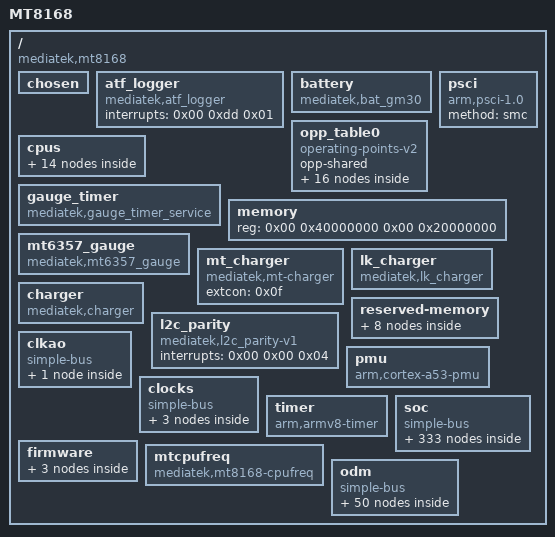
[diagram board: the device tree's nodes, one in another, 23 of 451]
/dts-v1/;

/ {
	model = "MT8168";
	compatible = "mediatek,mt8168";
	interrupt-parent = <0x01>;
	#address-cells = <0x02>;
	#size-cells = <0x02>;
	version = "hvt";

	chosen {
		bootargs = "console=tty0 vmalloc=496M androidboot.hardware=mt8168 firmware_class.path=/vendor/firmware loop.max_part=7";
		phandle = <0x8c>;
	};

	atf_logger {
		compatible = "mediatek,atf_logger";
		interrupts = <0x00 0xdd 0x01>;
	};

	battery {
		compatible = "mediatek,bat_gm30";
		DIFFERENCE_FULLOCV_ITH = <0x12c>;
		SHUTDOWN_1_TIME = <0x05>;
		KEEP_100_PERCENT = <0x01>;
		R_FG_VALUE = <0x0a>;
		EMBEDDED_SEL = <0x00>;
		PMIC_SHUTDOWN_CURRENT = <0x14>;
		FG_METER_RESISTANCE = <0x4b>;
		CAR_TUNE_VALUE = <0x61>;
		PMIC_MIN_VOL = <0x84d0>;
		POWERON_SYSTEM_IBOOT = <0x1f4>;
		SHUTDOWN_GAUGE0_VOLTAGE = <0x84d0>;
		TEMPERATURE_T0 = <0x32>;
		TEMPERATURE_T1 = <0x19>;
		TEMPERATURE_T2 = <0x0a>;
		TEMPERATURE_T3 = <0x00>;
		TEMPERATURE_T4 = <0xfffffff6>;
		g_FG_PSEUDO100_T0 = <0x64>;
		g_FG_PSEUDO100_T1 = <0x64>;
		g_FG_PSEUDO100_T2 = <0x64>;
		g_FG_PSEUDO100_T3 = <0x64>;
		g_FG_PSEUDO100_T4 = <0x64>;
		Q_MAX_SYS_VOLTAGE_BAT0 = <0xd16>;
		Q_MAX_SYS_VOLTAGE_BAT1 = <0xd16>;
		Q_MAX_SYS_VOLTAGE_BAT2 = <0xd16>;
		Q_MAX_SYS_VOLTAGE_BAT3 = <0xd16>;
		battery0_profile_t0_num = <0x64>;
		battery0_profile_t0 = <0x00 0xa584 0x2bc 0x1d4 0xa513 0x2ba 0x3a9 0xa4a3 0x2be 0x57d 0xa437 0x2c1 0x752 0xa3ca 0x2c3 0x926 0xa360 0x2c4 0xafa 0xa2f6 0x2c5 0xccf 0xa28e 0x2c7 0xea3 0xa227 0x2ca 0x1078 0xa1c1 0x2ce 0x124c 0xa15c 0x2d0 0x1421 0xa0f7 0x2cd 0x15f5 0xa095 0x2d4 0x17c9 0xa033 0x2d4 0x199e 0x9fcd 0x2c8 0x1b72 0x9f6f 0x2da 0x1d47 0x9f11 0x2da 0x1f1b 0x9eb6 0x2da 0x20ef 0x9e55 0x2da 0x22c4 0x9dfe 0x2e2 0x2498 0x9da7 0x2e4 0x266d 0x9d52 0x2e9 0x2841 0x9cff 0x2f2 0x2a16 0x9cac 0x2f5 0x2bea 0x9c5c 0x2f5 0x2dbe 0x9c0e 0x2f9 0x2f93 0x9bc2 0x301 0x3167 0x9b77 0x308 0x333c 0x9b2d 0x30e 0x3510 0x9ae4 0x317 0x36e4 0x9a9d 0x31f 0x38b9 0x9a58 0x330 0x3a8d 0x9a13 0x33e 0x3c62 0x99ce 0x352 0x3e36 0x9985 0x35f 0x400b 0x9939 0x377 0x41df 0x98db 0x36c 0x43b3 0x9862 0x336 0x4588 0x97e7 0x2fa 0x475c 0x9781 0x2df 0x4931 0x9732 0x2d8 0x4b05 0x96f2 0x2d0 0x4cd9 0x96b8 0x2cd 0x4eae 0x9683 0x2cb 0x5082 0x9651 0x2cc 0x5257 0x9622 0x2ce 0x542b 0x95f4 0x2d0 0x55ff 0x95c9 0x2d0 0x57d4 0x95a6 0x2cc 0x59a8 0x9580 0x2d0 0x5b7d 0x9558 0x2d0 0x5d51 0x9533 0x2d3 0x5f26 0x9510 0x2d7 0x60fa 0x94ed 0x2d8 0x62ce 0x94cb 0x2da 0x64a3 0x94aa 0x2db 0x6677 0x948c 0x2df 0x684c 0x946c 0x2e1 0x6a20 0x9451 0x2ec 0x6bf4 0x9434 0x2ee 0x6dc9 0x941c 0x2f5 0x6f9d 0x9402 0x2f8 0x7172 0x93ea 0x300 0x7346 0x93d1 0x304 0x751b 0x93b9 0x310 0x76ef 0x939e 0x317 0x78c3 0x9380 0x313 0x7a98 0x935b 0x301 0x7c6c 0x9312 0x2c9 0x7e41 0x92cd 0x2c9 0x8015 0x92a0 0x2cd 0x81e9 0x927c 0x2d2 0x83be 0x9258 0x2d8 0x8592 0x9231 0x2d5 0x8767 0x9209 0x2cf 0x893b 0x91e4 0x2d0 0x8b0f 0x91c3 0x2d6 0x8ce4 0x91a3 0x2dc 0x8eb8 0x9180 0x2df 0x908d 0x9155 0x2df 0x9261 0x9120 0x2de 0x9436 0x90e2 0x2d8 0x960a 0x90a8 0x2db 0x97de 0x9075 0x2e6 0x99b3 0x9033 0x2e9 0x9b87 0x8fe3 0x2db 0x9d5c 0x8fb8 0x2d9 0x9f30 0x8fa5 0x2e3 0xa104 0x8f96 0x2eb 0xa2d9 0x8f85 0x2fb 0xa4ad 0x8f70 0x30f 0xa682 0x8f50 0x324 0xa856 0x8f10 0x336 0xaa2b 0x8e6c 0x330 0xabff 0x8d1a 0x327 0xadd3 0x8b48 0x340 0xafa8 0x88f7 0x36f 0xb17c 0x85c2 0x3a0 0xb351 0x80a8 0x433 0xb525 0x72fd 0xe09>;
		battery0_profile_t1_num = <0x64>;
		battery0_profile_t1 = <0x00 0xa5c6 0x37a 0x1d4 0xa552 0x37c 0x3a9 0xa4e2 0x385 0x57d 0xa473 0x384 0x752 0xa408 0x38a 0x926 0xa39d 0x38d 0xafa 0xa334 0x390 0xccf 0xa2cc 0x392 0xea3 0xa265 0x395 0x1078 0xa1ff 0x399 0x124c 0xa19a 0x39c 0x1421 0xa136 0x3a0 0x15f5 0xa0d3 0x3a0 0x17c9 0xa071 0x3a3 0x199e 0xa010 0x3aa 0x1b72 0x9fb1 0x3ad 0x1d47 0x9f57 0x3bb 0x1f1b 0x9f05 0x3c9 0x20ef 0x9eb2 0x3ce 0x22c4 0x9e56 0x3cd 0x2498 0x9df8 0x3d2 0x266d 0x9d99 0x3d9 0x2841 0x9d3b 0x3e0 0x2a16 0x9ce2 0x3e7 0x2bea 0x9c8d 0x3f2 0x2dbe 0x9c3c 0x3ff 0x2f93 0x9bf1 0x40b 0x3167 0x9bad 0x41c 0x333c 0x9b6c 0x431 0x3510 0x9b29 0x43f 0x36e4 0x9ae2 0x44e 0x38b9 0x9a9b 0x463 0x3a8d 0x9a53 0x474 0x3c62 0x9a08 0x482 0x3e36 0x99ba 0x490 0x400b 0x9966 0x48e 0x41df 0x9908 0x47d 0x43b3 0x989c 0x44d 0x4588 0x982a 0x40d 0x475c 0x97c2 0x3d8 0x4931 0x976b 0x3b3 0x4b05 0x9721 0x39d 0x4cd9 0x96e2 0x395 0x4eae 0x96aa 0x392 0x5082 0x9676 0x391 0x5257 0x9645 0x390 0x542b 0x9617 0x38e 0x55ff 0x95ec 0x38e 0x57d4 0x95c1 0x38e 0x59a8 0x959a 0x392 0x5b7d 0x9571 0x393 0x5d51 0x954d 0x397 0x5f26 0x952a 0x39a 0x60fa 0x9508 0x39f 0x62ce 0x94e7 0x3a2 0x64a3 0x94c7 0x3a5 0x6677 0x94aa 0x3ac 0x684c 0x948e 0x3b4 0x6a20 0x9472 0x3ba 0x6bf4 0x9458 0x3bf 0x6dc9 0x943e 0x3c6 0x6f9d 0x9426 0x3c9 0x7172 0x940e 0x3cf 0x7346 0x93f8 0x3d4 0x751b 0x93e2 0x3e0 0x76ef 0x93ca 0x3de 0x78c3 0x93b2 0x3e0 0x7a98 0x9396 0x3d9 0x7c6c 0x9377 0x3cc 0x7e41 0x9357 0x3be 0x8015 0x9337 0x3b3 0x81e9 0x9317 0x3ac 0x83be 0x92f4 0x3a6 0x8592 0x92cf 0x3a2 0x8767 0x92a8 0x3a0 0x893b 0x9282 0x39e 0x8b0f 0x9262 0x3a4 0x8ce4 0x9243 0x3ad 0x8eb8 0x9220 0x3b4 0x908d 0x91f5 0x3b6 0x9261 0x91bb 0x3b1 0x9436 0x917c 0x3b1 0x960a 0x9146 0x3bb 0x97de 0x910f 0x3c5 0x99b3 0x90cb 0x3cb 0x9b87 0x907a 0x3cb 0x9d5c 0x9042 0x3ce 0x9f30 0x902a 0x3dd 0xa104 0x9019 0x3ee 0xa2d9 0x9008 0x403 0xa4ad 0x8ff2 0x424 0xa682 0x8fd2 0x44d 0xa856 0x8f9b 0x481 0xaa2b 0x8f18 0x4a6 0xabff 0x8dcd 0x498 0xadd3 0x8bf0 0x4e3 0xafa8 0x8980 0x561 0xb17c 0x861b 0x63b 0xb351 0x8085 0x88a 0xb525 0x780a 0x1aa9>;
		battery0_profile_t2_num = <0x64>;
		battery0_profile_t2 = <0x00 0xa5b8 0x5fa 0x1d4 0xa542 0x5f5 0x3a9 0xa4d1 0x5f9 0x57d 0xa463 0x5fc 0x752 0xa3f9 0x5fe 0x926 0xa38e 0x5ff 0xafa 0xa326 0x604 0xccf 0xa2bf 0x607 0xea3 0xa258 0x60a 0x1078 0xa1f2 0x60d 0x124c 0xa18c 0x610 0x1421 0xa129 0x61b 0x15f5 0xa0c5 0x623 0x17c9 0xa063 0x627 0x199e 0xa005 0x632 0x1b72 0x9fa9 0x63c 0x1d47 0x9f55 0x647 0x1f1b 0x9f05 0x65a 0x20ef 0x9eab 0x664 0x22c4 0x9e49 0x669 0x2498 0x9de5 0x679 0x266d 0x9d82 0x685 0x2841 0x9d21 0x68d 0x2a16 0x9cc4 0x698 0x2bea 0x9c6d 0x6a5 0x2dbe 0x9c1a 0x6b3 0x2f93 0x9bcb 0x6c1 0x3167 0x9b81 0x6cf 0x333c 0x9b3c 0x6e3 0x3510 0x9afa 0x6f7 0x36e4 0x9ab9 0x709 0x38b9 0x9a75 0x712 0x3a8d 0x9a27 0x710 0x3c62 0x99d7 0x70d 0x3e36 0x997e 0x6f4 0x400b 0x991f 0x6c8 0x41df 0x98ba 0x692 0x43b3 0x9854 0x653 0x4588 0x97f4 0x622 0x475c 0x979c 0x5fa 0x4931 0x974e 0x5d8 0x4b05 0x970a 0x5c2 0x4cd9 0x96cc 0x5b6 0x4eae 0x9695 0x5b0 0x5082 0x9660 0x5ae 0x5257 0x9630 0x5b1 0x542b 0x9602 0x5b1 0x55ff 0x95d5 0x5b2 0x57d4 0x95ad 0x5bb 0x59a8 0x9585 0x5bc 0x5b7d 0x955f 0x5c6 0x5d51 0x953b 0x5d0 0x5f26 0x9518 0x5d7 0x60fa 0x94f6 0x5d9 0x62ce 0x94d6 0x5e2 0x64a3 0x94b7 0x5ee 0x6677 0x9499 0x5f7 0x684c 0x947e 0x600 0x6a20 0x9464 0x609 0x6bf4 0x9449 0x610 0x6dc9 0x942f 0x617 0x6f9d 0x9418 0x621 0x7172 0x9402 0x62d 0x7346 0x93ec 0x636 0x751b 0x93d7 0x638 0x76ef 0x93c5 0x641 0x78c3 0x93b3 0x64b 0x7a98 0x93a2 0x64e 0x7c6c 0x9391 0x651 0x7e41 0x9381 0x656 0x8015 0x936f 0x65a 0x81e9 0x9358 0x65a 0x83be 0x933b 0x656 0x8592 0x931a 0x651 0x8767 0x92f8 0x64d 0x893b 0x92d4 0x64c 0x8b0f 0x92b2 0x654 0x8ce4 0x9290 0x660 0x8eb8 0x9269 0x66e 0x908d 0x923b 0x686 0x9261 0x91fe 0x68b 0x9436 0x91c0 0x698 0x960a 0x9187 0x6ae 0x97de 0x914d 0x6cd 0x99b3 0x9105 0x6e5 0x9b87 0x90b1 0x6f9 0x9d5c 0x9075 0x715 0x9f30 0x9054 0x741 0xa104 0x903c 0x77e 0xa2d9 0x9024 0x7cc 0xa4ad 0x9008 0x837 0xa682 0x8fe2 0x8cc 0xa856 0x8fa5 0x9a8 0xaa2b 0x8f1c 0xacc 0xabff 0x8dcd 0xc1f 0xadd3 0x8bc7 0xf20 0xafa8 0x891a 0x16d3 0xb17c 0x8568 0x244e 0xb351 0x84c7 0x26a5 0xb525 0x84c7 0x26a5>;
		battery0_profile_t3_num = <0x64>;
		battery0_profile_t3 = <0x00 0xa5fa 0x8de 0x1d4 0xa57b 0x8d9 0x3a9 0xa506 0x8db 0x57d 0xa495 0x8e6 0x752 0xa421 0x84d 0x926 0xa3b4 0x8be 0xafa 0xa34a 0x903 0xccf 0xa2e1 0x908 0xea3 0xa276 0x910 0x1078 0xa20b 0x90e 0x124c 0xa1a6 0x913 0x1421 0xa141 0x92a 0x15f5 0xa0dd 0x935 0x17c9 0xa079 0x93e 0x199e 0xa01a 0x93e 0x1b72 0x9fc2 0x94f 0x1d47 0x9f72 0x967 0x1f1b 0x9f21 0x981 0x20ef 0x9ec3 0x985 0x22c4 0x9e5c 0x9a9 0x2498 0x9df1 0x9b0 0x266d 0x9d87 0x9bd 0x2841 0x9d1f 0x9c7 0x2a16 0x9cbc 0x9c9 0x2bea 0x9c60 0x9cf 0x2dbe 0x9c0a 0x9db 0x2f93 0x9bba 0x9e8 0x3167 0x9b6e 0x9f0 0x333c 0x9b22 0x9f6 0x3510 0x9ad9 0xa00 0x36e4 0x9a90 0xa03 0x38b9 0x9a47 0xa06 0x3a8d 0x99fa 0x9e7 0x3c62 0x99a2 0x9d3 0x3e36 0x9943 0x9ab 0x400b 0x98e5 0x97c 0x41df 0x9886 0x944 0x43b3 0x982b 0x90d 0x4588 0x97d5 0x8f8 0x475c 0x9787 0x8dd 0x4931 0x973e 0x8ca 0x4b05 0x96fc 0x8bc 0x4cd9 0x96bf 0x8b6 0x4eae 0x9688 0x8b6 0x5082 0x9654 0x8a2 0x5257 0x9623 0x89c 0x542b 0x95f5 0x8c3 0x55ff 0x95c9 0x8c9 0x57d4 0x95a0 0x8d5 0x59a8 0x9576 0x8dd 0x5b7d 0x9550 0x8e9 0x5d51 0x952d 0x8fc 0x5f26 0x950c 0x8e9 0x60fa 0x94ec 0x915 0x62ce 0x94c9 0x918 0x64a3 0x94aa 0x92f 0x6677 0x948b 0x93d 0x684c 0x946f 0x949 0x6a20 0x9455 0x95d 0x6bf4 0x943c 0x96c 0x6dc9 0x9423 0x973 0x6f9d 0x940c 0x980 0x7172 0x93f7 0x992 0x7346 0x93e4 0x9a0 0x751b 0x93d2 0x9ac 0x76ef 0x93c2 0x9ba 0x78c3 0x93b5 0x9c5 0x7a98 0x93aa 0x9bf 0x7c6c 0x9399 0x9e2 0x7e41 0x938a 0x9e9 0x8015 0x937a 0x9f7 0x81e9 0x9364 0xa03 0x83be 0x934e 0xa03 0x8592 0x9333 0xa18 0x8767 0x9318 0xa1f 0x893b 0x92f8 0xa36 0x8b0f 0x92d4 0xa4a 0x8ce4 0x92ae 0xa68 0x8eb8 0x9282 0xa8c 0x908d 0x924d 0xaa4 0x9261 0x9214 0xac8 0x9436 0x91d9 0xae4 0x960a 0x91a0 0xaf6 0x97de 0x9161 0xb45 0x99b3 0x9113 0xb9d 0x9b87 0x90bf 0xbde 0x9d5c 0x9088 0xc0d 0x9f30 0x9066 0xcaf 0xa104 0x9046 0xd1f 0xa2d9 0x9028 0xe4c 0xa4ad 0x9002 0xfb7 0xa682 0x8fc9 0x11de 0xa856 0x8f6a 0x1574 0xaa2b 0x8ea2 0x1c71 0xabff 0x8d27 0x2ec7 0xadd3 0x8afa 0x4e8b 0xafa8 0x8806 0x5626 0xb17c 0x83c8 0x4b8c 0xb351 0x803d 0x42b1 0xb525 0x803d 0x42b1>;
		battery0_profile_t4_num = <0x64>;
		battery0_profile_t4 = <0x00 0xa602 0x1504 0x1d4 0xa576 0x14ff 0x3a9 0xa4fb 0x1520 0x57d 0xa488 0x1522 0x752 0xa41a 0x1528 0x926 0xa3ad 0x1523 0xafa 0xa343 0x1521 0xccf 0xa2da 0x151f 0xea3 0xa271 0x151d 0x1078 0xa20a 0x1519 0x124c 0xa1a5 0x1512 0x1421 0xa13f 0x150d 0x15f5 0xa0d9 0x1501 0x17c9 0xa077 0x14f8 0x199e 0xa019 0x14fc 0x1b72 0x9fc0 0x14f8 0x1d47 0x9f6c 0x1501 0x1f1b 0x9f14 0x150f 0x20ef 0x9eb2 0x1508 0x22c4 0x9e45 0x14f9 0x2498 0x9dd2 0x14ee 0x266d 0x9d5e 0x14dc 0x2841 0x9cf0 0x1427 0x2a16 0x9c7e 0x13f0 0x2bea 0x9c15 0x144c 0x2dbe 0x9bb8 0x1459 0x2f93 0x9b5f 0x1445 0x3167 0x9b09 0x1444 0x333c 0x9ab5 0x13e6 0x3510 0x9a65 0x142e 0x36e4 0x9a11 0x141b 0x38b9 0x99c2 0x1427 0x3a8d 0x9976 0x13c7 0x3c62 0x9929 0x13d6 0x3e36 0x98d8 0x13ef 0x400b 0x988b 0x13bb 0x41df 0x983f 0x13b8 0x43b3 0x97f4 0x13a7 0x4588 0x97ad 0x13bb 0x475c 0x9769 0x13cb 0x4931 0x9729 0x13b1 0x4b05 0x96ee 0x13b1 0x4cd9 0x96b4 0x13e0 0x4eae 0x967e 0x13f4 0x5082 0x964a 0x13e6 0x5257 0x9617 0x138c 0x542b 0x95eb 0x1400 0x55ff 0x95bd 0x1436 0x57d4 0x9591 0x13f4 0x59a8 0x9569 0x144a 0x5b7d 0x9540 0x147e 0x5d51 0x951c 0x1427 0x5f26 0x94f8 0x1426 0x60fa 0x94d6 0x1490 0x62ce 0x94b5 0x14e1 0x64a3 0x9495 0x150c 0x6677 0x9476 0x1533 0x684c 0x945a 0x155b 0x6a20 0x943f 0x1545 0x6bf4 0x9426 0x1513 0x6dc9 0x940f 0x15c2 0x6f9d 0x93f9 0x15db 0x7172 0x93e6 0x1620 0x7346 0x93d6 0x158e 0x751b 0x93c6 0x15f5 0x76ef 0x93b8 0x1682 0x78c3 0x93a9 0x16e4 0x7a98 0x9398 0x16f4 0x7c6c 0x9387 0x171b 0x7e41 0x9376 0x175f 0x8015 0x9365 0x17ba 0x81e9 0x9351 0x1803 0x83be 0x933a 0x183e 0x8592 0x9321 0x188b 0x8767 0x9306 0x18ed 0x893b 0x92e6 0x1969 0x8b0f 0x92c5 0x19c2 0x8ce4 0x929f 0x19ed 0x8eb8 0x9275 0x1aac 0x908d 0x924b 0x1b0c 0x9261 0x9217 0x1bc2 0x9436 0x91e1 0x1c6c 0x960a 0x91a7 0x1d34 0x97de 0x9168 0x1e20 0x99b3 0x9127 0x1f08 0x9b87 0x90e6 0x2064 0x9d5c 0x90ac 0x2216 0x9f30 0x9079 0x2419 0xa104 0x904c 0x267a 0xa2d9 0x901e 0x2a27 0xa4ad 0x8fea 0x3065 0xa682 0x8faa 0x3a91 0xa856 0x8f4f 0x4cb5 0xaa2b 0x8ed4 0x5c32 0xabff 0x8e6f 0x3e70 0xadd3 0x8c3f 0x6a79 0xafa8 0x84d0 0x57e4 0xb17c 0x84d0 0x57e4 0xb351 0x84d0 0x57e4 0xb525 0x84d0 0x57e4>;
		io-channels = <0x02 0x02>;
		io-channel-names = "bat_id_channel";
		id_volt_max = <0x5c8>;
		id_volt_min = <0x2bc>;
		MIN_BATTERY_TEMP = <0xfffffff6>;
		total_battery_number = <0x02>;
		bat_id_volt_thres = <0x3e8 0x4b0 0xffffffff>;
		battery0_profile_name = "ATL";
		battery0_profile_t0_col = <0x03>;
		battery0_profile_t1_col = <0x03>;
		battery0_profile_t2_col = <0x03>;
		battery0_profile_t3_col = <0x03>;
		battery0_profile_t4_col = <0x03>;
		battery1_profile_name = "Lishen";
		battery1_profile_t0_num = <0x64>;
		battery1_profile_t0_col = <0x03>;
		battery1_profile_t0 = <0x00 0xa59b 0x28a 0x1cf 0xa52e 0x28a 0x39f 0xa4c1 0x28e 0x56e 0xa456 0x291 0x73e 0xa3ec 0x292 0x90d 0xa382 0x292 0xadd 0xa319 0x294 0xcac 0xa2b3 0x296 0xe7b 0xa24d 0x298 0x104b 0xa1e8 0x299 0x121a 0xa185 0x29a 0x13ea 0xa122 0x29e 0x15b9 0xa0c1 0x29e 0x1789 0xa061 0x2a0 0x1958 0x9ffc 0x297 0x1b28 0x9f9d 0x2a0 0x1cf7 0x9f43 0x2a7 0x1ec6 0x9ee8 0x2a8 0x2096 0x9e8b 0x2a8 0x2265 0x9e32 0x2b0 0x2435 0x9ddd 0x2b4 0x2604 0x9d88 0x2b4 0x27d4 0x9d35 0x2b7 0x29a3 0x9ce4 0x2bd 0x2b72 0x9c95 0x2c0 0x2d42 0x9c47 0x2c4 0x2f11 0x9bfb 0x2ca 0x30e1 0x9bb1 0x2d8 0x32b0 0x9b69 0x2dc 0x3480 0x9b22 0x2e5 0x364f 0x9adb 0x2ef 0x381e 0x9a98 0x301 0x39ee 0x9a52 0x314 0x3bbd 0x9a0a 0x32c 0x3d8d 0x99be 0x342 0x3f5c 0x995e 0x33b 0x412c 0x98df 0x304 0x42fb 0x9857 0x2be 0x44cb 0x97f2 0x2a7 0x469a 0x97a4 0x29c 0x4869 0x9762 0x29e 0x4a39 0x9728 0x299 0x4c08 0x96f5 0x2a0 0x4dd8 0x96c1 0x29a 0x4fa7 0x9692 0x29f 0x5177 0x9663 0x29b 0x5346 0x9636 0x29c 0x5515 0x960b 0x29d 0x56e5 0x95e1 0x29c 0x58b4 0x95b9 0x29a 0x5a84 0x9592 0x29c 0x5c53 0x956d 0x2a2 0x5e23 0x9549 0x2a2 0x5ff2 0x9527 0x2a8 0x61c1 0x9506 0x2ab 0x6391 0x94e6 0x2ad 0x6560 0x94c7 0x2b1 0x6730 0x94af 0x2af 0x68ff 0x9494 0x2b1 0x6acf 0x9479 0x2b9 0x6c9e 0x945f 0x2c0 0x6e6d 0x9445 0x2c7 0x703d 0x942d 0x2d3 0x720c 0x9415 0x2d6 0x73dc 0x93fc 0x2e2 0x75ab 0x93de 0x2e2 0x777b 0x93b4 0x2d2 0x794a 0x936f 0x2a9 0x7b1a 0x9326 0x297 0x7ce9 0x92ef 0x29c 0x7eb8 0x92c6 0x2a0 0x8088 0x92a0 0x2a3 0x8257 0x9278 0x2a4 0x8427 0x924e 0x2a0 0x85f6 0x9224 0x29e 0x87c6 0x91fe 0x29e 0x8995 0x91de 0x29e 0x8b64 0x91bd 0x2a1 0x8d34 0x9198 0x2a7 0x8f03 0x9169 0x2a8 0x90d3 0x912e 0x2a0 0x92a2 0x90f2 0x29b 0x9472 0x90bc 0x29c 0x9641 0x9082 0x29e 0x9810 0x903a 0x298 0x99e0 0x9001 0x28f 0x9baf 0x8fea 0x28b 0x9d7f 0x8fdf 0x290 0x9f4e 0x8fd6 0x299 0xa11e 0x8fcd 0x2a9 0xa2ed 0x8fc0 0x2ba 0xa4bd 0x8faa 0x2cd 0xa68c 0x8f76 0x2db 0xa85b 0x8ee1 0x2ce 0xaa2b 0x8da4 0x2b4 0xabfa 0x8bd8 0x2c7 0xadca 0x8986 0x2e9 0xaf99 0x8665 0x325 0xb169 0x8153 0x40d 0xb338 0x75fe 0x158b>;
		battery1_profile_t1_num = <0x64>;
		battery1_profile_t1_col = <0x03>;
		battery1_profile_t1 = <0x00 0xa5ba 0x3f2 0x1cf 0xa548 0x3f4 0x39f 0xa4db 0x3fd 0x56e 0xa46f 0x3fb 0x73e 0xa406 0x402 0x90d 0xa39d 0x404 0xadd 0xa335 0x405 0xcac 0xa2cf 0x408 0xe7b 0xa269 0x409 0x104b 0xa204 0x407 0x121a 0xa1a2 0x409 0x13ea 0xa140 0x40c 0x15b9 0xa0df 0x410 0x1789 0xa07e 0x40e 0x1958 0xa022 0x415 0x1b28 0x9fc4 0x41a 0x1cf7 0x9f68 0x41c 0x1ec6 0x9f0f 0x420 0x2096 0x9eb6 0x425 0x2265 0x9e5f 0x430 0x2435 0x9e09 0x437 0x2604 0x9db5 0x43a 0x27d4 0x9d61 0x43e 0x29a3 0x9d0e 0x444 0x2b72 0x9cc0 0x452 0x2d42 0x9c73 0x45d 0x2f11 0x9c26 0x465 0x30e1 0x9bdb 0x46a 0x32b0 0x9b94 0x47d 0x3480 0x9b4e 0x492 0x364f 0x9b05 0x4a5 0x381e 0x9abe 0x4b9 0x39ee 0x9a74 0x4cc 0x3bbd 0x9a25 0x4d9 0x3d8d 0x99ce 0x4dd 0x3f5c 0x9968 0x4c5 0x412c 0x98f1 0x488 0x42fb 0x9879 0x443 0x44cb 0x9811 0x412 0x469a 0x97be 0x3f6 0x4869 0x977a 0x3ef 0x4a39 0x973b 0x3e3 0x4c08 0x9704 0x3dc 0x4dd8 0x96d0 0x3de 0x4fa7 0x969f 0x3d8 0x5177 0x9672 0x3dc 0x5346 0x9646 0x3dc 0x5515 0x961b 0x3da 0x56e5 0x95f1 0x3da 0x58b4 0x95ca 0x3db 0x5a84 0x95a4 0x3db 0x5c53 0x957f 0x3dd 0x5e23 0x955d 0x3e3 0x5ff2 0x953b 0x3e4 0x61c1 0x951b 0x3e8 0x6391 0x94fb 0x3ea 0x6560 0x94dd 0x3ef 0x6730 0x94c1 0x3f6 0x68ff 0x94a5 0x3fb 0x6acf 0x948b 0x3fe 0x6c9e 0x9472 0x403 0x6e6d 0x9459 0x40a 0x703d 0x9440 0x40c 0x720c 0x9427 0x40e 0x73dc 0x940e 0x411 0x75ab 0x93f4 0x40e 0x777b 0x93d8 0x40e 0x794a 0x93b8 0x401 0x7b1a 0x9391 0x3e5 0x7ce9 0x936c 0x3dc 0x7eb8 0x9349 0x3d3 0x8088 0x9325 0x3ca 0x8257 0x92ff 0x3c0 0x8427 0x92d9 0x3be 0x85f6 0x92b3 0x3bb 0x87c6 0x9291 0x3ba 0x8995 0x9273 0x3bc 0x8b64 0x9254 0x3c0 0x8d34 0x922f 0x3c4 0x8f03 0x9201 0x3c1 0x90d3 0x91cd 0x3c5 0x92a2 0x9192 0x3c8 0x9472 0x915f 0x3cc 0x9641 0x912a 0x3d3 0x9810 0x90e7 0x3d6 0x99e0 0x9099 0x3da 0x9baf 0x906b 0x3e1 0x9d7f 0x9057 0x3ec 0x9f4e 0x904b 0x3fc 0xa11e 0x903d 0x40d 0xa2ed 0x902c 0x426 0xa4bd 0x9013 0x446 0xa68c 0x8fdf 0x468 0xa85b 0x8f57 0x481 0xaa2b 0x8e0f 0x472 0xabfa 0x8c2f 0x49f 0xadca 0x89b7 0x4eb 0xaf99 0x862f 0x56b 0xb169 0x7fe6 0x764 0xb338 0x7666 0x1692>;
		battery1_profile_t2_num = <0x64>;
		battery1_profile_t2_col = <0x03>;
		battery1_profile_t2 = <0x00 0xa5d6 0x65e 0x1cf 0xa55f 0x663 0x39f 0xa4f0 0x66c 0x56e 0xa484 0x675 0x73e 0xa419 0x672 0x90d 0xa3b1 0x676 0xadd 0xa349 0x675 0xcac 0xa2e2 0x672 0xe7b 0xa27d 0x673 0x104b 0xa218 0x676 0x121a 0xa1b5 0x67b 0x13ea 0xa152 0x67e 0x15b9 0xa0f0 0x67d 0x1789 0xa090 0x684 0x1958 0xa031 0x688 0x1b28 0x9fd3 0x68d 0x1cf7 0x9f77 0x692 0x1ec6 0x9f1c 0x696 0x2096 0x9ec3 0x6a3 0x2265 0x9e6b 0x6af 0x2435 0x9e13 0x6b7 0x2604 0x9dbd 0x6c1 0x27d4 0x9d67 0x6cc 0x29a3 0x9d14 0x6d9 0x2b72 0x9cc4 0x6ee 0x2d42 0x9c75 0x6fb 0x2f11 0x9c25 0x707 0x30e1 0x9bd8 0x715 0x32b0 0x9b8c 0x720 0x3480 0x9b41 0x735 0x364f 0x9af5 0x740 0x381e 0x9aa6 0x743 0x39ee 0x9a53 0x73f 0x3bbd 0x99fa 0x72b 0x3d8d 0x9998 0x701 0x3f5c 0x9930 0x6c5 0x412c 0x98c5 0x681 0x42fb 0x985f 0x642 0x44cb 0x9805 0x615 0x469a 0x97b7 0x5fd 0x4869 0x976d 0x5dd 0x4a39 0x972d 0x5d0 0x4c08 0x96f5 0x5cb 0x4dd8 0x96be 0x5c2 0x4fa7 0x968b 0x5bd 0x5177 0x965c 0x5bf 0x5346 0x962f 0x5c1 0x5515 0x9603 0x5c3 0x56e5 0x95d9 0x5c3 0x58b4 0x95b1 0x5c4 0x5a84 0x958c 0x5c8 0x5c53 0x9567 0x5c9 0x5e23 0x9543 0x5cb 0x5ff2 0x9520 0x5cd 0x61c1 0x94ff 0x5d0 0x6391 0x94de 0x5d7 0x6560 0x94c1 0x5db 0x6730 0x94a5 0x5e0 0x68ff 0x9489 0x5e7 0x6acf 0x946e 0x5ec 0x6c9e 0x9454 0x5f2 0x6e6d 0x943c 0x5f8 0x703d 0x9425 0x5fc 0x720c 0x940e 0x5ff 0x73dc 0x93f8 0x5fd 0x75ab 0x93e2 0x5fc 0x777b 0x93ce 0x602 0x794a 0x93ba 0x601 0x7b1a 0x93a6 0x601 0x7ce9 0x9392 0x601 0x7eb8 0x937a 0x5ff 0x8088 0x9362 0x5ff 0x8257 0x9343 0x5f6 0x8427 0x931f 0x5ee 0x85f6 0x92fb 0x5eb 0x87c6 0x92d9 0x5f0 0x8995 0x92b8 0x5fd 0x8b64 0x9296 0x60d 0x8d34 0x926e 0x61e 0x8f03 0x923d 0x62f 0x90d3 0x9201 0x63e 0x92a2 0x91c4 0x653 0x9472 0x918d 0x66d 0x9641 0x9155 0x68d 0x9810 0x910a 0x6a3 0x99e0 0x90b8 0x6ba 0x9baf 0x9088 0x6da 0x9d7f 0x906e 0x700 0x9f4e 0x905b 0x72a 0xa11e 0x9049 0x75f 0xa2ed 0x9037 0x7a7 0xa4bd 0x901e 0x800 0xa68c 0x8fef 0x86d 0xa85b 0x8f79 0x8e7 0xaa2b 0x8e4e 0x948 0xabfa 0x8c64 0xa13 0xadca 0x89d2 0xb6c 0xaf99 0x8620 0xdfb 0xb169 0x7f59 0x1618 0xb338 0x727c 0xccb>;
		battery1_profile_t3_num = <0x64>;
		battery1_profile_t3_col = <0x03>;
		battery1_profile_t3 = <0x00 0xa616 0x8b6 0x1cf 0xa593 0xa19 0x39f 0xa51d 0xa41 0x56e 0xa4ac 0xa4d 0x73e 0xa43a 0x9b6 0x90d 0xa3ce 0xa15 0xadd 0xa364 0xa6f 0xcac 0xa2fc 0xa6c 0xe7b 0xa293 0xa6d 0x104b 0xa229 0xa66 0x121a 0xa1c5 0xa58 0x13ea 0xa162 0xa73 0x15b9 0xa0ff 0xa73 0x1789 0xa09e 0xa86 0x1958 0xa03f 0xa71 0x1b28 0x9fe2 0xa79 0x1cf7 0x9f85 0xa7f 0x1ec6 0x9f2a 0xa90 0x2096 0x9ecf 0xa93 0x2265 0x9e75 0xaa5 0x2435 0x9e1b 0xab4 0x2604 0x9dc3 0xabb 0x27d4 0x9d6c 0xac8 0x29a3 0x9d18 0xad5 0x2b72 0x9cc5 0xada 0x2d42 0x9c73 0xae6 0x2f11 0x9c23 0xaf1 0x30e1 0x9bd3 0xafa 0x32b0 0x9b84 0xaf8 0x3480 0x9b32 0xafe 0x364f 0x9ae0 0xaf9 0x381e 0x9a89 0xaf2 0x39ee 0x9a2e 0xaca 0x3bbd 0x99cc 0xaa2 0x3d8d 0x9966 0xa74 0x3f5c 0x9900 0xa35 0x412c 0x989d 0x9f8 0x42fb 0x9842 0x9c3 0x44cb 0x97ee 0x999 0x469a 0x97a0 0x98b 0x4869 0x975b 0x97b 0x4a39 0x971c 0x977 0x4c08 0x96e1 0x970 0x4dd8 0x96aa 0x96f 0x4fa7 0x9677 0x975 0x5177 0x9648 0x944 0x5346 0x9619 0x95f 0x5515 0x95ec 0x981 0x56e5 0x95c2 0x987 0x58b4 0x959a 0x98e 0x5a84 0x9574 0x998 0x5c53 0x954e 0x99f 0x5e23 0x952b 0x9a7 0x5ff2 0x9509 0x993 0x61c1 0x94ea 0x9d0 0x6391 0x94c7 0x9c4 0x6560 0x94aa 0x9d8 0x6730 0x948b 0x9e1 0x68ff 0x9471 0x9f1 0x6acf 0x9457 0xa02 0x6c9e 0x943e 0xa0b 0x6e6d 0x9426 0xa0d 0x703d 0x9410 0xa18 0x720c 0x93fc 0xa2a 0x73dc 0x93ea 0xa3a 0x75ab 0x93da 0xa4f 0x777b 0x93ca 0xa5d 0x794a 0x93bb 0xa6b 0x7b1a 0x93ad 0xa63 0x7ce9 0x9398 0xa9f 0x7eb8 0x9386 0xaba 0x8088 0x936f 0xadc 0x8257 0x9356 0xb00 0x8427 0x933b 0xb1a 0x85f6 0x931b 0xb4c 0x87c6 0x92fa 0xb80 0x8995 0x92d6 0xbbe 0x8b64 0x92ae 0xc0d 0x8d34 0x9283 0xc5e 0x8f03 0x924f 0xcc9 0x90d3 0x9214 0xd14 0x92a2 0x91d8 0xd89 0x9472 0x919e 0xdef 0x9641 0x9163 0xe14 0x9810 0x911a 0xe88 0x99e0 0x90ca 0xf21 0x9baf 0x908d 0xfa9 0x9d7f 0x9068 0xffb 0x9f4e 0x904f 0x1095 0xa11e 0x9039 0x1124 0xa2ed 0x9023 0x11e5 0xa4bd 0x9008 0x131f 0xa68c 0x8fdb 0x144b 0xa85b 0x8f7e 0x15e4 0xaa2b 0x8e99 0x17ac 0xabfa 0x8cd2 0x1a52 0xadca 0x8a56 0x200a 0xaf99 0x86b2 0x311b 0xb169 0x80c1 0x43fa 0xb338 0x79b3 0x325a>;
		battery1_profile_t4_num = <0x64>;
		battery1_profile_t4_col = <0x03>;
		battery1_profile_t4 = <0x00 0xa61c 0x1540 0x1cf 0xa569 0x18d5 0x39f 0xa4d3 0x196b 0x56e 0xa44e 0x197c 0x73e 0xa3d1 0x1988 0x90d 0xa35b 0x1982 0xadd 0xa2eb 0x1984 0xcac 0xa27c 0x1981 0xe7b 0xa210 0x1979 0x104b 0xa1a8 0x1970 0x121a 0xa140 0x195a 0x13ea 0xa0db 0x1953 0x15b9 0xa078 0x1949 0x1789 0xa017 0x193c 0x1958 0x9fb6 0x1937 0x1b28 0x9f56 0x192c 0x1cf7 0x9ef8 0x1926 0x1ec6 0x9e9a 0x1924 0x2096 0x9e3b 0x1910 0x2265 0x9ddb 0x18f8 0x2435 0x9d7d 0x18ea 0x2604 0x9d20 0x18de 0x27d4 0x9cc8 0x1842 0x29a3 0x9c72 0x1793 0x2b72 0x9c17 0x1822 0x2d42 0x9bbd 0x1859 0x2f11 0x9b63 0x180d 0x30e1 0x9b06 0x1847 0x32b0 0x9aad 0x1770 0x3480 0x9a53 0x17d5 0x364f 0x99f5 0x17c7 0x381e 0x9998 0x17b9 0x39ee 0x993f 0x175a 0x3bbd 0x98e6 0x1736 0x3d8d 0x9890 0x174d 0x3f5c 0x983f 0x1744 0x412c 0x97f2 0x1722 0x42fb 0x97a7 0x1716 0x44cb 0x9760 0x1710 0x469a 0x971d 0x1737 0x4869 0x96de 0x1728 0x4a39 0x96a1 0x16ee 0x4c08 0x966c 0x172c 0x4dd8 0x9637 0x174f 0x4fa7 0x9606 0x176a 0x5177 0x95d5 0x16fb 0x5346 0x95a8 0x1719 0x5515 0x957c 0x1776 0x56e5 0x9552 0x1767 0x58b4 0x952c 0x1760 0x5a84 0x9506 0x17bd 0x5c53 0x94e2 0x17b9 0x5e23 0x94c1 0x173a 0x5ff2 0x94a3 0x176a 0x61c1 0x9487 0x180f 0x6391 0x946e 0x1832 0x6560 0x9458 0x1862 0x6730 0x9446 0x18a3 0x68ff 0x9434 0x18d9 0x6acf 0x9425 0x1865 0x6c9e 0x9416 0x18ec 0x6e6d 0x9407 0x1998 0x703d 0x93f7 0x1a07 0x720c 0x93e7 0x1a31 0x73dc 0x93d8 0x1a2c 0x75ab 0x93c5 0x1b06 0x777b 0x93b3 0x1c04 0x794a 0x93a1 0x1cdb 0x7b1a 0x9388 0x1d45 0x7ce9 0x936c 0x1e0d 0x7eb8 0x9353 0x1f15 0x8088 0x9335 0x2030 0x8257 0x9317 0x213e 0x8427 0x92f5 0x2251 0x85f6 0x92d1 0x2372 0x87c6 0x92aa 0x24c4 0x8995 0x9283 0x2628 0x8b64 0x9259 0x2752 0x8d34 0x922c 0x2861 0x8f03 0x91fc 0x299e 0x90d3 0x91cb 0x2a81 0x92a2 0x9196 0x2be5 0x9472 0x915f 0x2ce2 0x9641 0x9122 0x2e13 0x9810 0x90e2 0x2f36 0x99e0 0x90a7 0x3052 0x9baf 0x9073 0x31c7 0x9d7f 0x9049 0x3346 0x9f4e 0x9026 0x34b0 0xa11e 0x9006 0x3602 0xa2ed 0x8fe4 0x37b0 0xa4bd 0x8fb9 0x39f2 0xa68c 0x8f7a 0x3ce8 0xa85b 0x8f05 0x419f 0xaa2b 0x8e2e 0x475f 0xabfa 0x8cb5 0x5447 0xadca 0x8a4d 0x7e73 0xaf99 0x862f 0x5b55 0xb169 0x82b2 0x529e 0xb338 0x82b2 0x529e>;
		idme_battery_names = "Sunwoda/ATL\0Desay/LiShen\0Desay/ATL";
		idme_battery_id = <0x1311 0x1337 0x1331>;
		ui_fast_tracking_en = <0x00>;
		phandle = <0x8d>;
	};

	opp_table0 {
		compatible = "operating-points-v2";
		opp-shared;
		phandle = <0x0c>;

		opp-850000000 {
			opp-hz = <0x00 0x32a9f880>;
			opp-microvolt = <0x9eb10>;
		};

		opp-918000000 {
			opp-hz = <0x00 0x36b79180>;
			opp-microvolt = <0xa344e>;
		};

		opp-987000000 {
			opp-hz = <0x00 0x3ad46cc0>;
			opp-microvolt = <0xa7d8c>;
		};

		opp-1056000000 {
			opp-hz = <0x00 0x3ef14800>;
			opp-microvolt = <0xac6ca>;
		};

		opp-1125000000 {
			opp-hz = <0x00 0x430e2340>;
			opp-microvolt = <0xb1008>;
		};

		opp-1216000000 {
			opp-hz = <0x00 0x487ab000>;
			opp-microvolt = <0xb71b0>;
		};

		opp-1308000000 {
			opp-hz = <0x00 0x4df67f00>;
			opp-microvolt = <0xbd358>;
		};

		opp-1400000000 {
			opp-hz = <0x00 0x53724e00>;
			opp-microvolt = "\0\f5";
		};

		opp-1466000000 {
			opp-hz = <0x00 0x57616280>;
			opp-microvolt = <0xc96a8>;
		};

		opp-1533000000 {
			opp-hz = <0x00 0x5b5fb940>;
			opp-microvolt = <0xcf850>;
		};

		opp-1633000000 {
			opp-hz = <0x00 0x61559a40>;
			opp-microvolt = <0xd8acc>;
		};

		opp-1700000000 {
			opp-hz = <0x00 0x6553f100>;
			opp-microvolt = <0xdec74>;
		};

		opp-1767000000 {
			opp-hz = <0x00 0x695247c0>;
			opp-microvolt = <0xe4e1c>;
		};

		opp-1834000000 {
			opp-hz = <0x00 0x6d509e80>;
			opp-microvolt = <0xeafc4>;
		};

		opp-1917000000 {
			opp-hz = <0x00 0x72431940>;
			opp-microvolt = <0xf29d6>;
		};

		opp-2001000000 {
			opp-hz = <0x00 0x7744d640>;
			opp-microvolt = <0xfa3e8>;
		};
	};

	cpus {
		#address-cells = <0x01>;
		#size-cells = <0x00>;
		phandle = <0x8e>;

		cpu-map {

			cluster0 {
				phandle = <0x8f>;

				core0 {
					cpu = <0x03>;
				};

				core1 {
					cpu = <0x04>;
				};

				core2 {
					cpu = <0x05>;
				};

				core3 {
					cpu = <0x06>;
				};
			};
		};

		cpu@0 {
			device_type = "cpu";
			compatible = "arm,cortex-a53";
			reg = <0x00>;
			clock-frequency = <0x989680>;
			enable-method = "psci";
			cpu-idle-states = <0x07 0x08 0x09>;
			clocks = <0x0a 0x00 0x0b 0x01 0x0b 0x00>;
			clock-names = "cpu\0intermediate\0armpll";
			operating-points-v2 = <0x0c>;
			proc-supply = <0x0d>;
			sram-supply = <0x0e>;
			phandle = <0x03>;
		};

		cpu@1 {
			device_type = "cpu";
			compatible = "arm,cortex-a53";
			reg = <0x01>;
			clock-frequency = <0x989680>;
			enable-method = "psci";
			cpu-idle-states = <0x07 0x08 0x09>;
			clocks = <0x0a 0x00 0x0b 0x01 0x0b 0x00>;
			clock-names = "cpu\0intermediate\0armpll";
			operating-points-v2 = <0x0c>;
			proc-supply = <0x0d>;
			sram-supply = <0x0e>;
			phandle = <0x04>;
		};

		cpu@2 {
			device_type = "cpu";
			compatible = "arm,cortex-a53";
			reg = <0x02>;
			clock-frequency = <0x989680>;
			enable-method = "psci";
			cpu-idle-states = <0x07 0x08 0x09>;
			clocks = <0x0a 0x00 0x0b 0x01 0x0b 0x00>;
			clock-names = "cpu\0intermediate\0armpll";
			operating-points-v2 = <0x0c>;
			proc-supply = <0x0d>;
			sram-supply = <0x0e>;
			phandle = <0x05>;
		};

		cpu@3 {
			device_type = "cpu";
			compatible = "arm,cortex-a53";
			reg = <0x03>;
			clock-frequency = <0x989680>;
			enable-method = "psci";
			cpu-idle-states = <0x07 0x08 0x09>;
			clocks = <0x0a 0x00 0x0b 0x01 0x0b 0x00>;
			clock-names = "cpu\0intermediate\0armpll";
			operating-points-v2 = <0x0c>;
			proc-supply = <0x0d>;
			sram-supply = <0x0e>;
			phandle = <0x06>;
		};

		idle-states {
			entry-method = "psci";

			mcdi-cpu {
				compatible = "arm,idle-state";
				local-timer-stop;
				arm,psci-suspend-param = <0x10001>;
				entry-latency-us = <0x12c>;
				exit-latency-us = <0xc8>;
				min-residency-us = <0x3e8>;
				phandle = <0x07>;
			};

			mcdi-cluster {
				compatible = "arm,idle-state";
				local-timer-stop;
				arm,psci-suspend-param = <0x1010001>;
				entry-latency-us = <0x15e>;
				exit-latency-us = <0xfa>;
				min-residency-us = <0x4b0>;
				phandle = <0x08>;
			};

			dpidle {
				compatible = "arm,idle-state";
				local-timer-stop;
				arm,psci-suspend-param = <0x1010004>;
				entry-latency-us = <0x12c>;
				exit-latency-us = <0x320>;
				min-residency-us = <0xce4>;
				phandle = <0x09>;
			};
		};
	};

	gauge_timer {
		compatible = "mediatek,gauge_timer_service";
	};

	psci {
		compatible = "arm,psci-1.0";
		method = "smc";
	};

	memory {
		device_type = "memory";
		reg = <0x00 0x40000000 0x00 0x20000000>;
	};

	mt6357_gauge {
		compatible = "mediatek,mt6357_gauge";
		gauge_name = "gauge";
		alias_name = "MT6357";
	};

	mt_charger {
		compatible = "mediatek,mt-charger";
		extcon = <0x0f>;
		phandle = <0x90>;
	};

	lk_charger {
		compatible = "mediatek,lk_charger";
		enable_anime;
		power_path_support;
		max_charger_voltage = <0x632ea0>;
		fast_charge_voltage = <0x2dc6c0>;
		usb_charger_current = <0x7a120>;
		ac_charger_current = <0x1b7740>;
		ac_charger_input_current = <0x1b7740>;
		non_std_ac_charger_current = <0x16e360>;
		charging_host_charger_current = <0x16e360>;
		temp_t4_threshold = <0x37>;
		temp_t3_threshold = <0x2d>;
		temp_t1_threshold = <0x0f>;
		wireless_charger_current = <0xf4240>;
		wireless_charger_input_current = <0xf4240>;
		temp_t0_threshold = <0x00>;
		temp_t3_input_current = <0xf4240>;
		temp_t3_charger_current = <0x124f80>;
		temp_t1_input_current = <0x7a120>;
		temp_t1_charger_current = <0x7a120>;
		phandle = <0x91>;
	};

	charger {
		compatible = "mediatek,charger";
		algorithm_name = "SwitchCharging";
		power_path_support;
		battery_cv = <0x4127b0>;
		max_charger_voltage = <0x632ea0>;
		min_charger_voltage = <0x419ce0>;
		usb_charger_current_suspend = <0x00>;
		usb_charger_current_unconfigured = <0x11170>;
		usb_charger_current_configured = <0x7a120>;
		usb_charger_current = <0x7a120>;
		ac_charger_current = <0x2dc6c0>;
		ac_charger_input_current = <0x2625a0>;
		non_std_ac_charger_current = <0x16e360>;
		charging_host_charger_current = <0x16e360>;
		apple_1_0a_charger_current = <0x9eb10>;
		apple_2_1a_charger_current = "\0\f5";
		jeita_temp_above_t4_cv = <0x3e8fa0>;
		jeita_temp_t3_to_t4_cv = <0x3e8fa0>;
		jeita_temp_t2_to_t3_cv = <0x4127b0>;
		jeita_temp_t1_to_t2_cv = <0x4127b0>;
		jeita_temp_t0_to_t1_cv = <0x4127b0>;
		jeita_temp_below_t0_cv = <0x4127b0>;
		temp_t4_thres = <0x37>;
		temp_t4_thres_minus_x_degree = <0x34>;
		temp_t3_thres = <0x2d>;
		temp_t3_thres_minus_x_degree = <0x28>;
		temp_t2_thres = <0x19>;
		temp_t2_thres_plus_x_degree = <0x19>;
		temp_t1_thres = <0x0f>;
		temp_t1_thres_plus_x_degree = <0x0f>;
		temp_t0_thres = <0x00>;
		temp_t0_thres_plus_x_degree = <0x06>;
		temp_neg_10_thres = <0x00>;
		enable_min_charge_temp;
		min_charge_temp = <0x00>;
		min_charge_temp_plus_x_degree = <0x06>;
		max_charge_temp = <0x32>;
		max_charge_temp_minus_x_degree = <0x2f>;
		cable_imp_threshold = <0x2bb>;
		vbat_cable_imp_threshold = <0x3b8260>;
		bif_threshold1 = <0x40d990>;
		bif_threshold2 = <0x419ce0>;
		bif_cv_under_threshold2 = <0x43e6d0>;
		enable_bat_eoc_protect;
		enable_sw_safety_timer;
		enable_top_off_mode_debounce;
		soc_exit_eoc = <0x60>;
		max_charging_time = <0x11940>;
		vbat_exit_top_off_mode = <0xfa0>;
		wireless_5w_charger_current = <0xf4240>;
		enable_sw_jeita;
		temp_t0_charging_current_limit = <0x7a120>;
		temp_t3_charging_current_limit = <0x2191c0>;
		top_off_mode_time_threshold = <0x93a80>;
		top_off_mode_cv = <0x3e8fa0>;
		top_off_difference_full_cv = <0x9c4>;
		normal_difference_full_cv = <0x1f4>;
		thermal_throttling_by_psy;
		power_detection_en;
		aicl_trigger_iusb = <0x2dc6c0>;
		aicl_trigger_ichg = <0x2dc6c0>;
		adapter_9w_aicl_min = <0x1b7740>;
		adapter_12w_aicl_min = <0x249f00>;
		adapter_5w_iusb_lim = <0x10c8e0>;
		adapter_9w_iusb_lim = <0x1cfde0>;
		adapter_12w_iusb_lim = <0x2625a0>;
		dcap_support;
		phandle = <0x92>;
	};

	reserved-memory {
		#address-cells = <0x02>;
		#size-cells = <0x02>;
		ranges;
		phandle = <0x93>;

		mdump-reserved-memory@0x602c0000 {
			compatible = "amazon,mdump-reserve-memory";
			reg = <0x00 0x602c0000 0x00 0x40000>;
		};

		adsp-reserved-memory@50000000 {
			compatible = "mediatek,adsp-reserved-memory";
			no-map;
			reg = <0x00 0x50000000 0x00 0x1800000>;
			phandle = <0x73>;
		};

		ram_console-reserved-memory {
			compatible = "mediatek,ram_console";
			reg = <0x00 0x54400000 0x00 0x22000>;
		};

		pstore-reserved-memory {
			compatible = "mediatek,pstore";
			reg = <0x00 0x54422000 0x00 0xe0000>;
		};

		minirdump-reserved-memory {
			compatible = "mediatek,minirdump";
			reg = <0x00 0x54502000 0x00 0x10000>;
		};

		atf-reserved-memory {
			compatible = "mediatek,mt8168-atf-reserved-memory";
			no-map;
			reg = <0x00 0x54600000 0x00 0x30000>;
			phandle = <0x94>;
		};

		consys-reserve-memory {
			compatible = "mediatek,consys-reserve-memory";
			no-map;
			size = <0x00 0x400000>;
			alignment = <0x00 0x1000000>;
			alloc-ranges = <0x00 0x40000000 0x00 0x80000000>;
		};

		wifi-reserve-memory {
			compatible = "mediatek,wifi-reserve-memory";
			no-map;
			size = <0x00 0x300000>;
			alignment = <0x00 0x1000000>;
			alloc-ranges = <0x00 0x40000000 0x00 0x80000000>;
		};
	};

	l2c_parity {
		compatible = "mediatek,l2c_parity-v1";
		interrupts = <0x00 0x00 0x04>;
	};

	pmu {
		compatible = "arm,cortex-a53-pmu\0arm,cortex-a7-pmu";
		interrupt-parent = <0x10>;
		interrupts = <0x01 0x07 0x08>;
	};

	clkao {
		compatible = "simple-bus";
		status = "okay";
		phandle = <0x95>;

		bring-up {
			compatible = "mediatek,clk-bring-up";
			clocks = <0x0b 0x00 0x0b 0x01 0x11 0x11 0x11 0x11 0x11 0x11 0x11 0x11 0x11 0x11 0x11 0x11 0x11 0x11 0x11 0x11 0x11 0x11 0x11 0x11 0x11 0x11 0x11 0x11 0x11 0x11 0x11 0x11 0x11 0x11 0x11 0x11 0x11 0x12 0x01 0x12 0x02 0x12 0x03 0x11 0x11 0x11 0x11 0x11 0x11 0x11 0x11 0x11 0x11 0x11 0x11 0x11 0x11 0x11 0x11 0x11 0x12 0x19 0x11 0x11 0x11 0x11 0x11 0x11 0x11 0x11 0x11 0x11 0x11 0x11 0x11 0x11 0x11 0x11 0x11 0x11 0x12 0x2e 0x12 0x2f 0x12 0x30 0x11 0x11 0x11 0x11 0x11 0x11 0x11 0x11 0x11 0x11 0x11 0x11 0x11 0x11 0x11 0x11 0x11 0x11 0x11 0x11 0x11 0x11 0x11 0x11 0x11 0x11 0x11 0x11 0x11 0x11 0x11 0x11 0x11 0x11 0x11 0x11 0x11 0x11 0x11 0x11 0x11 0x11 0x11 0x11 0x11 0x11 0x11 0x11 0x11 0x11 0x11 0x11 0x11 0x11 0x11 0x11>;
		};
	};

	clocks {
		#address-cells = <0x02>;
		#size-cells = <0x02>;
		compatible = "simple-bus";
		ranges;

		clk26m {
			compatible = "fixed-clock";
			#clock-cells = <0x00>;
			clock-frequency = <0x18cba80>;
			phandle = <0x11>;
		};

		clk32k {
			compatible = "fixed-clock";
			#clock-cells = <0x00>;
			clock-frequency = <0x7d00>;
			phandle = <0x96>;
		};

		dummy26m {
			compatible = "fixed-clock";
			clock-frequency = <0x18cba80>;
			#clock-cells = <0x00>;
			phandle = <0x97>;
		};
	};

	timer {
		compatible = "arm,armv8-timer";
		interrupt-parent = <0x10>;
		interrupts = <0x01 0x0d 0xf08 0x01 0x0e 0xf08 0x01 0x0b 0xf08 0x01 0x0a 0xf08>;
		clock-frequency = <0xc65d40>;
		phandle = <0x98>;
	};

	soc {
		#address-cells = <0x02>;
		#size-cells = <0x02>;
		compatible = "simple-bus";
		ranges;

		chipid@08000000 {
			compatible = "mediatek,chipid";
			reg = <0x00 0x8000000 0x00 0x04 0x00 0x8000004 0x00 0x04 0x00 0x8000008 0x00 0x04 0x00 0x800000c 0x00 0x04>;
			phandle = <0x99>;
		};

		interrupt-controller@c000000 {
			compatible = "arm,gic-v3";
			interrupt-controller;
			#interrupt-cells = <0x03>;
			#address-cells = <0x02>;
			#size-cells = <0x02>;
			#redistributor-regions = <0x01>;
			interrupt-parent = <0x10>;
			reg = <0x00 0xc000000 0x00 0x80000 0x00 0xc080000 0x00 0x80000>;
			interrupts = <0x01 0x09 0xf04>;
			phandle = <0x10>;
		};

		topckgen@10000000 {
			compatible = "mediatek,mt8168-topckgen\0syscon";
			reg = <0x00 0x10000000 0x00 0x1000>;
			#clock-cells = <0x01>;
			phandle = <0x13>;
		};

		btcvsd@10001000 {
			compatible = "mediatek,audio_bt_cvsd";
			offset = <0xf00 0x800 0x140 0x144 0x148>;
			reg = <0x00 0x10001000 0x00 0x1000 0x00 0x18050000 0x00 0x1000 0x00 0x18080000 0x00 0x10000>;
			interrupts = <0x00 0xd2 0x08>;
		};

		infracfg@10001000 {
			compatible = "mediatek,mt8168-infracfg\0syscon";
			reg = <0x00 0x10001000 0x00 0x1000>;
			#clock-cells = <0x01>;
			phandle = <0x12>;
		};

		mt_soc_btcvsd_rx_pcm@10001000 {
			compatible = "mediatek,mt_soc_btcvsd_rx_pcm";
		};

		mt_soc_btcvsd_tx_pcm@10001000 {
			compatible = "mediatek,mt_soc_btcvsd_tx_pcm";
		};

		syscfg_pctl_a@10005000 {
			compatible = "mediatek,pctl-a-syscfg\0syscon";
			reg = <0x00 0x10005000 0x00 0x1000>;
			phandle = <0x1a>;
		};

		syscon@10006000 {
			compatible = "mediatek,mt8168-scpsys\0syscon";
			#power-domain-cells = <0x01>;
			reg = <0x00 0x10006000 0x00 0x1000>;
			clocks = <0x13 0x4e 0x12 0x21 0x12 0x24 0x13 0x42 0x13 0x40 0x13 0x60 0x13 0x8c 0x14 0x16 0x14 0x18 0x14 0x19 0x14 0x17 0x15 0x00 0x15 0x03 0x15 0x04 0x15 0x05 0x15 0x06 0x15 0x07 0x12 0x3a 0x16 0x00 0x16 0x01 0x16 0x02 0x16 0x03 0x16 0x04 0x16 0x05 0x13 0x89 0x13 0x8a>;
			clock-names = "audio\0audio1\0audio2\0mfg\0mm\0dsp\0dsp1\0mm-0\0mm-1\0mm-2\0mm-3\0cam-0\0cam-1\0cam-2\0cam-3\0cam-4\0cam-5\0apu\0apu-1\0apu-2\0apu-3\0apu-4\0apu-5\0apu-6\0conn-0\0conn-1";
			infracfg = <0x12>;
			smi_comm = <0x17>;
			infracfg_nao = <0x18>;
			conn-supply = <0x19>;
			phandle = <0x21>;
		};

		toprgu@10007000 {
			compatible = "mediatek,mt8168-rgu\0mediatek,mt6589-wdt";
			reg = <0x00 0x10007000 0x00 0x1000>;
			interrupts = <0x00 0x53 0x02>;
			#reset-cells = <0x01>;
			phandle = <0x6d>;
		};

		apxgpt@10008000 {
			compatible = "mediatek,mt8168-timer\0mediatek,mt6577-timer";
			reg = <0x00 0x10008000 0x00 0x1000>;
			interrupts = <0x00 0x72 0x08>;
			clocks = <0x13 0x35>;
			clock-names = "clk13m";
			phandle = <0x9a>;
		};

		pinctrl@1000b000 {
			compatible = "mediatek,mt8168-pinctrl";
			reg = <0x00 0x1000b000 0x00 0x1000>;
			mediatek,pctl-regmap = <0x1a>;
			pins-are-numbered;
			gpio-controller;
			#gpio-cells = <0x02>;
			interrupt-controller;
			#interrupt-cells = <0x02>;
			interrupts = <0x00 0x73 0x04>;
			pinctrl-names = "default";
			phandle = <0x32>;

			alspspincfg {
				phandle = <0x42>;

				pins_cmd_dat {
					pinmux = <0xa00>;
					slew-rate = <0x00>;
					bias-pull-up = <0x00>;
				};
			};

			alspsdefaultcfg {
				phandle = <0x41>;
			};

			consys_default {
				phandle = <0x6e>;
			};

			gpslna@0 {
				phandle = <0x6f>;
			};

			gpslna@1 {
				phandle = <0x70>;
			};

			gpslna@2 {
				phandle = <0x71>;
			};

			accdetdefault {
				phandle = <0x75>;
			};

			accdeteint@0 {
				phandle = <0x76>;

				pins_cmd_dat {
					pinmux = <0x900>;
					slew-rate = <0x00>;
					bias-disable;
				};
			};

			mosion {
				phandle = <0x7f>;

				pins_cmd_dat {
					pinmux = <0x3101 0x3201 0x3301 0x3401>;
					drive-strength = <0x06>;
				};
			};

			mosioff {
				phandle = <0x80>;

				pins_cmd_dat {
					pinmux = <0x3100 0x3200 0x3300 0x3400>;
				};
			};

			misoon {
				phandle = <0x81>;

				pins_cmd_dat {
					pinmux = <0x3501 0x3601 0x3701 0x3801>;
					drive-strength = <0x06>;
				};
			};

			misooff {
				phandle = <0x82>;

				pins_cmd_dat {
					pinmux = <0x3500 0x3600 0x3700 0x3800>;
				};
			};

			audiodefault {
				phandle = <0x83>;
			};

			rt551x_irq_init {
				phandle = <0x45>;

				pins_cmd_dat {
					pinmux = <0x5000>;
					bias-pull-down;
				};
			};

			audiodmic {
				phandle = <0x84>;

				pins_cmd_dat {
					pinmux = <0x7501 0x7601>;
				};
			};

			audiopcm {
				phandle = <0x85>;
			};

			audioi2s0 {
				phandle = <0x86>;
			};

			audioi2s1 {
				phandle = <0x87>;
			};

			audioi2s2 {
				phandle = <0x88>;
			};

			audioi2s3 {
				phandle = <0x89>;
			};

			audiotdmout {
				phandle = <0x8a>;
			};

			audiotdmin {
				phandle = <0x8b>;
			};

			camdefault {
				phandle = <0x5d>;

				pins_cmd0_rst_data {
					pinmux = <0x200>;
					slew-rate = <0x01>;
					output-low;
				};

				pins_cmd0_pnd_data {
					pinmux = <0x300>;
					slew-rate = <0x01>;
					output-high;
				};

				pins_cmd1_rst_data {
					pinmux = <0x00>;
					slew-rate = <0x01>;
					output-low;
				};

				pins_cmd1_pnd_data {
					pinmux = <0x100>;
					slew-rate = <0x01>;
					output-high;
				};
			};

			cam0@0 {
				phandle = <0x5e>;

				pins_cmd_dat {
					pinmux = <0x200>;
					slew-rate = <0x01>;
					output-low;
				};
			};

			cam0@1 {
				phandle = <0x5f>;

				pins_cmd_dat {
					pinmux = <0x200>;
					slew-rate = <0x01>;
					output-high;
				};
			};

			cam0@2 {
				phandle = <0x60>;

				pins_cmd_dat {
					pinmux = <0x300>;
					slew-rate = <0x01>;
					output-low;
				};
			};

			cam0@3 {
				phandle = <0x61>;

				pins_cmd_dat {
					pinmux = <0x300>;
					slew-rate = <0x01>;
					output-high;
				};
			};

			cam1@0 {
				phandle = <0x62>;

				pins_cmd_dat {
					pinmux = <0x00>;
					slew-rate = <0x01>;
					output-low;
				};
			};

			cam1@1 {
				phandle = <0x63>;

				pins_cmd_dat {
					pinmux = <0x00>;
					slew-rate = <0x01>;
					output-high;
				};
			};

			cam1@2 {
				phandle = <0x64>;

				pins_cmd_dat {
					pinmux = <0x100>;
					slew-rate = <0x01>;
					output-low;
				};
			};

			cam1@3 {
				phandle = <0x65>;

				pins_cmd_dat {
					pinmux = <0x100>;
					slew-rate = <0x01>;
					output-high;
				};
			};

			camera_pins_cam0_mclk_on {
				phandle = <0x66>;

				pins_cmd_dat {
					pinmux = <0x4101>;
				};
			};

			camera_pins_cam0_mclk_off {
				phandle = <0x67>;

				pins_cmd_dat {
					pinmux = <0x4100>;
				};
			};

			camera_pins_cam1_mclk_on {
				phandle = <0x68>;

				pins_cmd_dat {
					pinmux = <0x4201>;
				};
			};

			camera_pins_cam1_mclk_off {
				phandle = <0x69>;

				pins_cmd_dat {
					pinmux = <0x4200>;
				};
			};

			ecpdefault {
				phandle = <0x33>;

				pins_cmd_dat {
					pinmux = <0x1200>;
					slew-rate = <0x01>;
					output-low;
				};
			};

			ncpoutput0 {
				phandle = <0x34>;

				pins_cmd_dat {
					pinmux = <0x1200>;
					slew-rate = <0x01>;
					output-low;
				};
			};

			ncpoutput1 {
				phandle = <0x35>;

				pins_cmd_dat {
					pinmux = <0x1200>;
					slew-rate = <0x01>;
					output-high;
				};
			};

			otg_en0 {
				phandle = <0x36>;

				pins_cmd_dat {
					pinmux = <0x1100>;
					slew-rate = <0x01>;
					output-low;
				};
			};

			otg_en1 {
				phandle = <0x37>;

				pins_cmd_dat {
					pinmux = <0x1100>;
					slew-rate = <0x01>;
					output-high;
				};
			};

			eint0default {
				phandle = <0x3a>;

				pins_cmd_dat {
					pinmux = <0x500>;
					slew-rate = <0x00>;
					bias-disable;
				};
			};

			eint@0 {
				phandle = <0x3b>;

				pins_cmd_dat {
					pinmux = <0x500>;
					slew-rate = <0x00>;
					bias-disable;
				};
			};

			eintoutput0 {
				phandle = <0x3c>;

				pins_cmd_dat {
					pinmux = <0x500>;
					slew-rate = <0x01>;
					output-low;
				};
			};

			eintoutput1 {
				phandle = <0x3d>;

				pins_cmd_dat {
					pinmux = <0x500>;
					slew-rate = <0x01>;
					output-high;
				};
			};

			rstoutput0 {
				phandle = <0x3e>;

				pins_cmd_dat {
					pinmux = <0x400>;
					slew-rate = <0x01>;
					output-low;
				};
			};

			rstoutput1 {
				phandle = <0x3f>;

				pins_cmd_dat {
					pinmux = <0x400>;
					slew-rate = <0x01>;
					output-high;
				};
			};

			lcmrstoutput0 {
				phandle = <0x79>;

				pins_cmd_dat {
					pinmux = <0x1400>;
					slew-rate = <0x01>;
					output-low;
				};
			};

			lcmrstoutput1 {
				phandle = <0x7a>;

				pins_cmd_dat {
					pinmux = <0x1400>;
					slew-rate = <0x01>;
					output-high;
				};
			};

			bloutput0 {
				phandle = <0x7b>;

				pins_cmd_dat {
					pinmux = <0x4f00>;
					slew-rate = <0x01>;
					output-low;
				};
			};

			bloutput1 {
				phandle = <0x7c>;

				pins_cmd_dat {
					pinmux = <0x4f00>;
					slew-rate = <0x01>;
					output-high;
				};
			};

			dsp_uartdefault {
				phandle = <0x30>;

				pins_rx {
					pinmux = <0x2507>;
					input-enable;
					bias-pull-up;
				};

				pins_tx {
					pinmux = <0x2607>;
				};
			};

			ethernet {
				phandle = <0x54>;

				pins_ethernet {
					pinmux = <0x04 0x104 0x204 0x304 0x404 0x504 0x604 0x704 0x804 0x904 0xb04 0xc04 0xd04 0xe04 0xf04>;
				};
			};

			i2c0 {
				phandle = <0x31>;

				pins_bus {
					pinmux = <0x3901 0x3a01>;
					bias-disable;
				};
			};

			i2c1 {
				phandle = <0x38>;

				pins_bus {
					pinmux = <0x3b01 0x3c01>;
					bias-disable;
				};
			};

			i2c2 {
				phandle = <0x40>;

				pins_bus {
					pinmux = <0x3d01 0x3e01>;
					bias-disable;
				};
			};

			i2c3 {
				phandle = <0x44>;

				pins_bus {
					pinmux = <0x3f01 0x4001>;
					bias-disable;
				};
			};

			kpddefault {
				phandle = <0x1b>;

				pins_cols {
					pinmux = <0x1801>;
					input-enable;
					bias-pull-up = <0x65>;
				};
			};

			mmc0default {
				phandle = <0x4a>;

				pins_clk {
					pinmux = <0x6301>;
					bias-pull-down = <0x65>;
				};

				pins_cmd_dat {
					pinmux = <0x6701 0x6601 0x6501 0x6401 0x6001 0x5f01 0x5e01 0x5d01 0x6201>;
					input-enable;
					bias-pull-up = <0x65>;
				};

				pins_rst {
					pinmux = <0x6101>;
					bias-pull-up = <0x65>;
				};
			};

			mmc0uhs {
				phandle = <0x4b>;

				pins_clk {
					pinmux = <0x6301>;
					drive-strength = <0x06>;
					bias-pull-down = <0x65>;
				};

				pins_cmd_dat {
					pinmux = <0x6701 0x6601 0x6501 0x6401 0x6001 0x5f01 0x5e01 0x5d01 0x6201>;
					input-enable;
					drive-strength = <0x06>;
					bias-pull-up = <0x65>;
				};

				pins_ds {
					pinmux = <0x6801>;
					drive-strength = <0x06>;
					bias-pull-down = <0x66>;
					input-enable;
				};

				pins_rst {
					pinmux = <0x6101>;
					bias-pull-up = <0x65>;
				};
			};

			mmc0sleep {
				phandle = <0x4c>;

				pins_clk {
					pinmux = <0x6301>;
					bias-disable;
					input-disable;
				};

				pins_cmd_dat {
					pinmux = <0x6701 0x6601 0x6501 0x6401 0x6001 0x5f01 0x5e01 0x5d01 0x6201>;
					bias-disable;
					input-disable;
				};

				pins_ds {
					pinmux = <0x6801>;
					bias-disable;
					input-disable;
				};

				pins_rst {
					pinmux = <0x6101>;
					bias-disable;
					input-disable;
				};
			};

			mmc1default {
				phandle = <0x4f>;

				pins_clk {
					pinmux = <0x5801>;
					drive-strength = <0x04>;
					bias-pull-down = <0x66>;
				};

				pins_cmd_dat {
					pinmux = <0x5901 0x5a01 0x5b01 0x5c01 0x5701>;
					input-enable;
					drive-strength = <0x04>;
					bias-pull-up = <0x65>;
				};

				pins_insert {
					pinmux = <0x700>;
					bias-pull-up;
				};
			};

			mmc1uhs {
				phandle = <0x50>;

				pins_clk {
					pinmux = <0x5801>;
					drive-strength = <0x06>;
					bias-pull-down = <0x66>;
				};

				pins_cmd_dat {
					pinmux = <0x5901 0x5a01 0x5b01 0x5c01 0x5701>;
					input-enable;
					drive-strength = <0x06>;
					bias-pull-up = <0x65>;
				};
			};

			mmc1sleep {
				phandle = <0x51>;

				pins_clk {
					pinmux = <0x5801>;
					bias-disable;
					input-disable;
				};

				pins_cmd_dat {
					pinmux = <0x5901 0x5a01 0x5b01 0x5c01 0x5701>;
					bias-disable;
					input-disable;
				};
			};

			spi@0 {
				phandle = <0x1c>;

				pins_spi {
					pinmux = <0x1a01 0x1b01 0x1c01 0x1d01>;
					bias-disable;
					drive-strength = <0x08>;
				};
			};
		};

		syscon@1000c000 {
			compatible = "mediatek,mt8168-apmixedsys\0syscon";
			reg = <0x00 0x1000c000 0x00 0x1000>;
			#clock-cells = <0x01>;
			phandle = <0x0b>;
		};

		fhctl@1000ce00 {
			compatible = "mediatek,fhctl";
			reg = <0x00 0x1000ce00 0x00 0x200>;
			phandle = <0x9b>;
		};

		pwrap@1000d000 {
			compatible = "mediatek,pwrap";
			reg = <0x00 0x1000d000 0x00 0x1000>;
			interrupts = <0x00 0x7b 0x04>;
			phandle = <0x9c>;
		};

		keypad@10010000 {
			compatible = "mediatek,kp";
			reg = <0x00 0x10010000 0x00 0x1000>;
			interrupts = <0x00 0x7c 0x02>;
			pinctrl-names = "default";
			pinctrl-0 = <0x1b>;
			status = "okay";
			mediatek,kpd-key-debounce = <0x400>;
			mediatek,kpd-sw-pwrkey = <0x74>;
			mediatek,kpd-hw-pwrkey = <0x01>;
			mediatek,kpd-sw-rstkey = <0x72>;
			mediatek,kpd-hw-rstkey = <0x03>;
			mediatek,kpd-use-extend-type = <0x00>;
			mediatek,kpd-hw-map-num = <0x48>;
			mediatek,kpd-hw-init-map = <0x73 0x00 0x00 0x00 0x00 0x00 0x00 0x00 0x00 0x00 0x00 0x00 0x00 0x00 0x00 0x00 0x00 0x00 0x00 0x00 0x00 0x00 0x00 0x00 0x00 0x00 0x00 0x00 0x00 0x00 0x00 0x00 0x00 0x00 0x00 0x00 0x00 0x00 0x00 0x00 0x00 0x00 0x00 0x00 0x00 0x00 0x00 0x00 0x00 0x00 0x00 0x00 0x00 0x00 0x00 0x00 0x00 0x00 0x00 0x00 0x00 0x00 0x00 0x00 0x00 0x00 0x00 0x00 0x00 0x00 0x00 0x00>;
			mediatek,kpd-pwrkey-eint-gpio = <0x00>;
			mediatek,kpd-pwkey-gpio-din = <0x00>;
			mediatek,kpd-hw-dl-key0 = <0x00>;
			mediatek,kpd-hw-dl-key1 = <0x03>;
			mediatek,kpd-hw-dl-key2 = <0x01>;
			mediatek,kpd-hw-recovery-key = <0x00>;
			mediatek,kpd-hw-factory-key = <0x03>;
			mediatek,kpd-hw-volume-key-inversed;
			phandle = <0x9d>;
		};

		dvfsrc@10012000 {
			compatible = "mediatek,dvfsrc";
			reg = <0x00 0x10012000 0x00 0x1000 0x00 0x110780 0x00 0x80 0x00 0x10006000 0x00 0x1000>;
			clocks = <0x12 0x19>;
			clock-names = "dvfsrc";
		};

		mcusys@10200000 {
			compatible = "mediatek,mt8168-mcusys\0mediatek,mt8168-mcucfg\0syscon";
			reg = <0x00 0x10200000 0x00 0x2000>;
			interrupts = <0x00 0x00 0x04>;
			#clock-cells = <0x01>;
			phandle = <0x0a>;
		};

		intpol-controller@10200a80 {
			compatible = "mediatek,mt8168-sysirq\0mediatek,mt6577-sysirq";
			interrupt-controller;
			#interrupt-cells = <0x03>;
			interrupt-parent = <0x10>;
			reg = <0x00 0x10200a80 0x00 0x20>;
			phandle = <0x01>;
		};

		sys_cirq@10202000 {
			compatible = "mediatek,mt8168-sys_cirq\0mediatek,mt6735-sys_cirq\0mediatek,sys_cirq";
			reg = <0x00 0x10202000 0x00 0x1000>;
			interrupts = <0x00 0xda 0x08>;
			mediatek,cirq_num = <0x93>;
			mediatek,spi_start_offset = <0x48>;
			phandle = <0x9e>;
		};

		systracker@10208000 {
			compatible = "mediatek,bus_dbg-v2";
			reg = <0x00 0x10208000 0x00 0x1000 0x00 0x10001000 0x00 0x1000>;
			mediatek,bus_dbg_con_offset = <0x2fc>;
			interrupts = <0x00 0x55 0x08>;
			phandle = <0x9f>;
		};

		rng@1020f000 {
			compatible = "mediatek,mt8168-rng\0mediatek,mt7623-rng";
			reg = <0x00 0x1020f000 0x00 0x100>;
			clocks = <0x12 0x1b>;
			clock-names = "rng";
			phandle = <0xa0>;
		};

		dma-controller@11000280 {
			compatible = "mediatek,mt8168-uart-dma\0mediatek,mt6577-uart-dma";
			reg = <0x00 0x11000280 0x00 0x80 0x00 0x11000300 0x00 0x80 0x00 0x11000380 0x00 0x80 0x00 0x11000400 0x00 0x80>;
			interrupts = <0x00 0x2d 0x08 0x00 0x2e 0x08 0x00 0x2f 0x08 0x00 0x30 0x08>;
			dma-requests = <0x04>;
			clocks = <0x12 0x1f>;
			clock-names = "apdma";
			#dma-cells = <0x01>;
			phandle = <0x2f>;
		};

		spi@1100a000 {
			compatible = "mediatek,mt8168-spi";
			#address-cells = <0x01>;
			#size-cells = <0x00>;
			reg = <0x00 0x1100a000 0x00 0x100>;
			interrupts = <0x00 0x3e 0x08>;
			clocks = <0x13 0x1b 0x13 0x47 0x12 0x15>;
			clock-names = "parent-clk\0sel-clk\0spi-clk";
			status = "okay";
			pinctrl-names = "default";
			pinctrl-0 = <0x1c>;
			phandle = <0xa1>;

			audio-codec@0 {
				compatible = "realtek,rt551x-spi";
				reg = <0x00>;
				spi-max-frequency = <0x112a880>;
				phandle = <0xa2>;
			};

			spi@0 {
				compatible = "mediatek,spi-mt65xx-test";
				reg = <0x00>;
				spi-max-frequency = <0x112a880>;
				phandle = <0xa3>;
			};
		};

		m4u@10205000 {
			compatible = "mediatek,mt8168-m4u";
			reg = <0x00 0x10205000 0x00 0x1000>;
			mediatek,larbs = <0x1d 0x1e 0x1f 0x20>;
			interrupts = <0x00 0x66 0x08>;
			#iommu-cells = <0x01>;
			phandle = <0x55>;
		};

		infracfg_nao@1020e000 {
			compatible = "syscon";
			reg = <0x00 0x1020e000 0x00 0x1000>;
			phandle = <0x18>;
		};

		emi@10219000 {
			compatible = "mediatek,mt8168-emi";
			reg = <0x00 0x10219000 0x00 0x1000 0x00 0x10226000 0x00 0x1000 0x00 0x1022f000 0x00 0x1000 0x00 0x10239000 0x00 0x1000>;
			interrupts = <0x00 0x58 0x08>;
			phandle = <0xa4>;
		};

		dramc@1022c000 {
			compatible = "mediatek,dramc";
			reg = <0x00 0x1022c000 0x00 0x2000 0x00 0x10232000 0x00 0x2000 0x00 0x1022e000 0x00 0x1000 0x00 0x10238000 0x00 0x1000 0x00 0x10228000 0x00 0x2000 0x00 0x10234000 0x00 0x2000 0x00 0x10230000 0x00 0x1000 0x00 0x1023a000 0x00 0x1000 0x00 0x10017000 0x00 0x1000 0x00 0x10006000 0x00 0x1000>;
			phandle = <0xa5>;
		};

		gce@1023c000 {
			compatible = "mediatek,gce\0syscon";
			reg = <0x00 0x1023c000 0x00 0x4000>;
			mediatek,larb = <0x1d>;
			power-domains = <0x21 0x00>;
			#clock-cells = <0x01>;
			interrupts = <0x00 0x62 0x08 0x00 0x63 0x08>;
			g3d_config_base = <0x13000000 0x00 0xffff0000>;
			mmsys_config_base = <0x14000000 0x01 0xffff0000>;
			disp_dither_base = <0x14010000 0x02 0xffff0000>;
			mm_na_base = <0x14020000 0x03 0xffff0000>;
			vdec_base = <0x16000000 0x1e 0xffff0000>;
			vdec1_base = <0x16020000 0x1f 0xffff0000>;
			camsys_base = <0x15000000 0x16 0xffff0000>;
			infracfg_ao_base = <0x10000000 0x0a 0xffff0000>;
			devapc_ao_mm_base = <0x10010000 0x0b 0xffff0000>;
			mdp_rdma0_sof = <0x00>;
			mdp_ccorr0_sof = <0x01>;
			mdp_rsz0_sof = <0x02>;
			mdp_rsz1_sof = <0x03>;
			mdp_wrot1_sof = <0x04>;
			mdp_wrot0_sof = <0x05>;
			mdp_tdshp0_sof = <0x06>;
			disp_ovl0_sof = <0x07>;
			disp_2l_ovl0_sof = <0x08>;
			disp_rdma0_sof = <0x09>;
			disp_rdma1_sof = <0x0a>;
			disp_wdma0_sof = <0x0b>;
			disp_color0_sof = <0x0c>;
			disp_ccorr0_sof = <0x0d>;
			disp_aal0_sof = <0x0e>;
			disp_gamma0_sof = <0x0f>;
			disp_dither0_sof = <0x10>;
			disp_dsi0_sof = <0x11>;
			img_dl_relay_sof = <0x12>;
			disp_rsz0_sof = <0x13>;
			disp_pwm0_sof = <0x14>;
			mdp_rdma1_sof = <0x15>;
			disp_dpi0_sof = <0x16>;
			mdp_rdma0_frame_done = <0x17>;
			mdp_ccorr0_frame_done = <0x18>;
			mdp_rsz0_frame_done = <0x19>;
			mdp_rsz1_frame_done = <0x1a>;
			mdp_wrot0_write_frame_done = <0x1b>;
			mdp_wrot1_write_frame_done = <0x1c>;
			mdp_tdshp0_frame_done = <0x1d>;
			disp_ovl0_frame_done = <0x1e>;
			disp_2l_ovl0_frame_done = <0x1f>;
			disp_rsz0_frame_done = <0x20>;
			disp_rdma0_frame_done = <0x21>;
			disp_rdma1_frame_done = <0x22>;
			disp_wdma0_frame_done = <0x23>;
			disp_color0_frame_done = <0x24>;
			disp_ccorr0_frame_done = <0x25>;
			disp_aal0_frame_done = <0x26>;
			disp_gamma0_frame_done = <0x27>;
			disp_dither0_frame_done = <0x28>;
			disp_dsi0_frame_done = <0x29>;
			mdp_rdma1_frame_done = <0x2a>;
			disp_dpi0_frame_done = <0x2b>;
			reserved1_frame_done = <0x2c>;
			reserved0_frame_done = <0x2d>;
			stream_done_0 = <0x82>;
			stream_done_1 = <0x83>;
			stream_done_2 = <0x84>;
			stream_done_3 = <0x85>;
			stream_done_4 = <0x86>;
			stream_done_5 = <0x87>;
			stream_done_6 = <0x88>;
			stream_done_7 = <0x89>;
			stream_done_8 = <0x8a>;
			stream_done_9 = <0x8b>;
			buf_underrun_event_0 = <0x8c>;
			buf_underrun_event_1 = <0x8d>;
			dsi0_te_pulse = <0x8e>;
			dsi0_irq_event = <0x8f>;
			dsi0_done_event = <0x90>;
			disp_wdma0_rst_done = <0x94>;
			mdp_wrot1_rst_done = <0x95>;
			mdp_wrot0_rst_done = <0x96>;
			mdp_rdma1_rst_done = <0x97>;
			mdp_rdma0_rst_done = <0x98>;
			disp_ovl0_frame_rst_done_pusle = <0x99>;
			isp_frame_done_p2_2 = <0x101>;
			isp_frame_done_p2_1 = <0x102>;
			isp_frame_done_p2_0 = <0x103>;
			isp_frame_done_p1_1 = <0x104>;
			isp_frame_done_p1_0 = <0x105>;
			camsv_0_pass1_done = <0x106>;
			camsv_1_pass1_done = <0x107>;
			seninf_cam0_fifo_full = <0x108>;
			seninf_cam1_fifo_full = <0x109>;
			seninf_cam2_fifo_full = <0x10a>;
			seninf_cam3_fifo_full = <0x10b>;
			seninf_cam4_fifo_full = <0x10c>;
			seninf_cam5_fifo_full = <0x10d>;
			seninf_cam6_fifo_full = <0x10e>;
			seninf_cam7_fifo_full = <0x10f>;
			fdvt_done = <0x110>;
			wpe_gce_frame_done = <0x111>;
			JPGENC_CMDQ_PAUSE_DONE = <0x121>;
			jpgenc_done = <0x122>;
			venc_cmdq_pause_done = <0x123>;
			venc_done = <0x124>;
			venc_mb_done = <0x125>;
			venc_128byte_cnt_done = <0x126>;
			out_event_0 = <0x382>;
			apu_gce_core0_event_0 = <0x141>;
			apu_gce_core0_event_1 = <0x142>;
			apu_gce_core0_event_2 = <0x143>;
			apu_gce_core0_event_3 = <0x144>;
			vdec_sof = <0x160>;
			vdec_frame_done_0 = <0x161>;
			vdec_frame_done_1 = <0x162>;
			vdec_frame_done_2 = <0x163>;
			vdec_frame_done_3 = <0x164>;
			vdec_frame_done_4 = <0x165>;
			vdec_frame_done_5 = <0x166>;
			vdec_frame_done_6 = <0x167>;
			vdec_event_0 = <0x168>;
			vdec_event_1 = <0x169>;
			vdec_event_2 = <0x16a>;
			vdec_event_3 = <0x16b>;
			vdec_event_4 = <0x16c>;
			vdec_event_5 = <0x16d>;
			vdec_event_6 = <0x16e>;
			vdec_event_7 = <0x16f>;
			max_prefetch_cnt = <0x01>;
			prefetch_size = <0x60>;
			sram_size_cpr_64 = <0x40>;
			mmsys_config = <0x22>;
			mdp_rdma0 = <0x23>;
			mdp_rdma1 = <0x24>;
			mdp_rsz0 = <0x25>;
			mdp_rsz1 = <0x26>;
			mdp_wrot0 = <0x27>;
			mdp_wrot1 = <0x28>;
			mdp_tdshp0 = <0x29>;
			mdp_color0 = <0x2a>;
			mdp_ccorr0 = <0x2b>;
			mm_mutex = <0x2c>;
			sram_share_cnt = <0x01>;
			sram_share_engine = <0x0a>;
			sram_share_event = <0x2c6>;
			clocks = <0x12 0x05 0x12 0x12>;
			clock-names = "GCE\0GCE_TIMER";
			mediatek,mailbox-gce = <0x2d>;
			mboxes = <0x2d 0x00 0x00 0x04 0x2d 0x01 0x00 0x04 0x2d 0x02 0x00 0x05 0x2d 0x03 0x00 0x04 0x2d 0x04 0x00 0x04 0x2d 0x05 0xffffffff 0x02 0x2d 0x06 0xc8 0x03 0x2d 0x07 0xffffffff 0x02 0x2e 0x08 0x00 0x01 0x2e 0x09 0x00 0x04 0x2e 0x0a 0x00 0x04 0x2d 0x0b 0x00 0x01 0x2d 0x0c 0x00 0x01 0x2d 0x0d 0x00 0x01 0x2d 0x0e 0x00 0x01 0x2d 0x0f 0xffffffff 0x01>;
			phandle = <0xa6>;
		};

		gce_mbox@1023c000 {
			compatible = "mediatek,mailbox-gce";
			reg = <0x00 0x1023c000 0x00 0x4000>;
			interrupts = <0x00 0x62 0x08>;
			#mbox-cells = <0x03>;
			#gce-event-cells = <0x01>;
			#gce-subsys-cells = <0x02>;
			clocks = <0x12 0x05 0x12 0x12>;
			clock-names = "gce\0GCE_TIMER";
			phandle = <0x2d>;
		};

		gce_mbox_svp@1023c000 {
			compatible = "mediatek,mailbox-gce-svp";
			reg = <0x00 0x1023c000 0x00 0x4000>;
			interrupts = <0x00 0x62 0x08>;
			#mbox-cells = <0x03>;
			clocks = <0x12 0x05 0x12 0x12>;
			clock-names = "gce\0GCE_TIMER";
			phandle = <0x2e>;
		};

		adc@11001000 {
			compatible = "mediatek,mt8168-auxadc\0mediatek,mt2701-auxadc";
			reg = <0x00 0x11001000 0x00 0x1000>;
			clocks = <0x12 0x1c>;
			clock-names = "main";
			#io-channel-cells = <0x01>;
			status = "okay";
			phandle = <0x02>;
		};

		uart0@11002000 {
			compatible = "mediatek,mt8168-uart\0mediatek,mt6577-uart";
			reg = <0x00 0x11002000 0x00 0x1000>;
			interrupts = <0x00 0x23 0x08>;
			clocks = <0x11 0x12 0x0e>;
			clock-names = "baud\0bus";
			dmas = <0x2f 0x00 0x2f 0x01>;
			dma-names = "tx\0rx";
			status = "okay";
			phandle = <0xa7>;
		};

		uart1@11003000 {
			compatible = "mediatek,mt8168-uart\0mediatek,mt6577-uart";
			reg = <0x00 0x11003000 0x00 0x1000>;
			interrupts = <0x00 0x24 0x08>;
			clocks = <0x11 0x12 0x0f>;
			clock-names = "baud\0bus";
			dmas = <0x2f 0x02 0x2f 0x03>;
			dma-names = "tx\0rx";
			status = "okay";
			pinctrl-names = "default";
			pinctrl-0 = <0x30>;
			phandle = <0xa8>;
		};

		i2c@11007000 {
			compatible = "mediatek,mt8168-i2c\0mediatek,mt2712-i2c";
			reg = <0x00 0x11007000 0x00 0xa0 0x00 0x11000080 0x00 0x80>;
			interrupts = <0x00 0x1c 0x08>;
			clock-div = <0x01>;
			clocks = <0x12 0x34 0x12 0x1f>;
			clock-names = "main\0dma";
			#address-cells = <0x01>;
			#size-cells = <0x00>;
			status = "okay";
			pinctrl-names = "default";
			pinctrl-0 = <0x31>;
			clock-frequency = <0x61a80>;
			phandle = <0xa9>;

			rt9466@53 {
				compatible = "richtek,rt9466";
				reg = <0x53>;
				interrupt-parent = <0x32>;
				interrupts = <0x7c 0x02>;
				rt,intr_gpio = <0x32 0x0a 0x00>;
				rt-interrupt-names = "wdtmri\0chg_mivr\0chg_aiclmeasi\0chg_statci\0chg_ieoci\0pwr_rdy";
				status = "okay";
				charger_name = "primary_chg";
				ichg = <0x1e8480>;
				aicr = <0x7a120>;
				mivr = <0x432380>;
				cv = <0x4127b0>;
				ieoc = <0x3d090>;
				safety_timer = <0x0c>;
				ircmp_resistor = <0x13880>;
				ircmp_vclamp = <0x17700>;
				en_te;
			};

			subpmic_pmu@34 {
				compatible = "mediatek,subpmic_pmu";
				reg = <0x34>;
				status = "okay";
				phandle = <0xaa>;

				mt6370_pmu_dts {
					interrupt-controller;
					#interrupt-cells = <0x01>;
					interrupt-parent = <0x32>;
					interrupts = <0x0c 0x02>;
					phandle = <0xab>;

					core {
						compatible = "mediatek,mt6370_pmu_core";
						interrupt-names = "otp\0vdda_ovp\0vdda_uv";
						i2cstmr_rst_tmr = <0x00>;
						mrstb_en;
						mrstb_tmr = <0x03>;
						int_wdt = <0x00>;
						int_deg = <0x00>;
					};

					charger {
						compatible = "mediatek,mt6370_pmu_charger";
						interrupt-names = "chg_mivr\0chg_aiclmeasi\0attachi\0ovpctrl_uvp_d_evt\0chg_wdtmri\0chg_vbusov\0chg_tmri\0chg_treg";
						charger_name = "primary_chg";
						load_switch_name = "primary_load_switch";
						ichg = <0x2dc6c0>;
						aicr = <0x7a120>;
						mivr = <0x44aa20>;
						cv = <0x4127b0>;
						ieoc = <0x3d090>;
						safety_timer = <0x14>;
						dc_wdt = "\0=\t";
						ircmp_resistor = <0x61a8>;
						ircmp_vclamp = <0xfa00>;
						aicl_vth_offset = <0x30d40>;
						aicl_err_h = <0x30d40>;
						aicl_err_l = <0x186a0>;
						otg_oc = <0x13d620>;
						enable_te;
						enable_wdt;
						power_switch_support = <0x00>;
						pinctrl-names = "default\0ncp3902_en_output0\0ncp3902_en_output1\0usbc_otg_en0\0usbc_otg_en1";
						pinctrl-0 = <0x33>;
						pinctrl-1 = <0x34>;
						pinctrl-2 = <0x35>;
						pinctrl-3 = <0x36>;
						pinctrl-4 = <0x37>;
						status = "okay";
					};

					ldo {
						compatible = "mediatek,mt6370_pmu_ldo";
						interrupt-names = "ldo_oc";
						ldo_oms = <0x01>;
						ldo_vrc_lt = <0x01>;

						mt6370_ldo {
							regulator-name = "irtx_ldo";
							regulator-min-microvolt = <0x186a00>;
							regulator-max-microvolt = "\0=\t";
						};
					};

					bled {
						compatible = "mediatek,mt6370_pmu_bled";
						interrupt-names = "bled_ocp";
						mt,bled_name = "lcd-backlight";
						mt,chan_en = <0x0f>;
						mt,map_linear;
						mt,bl_ovp_level = <0x03>;
						mt,bl_ocp_level = <0x02>;
						mt,use_pwm;
						mt,pwm_fsample = <0x02>;
						mt,pwm_deglitch = <0x01>;
						mt,pwm_hys_en = <0x01>;
						mt,pwm_hys = <0x00>;
						mt,pwm_avg_cycle = <0x00>;
						mt,bled_ramptime = <0x03>;
						mt,bled_flash_ramp = <0x01>;
						mt,max_bled_brightness = <0x555>;
						mt,ignore_initial_bled_brightness = <0x01>;
						brightness-normalize-enable = <0x01>;
						chosen-id = <0xff>;
						brightness-normalize-count = <0x03>;
						brightness-normalize-table = <0x02 0x1bd 0x1bd 0x4f 0x03 0x1a7 0x1a7 0x4f 0x05 0x1e7 0x1e7 0x4f>;
					};

					dsv {
						compatible = "mediatek,mt6370_pmu_dsv";
						interrupt-names = "dsv_vneg_ocp\0dsv_vpos_ocp\0dsv_bst_ocp\0dsv_vneg_scp\0dsv_vpos_scp";
						db_ext_en = <0x00>;
						db_periodic_fix = <0x00>;
						db_single_pin = <0x00>;
						db_freq_pm = <0x00>;
						db_periodic_mode = <0x00>;
						db_startup = <0x00>;
						db_vneg_20ms = <0x01>;
						db_vneg_disc = <0x00>;
						db_vpos_20ms = <0x01>;
						db_vpos_disc = <0x01>;
						db_delay = <0x03>;
						db_vbst = <0x1838>;
						db_vpos_slew = <0x01>;
						db_vneg_slew = <0x01>;

						mt6370_dsvp {
							regulator-name = "dsv_pos";
							regulator-min-microvolt = <0x5b8d80>;
							regulator-max-microvolt = <0x5b8d80>;
						};

						mt6370_dsvn {
							regulator-name = "dsv_neg";
							regulator-min-microvolt = <0x5b8d80>;
							regulator-max-microvolt = <0x5b8d80>;
						};
					};
				};
			};

			usb_type_c@4e {
				compatible = "mediatek,usb_type_c";
				reg = <0x4e>;
				status = "okay";
				phandle = <0xac>;

				type_c_port0 {
					tcpc-dual,supported_modes = <0x00>;
					mt-tcpc,name = "type_c_port0";
					mt-tcpc,role_def = <0x04>;
					mt-tcpc,rp_level = <0x00>;
					mt-tcpc,vconn_supply = <0x01>;
					mt-tcpc,notifier_supply_num = <0x03>;
					interrupt-parent = <0x32>;
					interrupts = <0x0d 0x02>;
					mt6370pd,intr_gpio = <0x32 0x0d 0x00>;
					mt6370pd,intr_gpio_num = <0x0d>;
					phandle = <0xad>;

					pd-data {
						pd,vid = <0x29cf>;
						pd,pid = <0x5081>;
						pd,source-cap-ext = <0x171129cf 0x00 0x102 0x00 0x00 0x2000000>;
						pd,mfrs = "RichtekTCPC";
						pd,charging_policy = <0x21>;
						pd,source-pdo-size = <0x01>;
						pd,source-pdo-data = <0x19032>;
						pd,sink-pdo-size = <0x02>;
						pd,sink-pdo-data = <0x190c8 0xc0761e3c>;
						pd,id-vdo-size = <0x03>;
						pd,id-vdo-data = <0xd10029cf 0x00 0x10000>;
						bat,nr = <0x01>;
						pd,country_nr = <0x00>;

						bat-info0 {
							bat,vid = <0x29cf>;
							bat,pid = <0x1711>;
							bat,mfrs = "bat1";
							bat,design_cap = <0xbb8>;
						};
					};

					dpm_caps {
						local_dr_power;
						local_dr_data;
						local_usb_comm;
						local_no_suspend;
						local_vconn_supply;
						attemp_enter_dp_mode;
						attemp_discover_cable;
						attemp_discover_id;
						pr_check = <0x00>;
						pr_check_gp_source;
						dr_check = <0x00>;
					};
				};
			};
		};

		i2c@11008000 {
			compatible = "mediatek,mt8168-i2c\0mediatek,mt2712-i2c";
			reg = <0x00 0x11008000 0x00 0xa0 0x00 0x11000100 0x00 0x80>;
			interrupts = <0x00 0x1d 0x08>;
			clock-div = <0x01>;
			clocks = <0x12 0x35 0x12 0x1f>;
			clock-names = "main\0dma";
			#address-cells = <0x01>;
			#size-cells = <0x00>;
			status = "okay";
			pinctrl-names = "default";
			pinctrl-0 = <0x38>;
			clock-frequency = <0x186a0>;
			phandle = <0xae>;

			focaltech@38 {
				compatible = "focaltech,fts";
				reg = <0x38>;
				vdd_ana-supply = <0x39>;
				interrupt-parent = <0x32>;
				interrupts = <0x05 0x02>;
				focaltech,swap-x2y = <0x00>;
				focaltech,reset-gpio = <0x32 0x04 0x01>;
				focaltech,irq-gpio = <0x32 0x05 0x02>;
				focaltech,max-touch-number = <0x05>;
				focaltech,display-coords = <0x00 0x00 0x320 0x500>;
			};

			gt9xx@5d {
				compatible = "goodix,gt9xx";
				reg = <0x5d>;
				vdd_ana-supply = <0x39>;
				pinctrl-names = "default\0int-input\0int-output-low\0int-output-high\0state_rst_output0\0state_rst_output1";
				pinctrl-0 = <0x3a>;
				pinctrl-1 = <0x3b>;
				pinctrl-2 = <0x3c>;
				pinctrl-3 = <0x3d>;
				pinctrl-4 = <0x3e>;
				pinctrl-5 = <0x3f>;
				reset-gpios = <0x32 0x04 0x00>;
				irq-gpios = <0x32 0x05 0x00>;
				irq-flags = <0x02>;
				touchscreen-max-id = <0x0b>;
				touchscreen-size-x = <0x320>;
				touchscreen-size-y = <0x500>;
				touchscreen-max-w = <0x200>;
				touchscreen-max-p = <0x200>;
				goodix,slide-wakeup = <0x01>;
				goodix,type-a-report = <0x00>;
				goodix,driver-send-cfg = <0x01>;
				goodix,resume-in-workqueue = <0x00>;
				goodix,int-sync = <0x01>;
				goodix,swap-x2y = <0x00>;
				goodix,esd-protect = <0x01>;
				goodix,auto-update-cfg = <0x00>;
				goodix,auto-update = <0x01>;
				goodix,power-off-sleep = <0x01>;
				goodix,pen-suppress-finger = <0x00>;
				goodix,cfg-group0 = [49 20 03 00 05 0a 35 08 21 08 23 05 32 23 05 04 00 00 00 02 22 22 00 16 18 1c 14 92 31 bb 2a 2c f0 19 00 00 00 dc 33 1c 00 00 00 00 00 00 00 00 00 00 04 23 37 8f e0 85 00 0a 00 04 89 24 00 83 28 00 80 2b 00 7c 30 00 7a 34 00 78 00 00 00 00 00 00 00 00 00 00 00 00 0f 0a 00 00 00 00 00 00 00 00 00 14 46 28 03 00 02 20 00 00 00 01 00 00 15 14 13 12 11 10 0f 0e 0d 0c 0b 0a 09 08 07 06 05 04 03 02 01 00 ff ff ff ff ff ff ff ff 03 04 05 06 07 08 09 0a 0b 0c 0d 0e 0f 10 11 12 13 14 15 16 17 18 19 1b 1c 1d 1e 1f 20 21 22 23 24 25 26 ff ff ff ff ff ff ff 57 01];
				goodix,cfg-group1 = [43 20 03 00 05 0a 35 00 01 08 28 0f 5a 3c 01 02 00 00 00 00 13 14 00 17 1a 20 14 92 31 bb 3e 40 35 11 00 00 00 21 04 1c 00 00 00 00 00 00 00 00 00 00 00 28 50 94 c0 a4 28 28 00 04 b0 2a 00 a4 31 00 9c 38 00 92 41 00 8b 4a 00 8b 00 00 00 00 00 00 00 00 00 00 00 00 45 05 00 e4 43 1a 00 00 1c 00 00 00 00 00 00 00 00 20 00 00 00 00 00 00 00 01 02 03 04 05 06 07 08 09 0a 0b 0c 0d 0e 0f 10 11 12 13 14 15 ff ff ff ff ff ff ff ff 03 04 05 06 07 08 09 0a 0b 0c 0d 0e 0f 10 11 12 13 14 15 16 17 18 19 1b 1c 1d 1e 1f 20 21 22 23 24 25 26 ff ff ff ff ff ff ff 8d 01];
			};

			p922x@61 {
				compatible = "IDT,idt_wireless_power";
				reg = <0x61>;
				interrupt-parent = <0x32>;
				interrupts = <0x0b 0x02 0x4a 0x01>;
				wpc-mivr = <0x44aa20 0x44aa20>;
				wpc-switch-voltage = <0x1770 0x1964 0x1b58 0x2134 0x2328 0x251c>;
				bpp-5w-fod = <0xfe7ffe7f 0xfe7ffe7f 0xfe7ffe7f 0xfe7f0000>;
				bpp-10w-fod = <0xfe7ffe7f 0xfe7ffe7f 0xfe7ffe7f 0xfe7f0000>;
				p922x-irq = <0x32 0x0b 0x00>;
				p922x-pg = <0x32 0x4a 0x00>;
				wpc-hardware-config = <0x00>;
				use-buck;
				status = "okay";
			};
		};

		i2c@11009000 {
			compatible = "mediatek,mt8168-i2c\0mediatek,mt2712-i2c";
			reg = <0x00 0x11009000 0x00 0xa0 0x00 0x11000180 0x00 0x80>;
			interrupts = <0x00 0x1e 0x08>;
			clock-div = <0x01>;
			clocks = <0x12 0x36 0x12 0x1f>;
			clock-names = "main\0dma";
			#address-cells = <0x01>;
			#size-cells = <0x00>;
			status = "okay";
			pinctrl-names = "default";
			pinctrl-0 = <0x40>;
			clock-frequency = <0x186a0>;
			phandle = <0xaf>;

			alsps@23 {
				compatible = "mediatek,ltr559";
				reg = <0x23>;
				interrupt-parent = <0x32>;
				interrupts = <0x0a 0x08>;
				debounce = <0x0a 0x00>;
				pinctrl-names = "pin_default\0pin_cfg";
				pinctrl-0 = <0x41>;
				pinctrl-1 = <0x42>;
				status = "okay";
				i2c_num = <0x02>;
				i2c_addr = <0x23 0x00 0x00 0x00>;
				polling_mode_ps = <0x00>;
				polling_mode_als = <0x01>;
				power_id = <0xffff>;
				power_vol = <0x00>;
				als_level = <0x00 0x01 0x01 0x07 0x0f 0x0f 0x64 0x3e8 0x7d0 0xbb8 0x1770 0x2710 0x36b0 0x4650 0x4e20>;
				als_value = <0x28 0x28 0x5a 0x5a 0xa0 0xa0 0xe1 0x140 0x280 0x500 0x500 0xa28 0xa28 0xa28 0x2800 0x2800>;
				ps_threshold_high = <0x384>;
				ps_threshold_low = <0x258>;
				is_batch_supported_ps = <0x00>;
				is_batch_supported_als = <0x00>;
			};

			gsensor@4c {
				compatible = "mediatek,mc3416";
				reg = <0x4c>;
				status = "okay";
				i2c_num = <0x02>;
				i2c_addr = <0x4c 0x00 0x00 0x00>;
				direction = <0x05>;
				power_id = <0xffff>;
				power_vol = <0x00>;
				firlen = <0x00>;
				is_batch_supported = <0x00>;
			};

			gsensor@18 {
				compatible = "mediatek,gsensor";
				reg = <0x18>;
				status = "okay";
				i2c_num = <0x02>;
				i2c_addr = <0x18 0x00 0x00 0x00>;
				direction = <0x05>;
				power_id = <0xffff>;
				power_vol = <0x00>;
				firlen = <0x00>;
				is_batch_supported = <0x00>;
			};

			fusb251@28 {
				compatible = "on,fusb251";
				reg = <0x28>;
				i2c_num = <0x02>;
				i2c_addr = <0x28 0x00 0x00 0x00>;
				threshold_sbu = <0x2eb 0x3c0>;
				threshold_sbuft = <0x64>;
				work_interval = <0x0f 0x1e 0x3c>;
				det_delay = <0x64 0x3e8>;
				status = "okay";
			};
		};

		therm_ctrl@1100b000 {
			compatible = "mediatek,therm_ctrl";
			reg = <0x00 0x1100b000 0x00 0x1000>;
			interrupts = <0x00 0x16 0x08>;
			clocks = <0x12 0x06>;
			clock-names = "therm-main";
			mediatek,auxadc = <0x02 0x00>;
			mediatek,apmixed = <0x0b>;
			mediatek,infracfg_ao = <0x12>;
		};

		svs@1100b000 {
			compatible = "mediatek,mt8168-svs";
			reg = <0x00 0x1100b000 0x00 0x1000>;
			interrupts = <0x00 0x45 0x08>;
			clocks = <0x12 0x06>;
			clock-names = "main_clk";
			nvmem-cells = <0x43>;
			nvmem-cell-names = "svs-calibration-data";
			phandle = <0xb0>;

			svs_cpu_little {
				compatible = "mediatek,mt8168-svs-cpu-little";
				operating-points-v2 = <0x0c>;
				vcpu_little-supply = <0x0d>;
				phandle = <0xb1>;
			};
		};

		btif@1100c000 {
			compatible = "mediatek,btif";
			reg = <0x00 0x1100c000 0x00 0x1000 0x00 0x11000480 0x00 0x80 0x00 0x11000500 0x00 0x80>;
			interrupts = <0x00 0x38 0x08 0x00 0x31 0x08 0x00 0x32 0x08>;
			clocks = <0x12 0x14 0x12 0x1f>;
			clock-names = "btifc\0apdmac";
		};

		disp_pwm@1100e000 {
			compatible = "mediatek,disp_pwm";
			reg = <0x00 0x1100e000 0x00 0x1000>;
		};

		i2c@1100f000 {
			compatible = "mediatek,mt8168-i2c\0mediatek,mt2712-i2c";
			reg = <0x00 0x1100f000 0x00 0xa0 0x00 0x11000200 0x00 0x80>;
			interrupts = <0x00 0x1f 0x08>;
			clock-div = <0x01>;
			clocks = <0x12 0x37 0x12 0x1f>;
			clock-names = "main\0dma";
			#address-cells = <0x01>;
			#size-cells = <0x00>;
			status = "okay";
			pinctrl-names = "default";
			pinctrl-0 = <0x44>;
			clock-frequency = <0x186a0>;
			phandle = <0xb2>;

			audio-codec@57 {
				compatible = "realtek,rt551x";
				reg = <0x57>;
				interrupt-parent = <0x32>;
				interrupts = <0x50 0x04>;
				rt5518-irq = <0x32 0x50 0x00>;
				rt5518-reset = <0x32 0x51 0x00>;
				pinctrl-names = "state_eint_as_int";
				pinctrl-0 = <0x45>;
				hw_analog_gain = <0x0e>;
				hw_digital_gain = <0x883b>;
				phandle = <0x49>;
			};

			kd_camera_hw1@20 {
				compatible = "mediatek,camera_main";
				reg = <0x3c>;
			};
		};

		nfi@11018000 {
			compatible = "mediatek,mt8168-nfc";
			reg = <0x00 0x11018000 0x00 0x1000>;
			interrupts = <0x00 0x4e 0x08>;
			clocks = <0x12 0x3d 0x12 0x3e>;
			clock-names = "nfi_clk\0pad_clk";
			ecc-engine = <0x46>;
			#address-cells = <0x01>;
			#size-cells = <0x00>;
			status = "disabled";
			phandle = <0xb3>;
		};

		ecc@11019000 {
			compatible = "mediatek,mt8168-ecc";
			reg = <0x00 0x11019000 0x00 0x1000>;
			interrupts = <0x00 0x4f 0x08>;
			clocks = <0x12 0x3c>;
			clock-names = "nfiecc_clk";
			status = "disabled";
			phandle = <0x46>;
		};

		usb@11201000 {
			compatible = "mediatek,mtu3";
			reg = <0x00 0x11201000 0x00 0x2e00 0x00 0x11203e00 0x00 0x100 0x00 0x11200000 0x00 0x1000>;
			reg-names = "mac\0ippc\0xhci";
			interrupts = <0x00 0x10 0x08>;
			clocks = <0x13 0x87 0x12 0x45 0x12 0x44 0x12 0x04 0x12 0x46>;
			clock-names = "sys_ck\0ref_ck\0mcu_ck\0dma_ck\0xhci_ck";
			#address-cells = <0x02>;
			#size-cells = <0x02>;
			ranges;
			status = "okay";
			phys = <0x47 0x03>;
			vusb33-supply = <0x48>;
			mediatek,use-typec;
			extcon = <0x0f>;
			dr_mode = "otg";
			phandle = <0xb4>;

			xhci@11200000 {
				compatible = "mediatek,mtk-xhci";
				reg = <0x00 0x11200000 0x00 0x1000>;
				reg-names = "mac";
				interrupts = <0x00 0x43 0x08>;
				status = "okay";
				phandle = <0xb5>;
			};
		};

		audio-controller@11220000 {
			compatible = "mediatek,mt8168-afe-pcm";
			reg = <0x00 0x11220000 0x00 0x1000 0x00 0x11221000 0x00 0xa000>;
			interrupts = <0x00 0x61 0x08>;
			power-domains = <0x21 0x03>;
			clocks = <0x13 0x4d 0x13 0x7a 0x13 0x7b 0x13 0x7c 0x13 0x7d 0x13 0x7e 0x13 0x7f 0x13 0x80 0x13 0x81 0x13 0x82 0x13 0x53 0x13 0x51 0x13 0x52 0x13 0x4f 0x13 0x50 0x13 0x6a 0x13 0x6b 0x13 0x6c 0x13 0x6d 0x13 0x6e 0x13 0x6f 0x13 0x70 0x13 0x11 0x13 0x34 0x13 0x08 0x13 0x13 0x13 0x4e>;
			clock-names = "top_audio_sel\0audio_i2s0_m\0audio_i2s1_m\0audio_i2s2_m\0audio_i2s3_m\0audio_tdmout_m\0audio_tdmout_b\0audio_tdmin_m\0audio_tdmin_b\0audio_spdif_m\0spdif_in\0engen1\0engen2\0aud1\0aud2\0i2s0_m_sel\0i2s1_m_sel\0i2s2_m_sel\0i2s3_m_sel\0tdmout_m_sel\0tdmin_m_sel\0spdif_b_sel\0syspll3_d4\0top_clk26m_clk\0syspll1_d4\0syspll4_d2\0audio_intbus_sel";
			assigned-clocks = <0x13 0x4f 0x13 0x50 0x13 0x51 0x13 0x52>;
			assigned-clock-parents = <0x13 0x2c 0x13 0x30 0x13 0x2f 0x13 0x33>;
			mediatek,topckgen-regmap = <0x13>;
			status = "okay";
			mediatek,tdm-out-mode = <0x00>;
			mediatek,dmic-two-wire-mode = <0x00>;
			mediatek,i2s-clock-modes = <0x00 0x01>;
			mediatek,dl1-use-sram = <0x11221000 0x4000>;
			mediatek,vul2-use-sram = <0x11225000 0x6000>;
			sound-dai = <0x49>;
			phandle = <0x7d>;
		};

		mmc@11230000 {
			compatible = "mediatek,mt8168-mmc";
			reg = <0x00 0x11230000 0x00 0x1000 0x00 0x11cd0000 0x00 0x1000>;
			interrupts = <0x00 0x17 0x08>;
			clocks = <0x13 0x4a 0x12 0x16 0x12 0x2b>;
			clock-names = "source\0hclk\0source_cg";
			status = "okay";
			pinctrl-names = "default\0state_uhs\0sleep";
			pinctrl-0 = <0x4a>;
			pinctrl-1 = <0x4b>;
			pinctrl-2 = <0x4c>;
			bus-width = <0x08>;
			max-frequency = <0xbebc200>;
			cap-mmc-highspeed;
			mmc-hs200-1_8v;
			mmc-hs400-1_8v;
			cap-cqe;
			cap-cqe_dcmd;
			hs400-ds-delay = <0x12012>;
			vmmc-supply = <0x4d>;
			vqmmc-supply = <0x4e>;
			assigned-clocks = <0x13 0x4a>;
			assigned-clock-parents = <0x13 0x36>;
			non-removable;
			no-sd;
			no-sdio;
			phandle = <0xb6>;
		};

		mmc@11240000 {
			compatible = "mediatek,mt8168-mmc";
			reg = <0x00 0x11240000 0x00 0x1000 0x00 0x11c90000 0x00 0x1000>;
			interrupts = <0x00 0x18 0x08>;
			clocks = <0x13 0x4c 0x12 0x18 0x12 0x2c>;
			clock-names = "source\0hclk\0source_cg";
			status = "okay";
			pinctrl-names = "default\0state_uhs\0sleep";
			pinctrl-0 = <0x4f>;
			pinctrl-1 = <0x50>;
			pinctrl-2 = <0x51>;
			bus-width = <0x04>;
			max-frequency = <0xbebc200>;
			cap-sd-highspeed;
			sd-uhs-sdr50;
			sd-uhs-sdr104;
			cd-gpios = <0x32 0x07 0x00>;
			vmmc-supply = <0x52>;
			vqmmc-supply = <0x53>;
			no-mmc;
			no-sdio;
			phandle = <0xb7>;
		};

		mmc@11250000 {
			compatible = "mediatek,mt8168-sdio";
			reg = <0x00 0x11250000 0x00 0x1000 0x00 0x11c60000 0x00 0x1000>;
			interrupts = <0x00 0x44 0x08>;
			clocks = <0x13 0x4b 0x12 0x17 0x12 0x2d 0x12 0x41 0x12 0x29>;
			clock-names = "source\0hclk\0source_cg\0bus_clk\0ext_clk";
			status = "disabled";
			phandle = <0xb8>;
		};

		ethernet@112a0000 {
			compatible = "mediatek,mt8168-ethernet";
			reg = <0x00 0x112a0000 0x00 0x1000 0x00 0x10001c00 0x00 0x100>;
			interrupts = <0x00 0x19 0x08>;
			eth-gpios = <0x32 0x22 0x00>;
			clocks = <0x13 0x64 0x12 0x38 0x12 0x39>;
			clock-names = "core\0reg\0trans";
			mac-address = [00 00 00 00 00 00];
			status = "disabled";
			pinctrl-names = "default";
			pinctrl-0 = <0x54>;
			phandle = <0xb9>;
		};

		adsp_pcm {
			compatible = "mediatek,mt8168-adsp-pcm";
			status = "okay";
			phandle = <0x7e>;
		};

		mipi_tx0@11c00000 {
			compatible = "mediatek,mipi_tx0";
			reg = <0x00 0x11c00000 0x00 0x800>;
		};

		mipi_rx_ana_csi0a@11c10000 {
			compatible = "mediatek,mipi_rx_ana_csi0a\0syscon";
			reg = <0x00 0x11c10000 0x00 0x1000>;
			#clock-cells = <0x01>;
			phandle = <0x56>;
		};

		mipi_rx_ana_csi0b@11c11000 {
			compatible = "mediatek,mipi_rx_ana_csi0b\0syscon";
			reg = <0x00 0x11c11000 0x00 0x1000>;
			#clock-cells = <0x01>;
			phandle = <0x57>;
		};

		mipi_rx_ana_csi1a@11c12000 {
			compatible = "mediatek,mipi_rx_ana_csi1a\0syscon";
			reg = <0x00 0x11c12000 0x00 0x1000>;
			#clock-cells = <0x01>;
			phandle = <0x58>;
		};

		mipi_rx_ana_csi1b@11c13000 {
			compatible = "mediatek,mipi_rx_ana_csi1b\0syscon";
			reg = <0x00 0x11c13000 0x00 0x1000>;
			#clock-cells = <0x01>;
			phandle = <0x59>;
		};

		efuse@11c50000 {
			compatible = "mediatek,mt8168-efuse\0mediatek,efuse";
			reg = <0x00 0x11c50000 0x00 0x1000>;
			#address-cells = <0x01>;
			#size-cells = <0x01>;
			phandle = <0xba>;

			calib@580 {
				reg = <0x580 0x20>;
				phandle = <0x43>;
			};

			leakage@cd4 {
				reg = <0xcd4 0x04>;
				phandle = <0x77>;
			};
		};

		usb-phy@11cc0000 {
			compatible = "mediatek,generic-tphy-v2";
			clocks = <0x13 0x83>;
			clock-names = "u3phya_ref";
			#address-cells = <0x02>;
			#size-cells = <0x02>;
			ranges;
			status = "okay";
			phandle = <0xbb>;

			usb-phy@11cc0000 {
				reg = <0x00 0x11cc0000 0x00 0x400>;
				clocks = <0x13 0x88>;
				clock-names = "ref";
				#phy-cells = <0x01>;
				status = "okay";
				phandle = <0x47>;
			};

			usb-phy@11cc1000 {
				reg = <0x00 0x11cc1000 0x00 0x400>;
				clocks = <0x13 0x88>;
				clock-names = "ref";
				#phy-cells = <0x01>;
				status = "okay";
				phandle = <0xbc>;
			};
		};

		syscon@13000000 {
			compatible = "mediatek,mt8168-mfgcfg\0syscon";
			reg = <0x00 0x13000000 0x00 0x1000>;
			#clock-cells = <0x01>;
			phandle = <0x74>;
		};

		mali@13040000 {
			compatible = "mediatek,mali\0arm,mali-midgard\0arm,mali-bifrost";
			reg = <0x00 0x13040000 0x00 0x4000>;
			interrupts = <0x00 0xc9 0x08 0x00 0xca 0x08 0x00 0xcb 0x08 0x00 0xcc 0x08>;
			interrupt-names = "GPU\0MMU\0JOB\0EVENT";
		};

		syscon@14000000 {
			compatible = "mediatek,mt8168-mmsys\0syscon";
			reg = <0x00 0x14000000 0x00 0x1000>;
			#clock-cells = <0x01>;
			phandle = <0x14>;
		};

		mmsys_config@14000000 {
			compatible = "mediatek,mmsys_config\0syscon";
			reg = <0x00 0x14000000 0x00 0x1000>;
			interrupts = <0x00 0xab 0x08>;
			#clock-cells = <0x01>;
			clocks = <0x14 0x1a 0x14 0x1d 0x14 0x1e>;
			clock-names = "CAM_MDP\0IMG_DL_RELAY\0IMG_DL_ASYNC_TOP";
			phandle = <0x22>;
		};

		disp_mutex0@14001000 {
			compatible = "mediatek,disp_mutex0";
			reg = <0x00 0x14001000 0x00 0x1000>;
			interrupts = <0x00 0x9a 0x08>;
			gce-event-names = "stream_done_0\0stream_done_1\0stream_done_2";
			gce-events = <0x2d 0x82 0x2d 0x83 0x2d 0x84>;
			phandle = <0x2c>;
		};

		smi@14002000 {
			compatible = "mediatek,mt8168-smi-common\0syscon";
			reg = <0x00 0x14002000 0x00 0x1000>;
			clocks = <0x14 0x16 0x14 0x16 0x14 0x18 0x14 0x19>;
			clock-names = "apb\0smi\0gals0\0gals1";
			mediatek,mmsys = <0x22>;
			phandle = <0x17>;
		};

		larb@14003000 {
			compatible = "mediatek,mt8168-smi-larb\0mediatek,mt8183-smi-larb";
			reg = <0x00 0x14003000 0x00 0x1000>;
			mediatek,smi = <0x17>;
			mediatek,larb-id = <0x00>;
			clocks = <0x14 0x17 0x14 0x17>;
			clock-names = "apb\0smi";
			phandle = <0x1d>;
		};

		mdp_rdma0@14004000 {
			compatible = "mediatek,mdp_rdma0";
			reg = <0x00 0x14004000 0x00 0x1000>;
			interrupts = <0x00 0x9b 0x08>;
			clocks = <0x14 0x00>;
			clock-names = "MDP_RDMA0";
			phandle = <0x23>;
		};

		mdp_ccorr0@14005000 {
			compatible = "mediatek,mdp_ccorr0";
			reg = <0x00 0x14005000 0x00 0x1000>;
			interrupts = <0x00 0xaa 0x08>;
			clocks = <0x14 0x01>;
			clock-names = "MDP_CCORR";
			phandle = <0x2b>;
		};

		mdp_rsz0@14006000 {
			compatible = "mediatek,mdp_rsz0";
			reg = <0x00 0x14006000 0x00 0x1000>;
			interrupts = <0x00 0x9c 0x08>;
			clocks = <0x14 0x02>;
			clock-names = "MDP_RSZ0";
			phandle = <0x25>;
		};

		mdp_rsz1@14007000 {
			compatible = "mediatek,mdp_rsz1";
			reg = <0x00 0x14007000 0x00 0x1000>;
			interrupts = <0x00 0x9d 0x08>;
			clocks = <0x14 0x03>;
			clock-names = "MDP_RSZ1";
			phandle = <0x26>;
		};

		mdp_wrot1@14008000 {
			compatible = "mediatek,mdp_wrot1";
			reg = <0x00 0x14008000 0x00 0x1000>;
			interrupts = <0x00 0x9f 0x08>;
			clocks = <0x14 0x06>;
			clock-names = "MDP_WROT1";
			phandle = <0x28>;
		};

		mdp_wrot0@14009000 {
			compatible = "mediatek,mdp_wrot0";
			reg = <0x00 0x14009000 0x00 0x1000>;
			interrupts = <0x00 0xa0 0x08>;
			clocks = <0x14 0x05>;
			clock-names = "MDP_WROT0";
			phandle = <0x27>;
		};

		mdp_tdshp0@1400a000 {
			compatible = "mediatek,mdp_tdshp0";
			reg = <0x00 0x1400a000 0x00 0x1000>;
			clocks = <0x14 0x04>;
			clock-names = "MDP_TDSHP";
			phandle = <0x29>;
		};

		disp_ovl0@1400b000 {
			compatible = "mediatek,disp_ovl0";
			reg = <0x00 0x1400b000 0x00 0x1000>;
			interrupts = <0x00 0xa1 0x08>;
		};

		disp_ovl0_2l@1400c000 {
			compatible = "mediatek,disp_ovl0_2l";
			reg = <0x00 0x1400c000 0x00 0x1000>;
			interrupts = <0x00 0xad 0x08>;
		};

		disp_rdma0@1400d000 {
			compatible = "mediatek,disp_rdma0";
			reg = <0x00 0x1400d000 0x00 0x1000>;
			interrupts = <0x00 0xa2 0x08>;
		};

		disp_wdma0@1400e000 {
			compatible = "mediatek,disp_wdma0";
			reg = <0x00 0x1400e000 0x00 0x1000>;
			interrupts = <0x00 0xa3 0x08>;
		};

		disp_color0@1400f000 {
			compatible = "mediatek,disp_color0";
			reg = <0x00 0x1400f000 0x00 0x1000>;
			interrupts = <0x00 0xa4 0x08>;
			phandle = <0x2a>;
		};

		disp_ccorr0@14010000 {
			compatible = "mediatek,disp_ccorr0";
			reg = <0x00 0x14010000 0x00 0x1000>;
			interrupts = <0x00 0xa5 0x08>;
		};

		disp_aal0@14011000 {
			compatible = "mediatek,disp_aal0";
			reg = <0x00 0x14011000 0x00 0x1000>;
			interrupts = <0x00 0xa6 0x08>;
		};

		disp_gamma0@14012000 {
			compatible = "mediatek,disp_gamma0";
			reg = <0x00 0x14012000 0x00 0x1000>;
			interrupts = <0x00 0xa7 0x08>;
		};

		disp_dither0@14013000 {
			compatible = "mediatek,disp_dither0";
			reg = <0x00 0x14013000 0x00 0x1000>;
			interrupts = <0x00 0xa8 0x08>;
		};

		dsi0@14014000 {
			compatible = "mediatek,dsi0";
			reg = <0x00 0x14014000 0x00 0x1000>;
			interrupts = <0x00 0xa9 0x08>;
		};

		disp_rsz0@14015000 {
			compatible = "mediatek,disp_rsz0";
			reg = <0x00 0x14015000 0x00 0x1000>;
			interrupts = <0x00 0xdc 0x08>;
		};

		disp_rdma1@14016000 {
			compatible = "mediatek,disp_rdma1";
			reg = <0x00 0x14016000 0x00 0x1000>;
			interrupts = <0x00 0xc3 0x08>;
		};

		mdp_rdma1@14017000 {
			compatible = "mediatek,mdp_rdma1";
			reg = <0x00 0x14017000 0x00 0x1000>;
			interrupts = <0x00 0xc4 0x08>;
			clocks = <0x14 0x13>;
			clock-names = "MDP_RDMA1";
			phandle = <0x24>;
		};

		dpi0@14018000 {
			compatible = "mediatek,dpi0";
			reg = <0x00 0x14018000 0x00 0x1000>;
			interrupts = <0x00 0xc5 0x08>;
		};

		lvdstx@14019200 {
			compatible = "mediatek,lvdstx";
			reg = <0x00 0x14019200 0x00 0x100>;
		};

		lvdsana@11c00800 {
			compatible = "mediatek,lvdsana";
			reg = <0x00 0x11c00800 0x00 0x30>;
		};

		mtkfb@0 {
			compatible = "mediatek,mtkfb";
			phandle = <0xbd>;
		};

		dispsys {
			compatible = "mediatek,dispsys";
			mediatek,larb = <0x1d>;
			iommus = <0x55 0x00 0x55 0x01 0x55 0x02 0x55 0x03 0x55 0x04>;
			clocks = <0x14 0x16 0x14 0x17 0x14 0x18 0x14 0x19 0x14 0x07 0x14 0x08 0x14 0x0a 0x14 0x12 0x14 0x0b 0x14 0x0c 0x14 0x0d 0x14 0x0e 0x14 0x0f 0x14 0x10 0x14 0x11 0x14 0x1f 0x14 0x20 0x14 0x09 0x14 0x14 0x14 0x21 0x14 0x22 0x14 0x23 0x13 0x85 0x13 0x86 0x13 0x1b 0x13 0x54 0x12 0x23 0x0b 0x08 0x13 0x5e 0x13 0x23 0x13 0x24 0x13 0x25 0x13 0x26 0x11>;
			clock-names = "MMSYS_SMI_COMMON\0MMSYS_SMI_LARB0\0MMSYS_GALS_COMM0\0MMSYS_GALS_COMM1\0MMSYS_DISP_OVL0\0MMSYS_DISP_OVL0_2L\0MMSYS_DISP_RDMA0\0MMSYS_DISP_RDMA1\0MMSYS_DISP_WDMA0\0MMSYS_DISP_COLOR0\0MMSYS_DISP_CCORR0\0MMSYS_DISP_AAL0\0MMSYS_DISP_GAMMA0\0MMSYS_DISP_DITHER0\0MMSYS_DSI0_MM_CK\0MMSYS_DSI0_IF_CK\0MMSYS_26M\0MMSYS_DISP_RSZ0\0MMSYS_DPI0_DPI0\0MMSYS_DPI0\0MMSYS_LVDSTX_PXL\0MMSYS_LVDSTX_CTS\0TOP_LVDSTX_CLKDIG_EN\0TOP_VPLL_DPIX_EN\0TOP_UNIVPLL2_D4\0TOP_MUX_DISP_PWM\0DISP_PWM\0APMIXED_LVDSPLL\0DPI0_SEL\0TOP_LVDSPLL_D2\0TOP_LVDSPLL_D4\0TOP_LVDSPLL_D8\0TOP_LVDSPLL_D16\0TOP_26M";
			power-domains = <0x21 0x00>;
		};

		dsi_te {
			compatible = "mediatek, DSI_TE-eint";
			status = "disabled";
			phandle = <0xbe>;
		};

		syscon@15000000 {
			compatible = "mediatek,mt8168-imgsys\0syscon";
			reg = <0x00 0x15000000 0x00 0x1000>;
			#clock-cells = <0x01>;
			phandle = <0x15>;
		};

		ispsys@15000000 {
			compatible = "mediatek,mt8168-ispsys";
			reg = <0x00 0x15004000 0x00 0x9000 0x00 0x1500d000 0x00 0x1000 0x00 0x15000000 0x00 0x52000 0x00 0x10215000 0x00 0x3000 0x00 0x10211000 0x00 0x1000 0x00 0x15040000 0x00 0x8000 0x00 0x15050000 0x00 0x2000>;
			interrupts = <0x00 0xb3 0x08 0x00 0xb4 0x08 0x00 0xb5 0x08 0x00 0xba 0x08 0x00 0xbb 0x08>;
			power-domains = <0x21 0x04>;
			mediatek,larb = <0x1f>;
			iommus = <0x55 0x40 0x55 0x41 0x55 0x42 0x55 0x44 0x55 0x45 0x55 0x47 0x55 0x48 0x55 0x4b 0x55 0x4c 0x55 0x4e 0x55 0x4f>;
			clocks = <0x14 0x16 0x14 0x18 0x14 0x19 0x14 0x1b 0x15 0x00 0x15 0x01 0x15 0x02 0x15 0x03 0x15 0x04 0x15 0x05>;
			clock-names = "MMSYS_SMI_COMMON\0MMSYS_SMI_COMM0\0MMSYS_SMI_COMM1\0MMSYS_SMI_IMG\0CAMSYS_LARB2\0CAMSYS_CAM\0CAMSYS_CAMTG\0CAMSYS_SENIF\0CAMSYS_CAMSV0\0CAMSYS_CAMSV1";
			phandle = <0xbf>;
		};

		larb@15001000 {
			compatible = "mediatek,mt8168-smi-larb\0mediatek,mt8183-smi-larb";
			reg = <0x00 0x15001000 0x00 0x1000>;
			mediatek,smi = <0x17>;
			mediatek,larb-id = <0x02>;
			clocks = <0x14 0x1b 0x15 0x00>;
			clock-names = "apb\0smi";
			phandle = <0x1f>;
		};

		fdvt@1500b000 {
			compatible = "mediatek,fdvt";
			reg = <0x00 0x1500b000 0x00 0x1000>;
			interrupts = <0x00 0xb6 0x08>;
			phandle = <0xc0>;
		};

		wpe@1500c000 {
			compatible = "mediatek,mt8168-wpe\0mediatek,wpe";
			reg = <0x00 0x1500c000 0x00 0x1000>;
			interrupts = <0x00 0xbc 0x08>;
			clocks = <0x15 0x07>;
			clock-names = "wpe";
			power-domains = <0x21 0x04>;
			iommus = <0x55 0x51 0x55 0x52 0x55 0x53>;
			mediatek,larb = <0x1f>;
			phandle = <0xc1>;
		};

		kd_camera_hw1@15040000 {
			compatible = "mediatek,camera_hw";
			reg = <0x00 0x15040000 0x00 0x1000>;
			clocks = <0x13 0x44 0x13 0x45 0x13 0x29 0x13 0x34 0x13 0x28 0x13 0x1c 0x13 0x2a 0x13 0x1d 0x13 0x2b 0x15 0x03 0x56 0x00 0x57 0x00 0x58 0x00 0x59 0x00 0x13 0x5d 0x13 0x5b 0x13 0x1a>;
			clock-names = "CLK_TOP_CAMTG_SEL\0CLK_TOP_CAMTG1_SEL\0CLK_MCLK_24M\0CLK_MCLK_26M\0CLK_MCLK_48M\0CLK_MCLK_52M\0CLK_MCLK_12M\0CLK_MCLK_13M\0CLK_MCLK_6M\0CLK_CAM_SENIF_CG\0CLK_MIPI_ANA_0A_CG\0CLK_MIPI_ANA_0B_CG\0CLK_MIPI_ANA_1A_CG\0CLK_MIPI_ANA_1B_CG\0CLK_TOP_CAMTM_SEL_CG\0CLK_TOP_SENIF_SEL_CG\0CLK_TOP_SELIF_SRC_208";
			vcama-supply = <0x5a>;
			vcamd-supply = <0x5b>;
			vcamio-supply = <0x5c>;
			vcama_sub-supply = <0x5a>;
			vcamd_sub-supply = <0x5b>;
			vcamio_sub-supply = <0x5c>;
			pinctrl-names = "default\0cam0_rst0\0cam0_rst1\0cam0_pnd0\0cam0_pnd1\0cam1_rst0\0cam1_rst1\0cam1_pnd0\0cam1_pnd1\0cam0_mclk_on\0cam0_mclk_off\0cam1_mclk_on\0cam1_mclk_off";
			pinctrl-0 = <0x5d>;
			pinctrl-1 = <0x5e>;
			pinctrl-2 = <0x5f>;
			pinctrl-3 = <0x60>;
			pinctrl-4 = <0x61>;
			pinctrl-5 = <0x62>;
			pinctrl-6 = <0x63>;
			pinctrl-7 = <0x64>;
			pinctrl-8 = <0x65>;
			pinctrl-9 = <0x66>;
			pinctrl-10 = <0x67>;
			pinctrl-11 = <0x68>;
			pinctrl-12 = <0x69>;
			status = "okay";
			phandle = <0xc2>;
		};

		vcu@16000000 {
			compatible = "mediatek-vcu";
			mediatek,vcuid = <0x00>;
			mediatek,vcuname = "vcu";
			reg = <0x00 0x16000000 0x00 0x40000 0x00 0x17020000 0x00 0x10000 0x00 0x19002000 0x00 0x1000>;
			mediatek,mailbox-gce = <0x2d>;
			mboxes = <0x2d 0x0d 0x00 0x04 0x2d 0x0e 0x00 0x04>;
			gce-event-names = "vdec_pic_start\0vdec_decode_done\0vdec_pause\0vdec_dec_error\0vdec_mc_busy_overflow_timeout\0vdec_all_dram_req_done\0vdec_ini_fetch_rdy\0vdec_process_flag\0vdec_search_start_code_done\0vdec_ref_reorder_done\0vdec_wp_tble_done\0vdec_count_sram_clr_done\0venc_eof\0venc_cmdq_pause_done\0venc_mb_done\0venc_128B_cnt_done";
			gce-events = <0x2d 0x160 0x2d 0x161 0x2d 0x162 0x2d 0x163 0x2d 0x164 0x2d 0x165 0x2d 0x166 0x2d 0x167 0x2d 0x168 0x2d 0x169 0x2d 0x16a 0x2d 0x16b 0x2d 0x16c 0x2d 0x16d 0x2d 0x16e 0x2d 0x16f>;
			phandle = <0x6a>;
		};

		syscon@16000000 {
			compatible = "mediatek,mt8168-vdecsys\0syscon";
			reg = <0x00 0x16000000 0x00 0x1000>;
			#clock-cells = <0x01>;
			phandle = <0x6b>;
		};

		vdec_gcon@16000000 {
			compatible = "mediatek,vdec_gcon\0syscon";
			reg = <0x00 0x16000000 0x00 0x1000 0x00 0x16025000 0x00 0x1000>;
			mediatek,larb = <0x20>;
			interrupts = <0x00 0xb1 0x08>;
			mediatek,vcu = <0x6a>;
			power-domains = <0x21 0x06>;
			clocks = <0x6b 0x00 0x6b 0x01>;
			clock-names = "hf_hvdec_ck\0hf_flarb1_ck";
			#clock-cells = <0x01>;
			phandle = <0xc3>;
		};

		larb@16010000 {
			compatible = "mediatek,mt8168-smi-larb\0mediatek,mt8183-smi-larb";
			reg = <0x00 0x16010000 0x00 0x1000>;
			mediatek,smi = <0x17>;
			mediatek,larb-id = <0x03>;
			clocks = <0x6b 0x01 0x6b 0x01>;
			clock-names = "apb\0smi";
			phandle = <0x20>;
		};

		venc_gcon@17000000 {
			compatible = "mediatek,venc_gcon";
			reg = <0x00 0x17000000 0x00 0x1000 0x00 0x17020000 0x00 0x1000>;
			mediatek,larb = <0x1e>;
			interrupts = <0x00 0xae 0x08>;
			mediatek,vcu = <0x6a>;
			power-domains = <0x21 0x07>;
			clocks = <0x6c 0x00 0x6c 0x01>;
			clock-names = "MT_CG_VENC\0MT_CG_VENC_JPGENC";
			#clock-cells = <0x01>;
			phandle = <0xc4>;
		};

		syscon@17000000 {
			compatible = "mediatek,mt8168-vencsys\0syscon";
			reg = <0x00 0x17000000 0x00 0x1000>;
			#clock-cells = <0x01>;
			phandle = <0x6c>;
		};

		larb@17010000 {
			compatible = "mediatek,mt8168-smi-larb\0mediatek,mt8183-smi-larb";
			reg = <0x00 0x17010000 0x00 0x1000>;
			mediatek,smi = <0x17>;
			mediatek,larb-id = <0x01>;
			clocks = <0x6c 0x00 0x6c 0x00>;
			clock-names = "apb\0smi";
			phandle = <0x1e>;
		};

		venc@17020000 {
			compatible = "mediatek,venc";
			reg = <0x00 0x17020000 0x00 0x2000>;
		};

		wifi@18000000 {
			compatible = "mediatek,wifi";
			reg = <0x00 0x18000000 0x00 0x100000>;
			interrupts = <0x00 0xd4 0x08>;
			phandle = <0xc5>;
		};

		consys@18002000 {
			compatible = "mediatek,mt8168-consys";
			#address-cells = <0x02>;
			#size-cells = <0x02>;
			reg = <0x00 0x18002000 0x00 0x1000 0x00 0x10007000 0x00 0x100 0x00 0x10001000 0x00 0x1000 0x00 0x10006000 0x00 0x1000 0x00 0x18007000 0x00 0x1000 0x00 0x180b1000 0x00 0x1000 0x00 0x180a3000 0x00 0x1000 0x00 0x180a5000 0x00 0x800 0x00 0x180c1000 0x00 0x1000 0x00 0x18004000 0x00 0x1000>;
			interrupts = <0x00 0xd3 0x08 0x00 0xd5 0x08 0x00 0xd6 0x01>;
			power-domains = <0x21 0x01>;
			resets = <0x6d 0x0c>;
			reset-names = "connsys";
			status = "okay";
			pinctrl-names = "default\0gps_lna_state_init\0gps_lna_state_oh\0gps_lna_state_ol";
			pinctrl-0 = <0x6e>;
			pinctrl-1 = <0x6f>;
			pinctrl-2 = <0x70>;
			pinctrl-3 = <0x71>;
			phandle = <0xc6>;
		};

		vpu@19000000 {
			compatible = "mediatek,mt8168-vpu";
			reg = <0x00 0x19020000 0x00 0x1000>;
			mediatek,vpucore = <0x72>;
			mediatek,larb = <0x20>;
			iommus = <0x55 0x00 0x55 0x01>;
			phandle = <0xc7>;
		};

		apu@19020000 {
			compatible = "mediatek,mt8168-apu\0syscon";
			reg = <0x00 0x19020000 0x00 0x1000>;
			#clock-cells = <0x01>;
			phandle = <0x16>;
		};

		edmc@19030000 {
			compatible = "mtk,edmc";
			reg = <0x00 0x19000000 0x00 0x1000 0x00 0x19030000 0x00 0x1000>;
			interrupts = <0x00 0xd1 0x08>;
			phandle = <0xc8>;
		};

		vpu_core@19100000 {
			compatible = "mediatek,mt8168-vpu-core";
			reg = <0x00 0x19100000 0x00 0x94000>;
			interrupts = <0x00 0xc7 0x08>;
			power-domains = <0x21 0x08>;
			clocks = <0x13 0x67 0x13 0x68 0x13 0x34 0x13 0x16 0x13 0x3c 0x13 0x21 0x13 0x0b 0x13 0x17 0x13 0x07 0x13 0x08 0x12 0x3a 0x14 0x1c 0x16 0x00 0x16 0x01 0x16 0x02 0x16 0x03 0x16 0x04 0x16 0x05>;
			clock-names = "apu_sel\0apu_if_sel\0clk26m_ck\0univpll_d2\0apupll_ck\0mmpll_ck\0syspll_d3\0univpll1_d2\0syspll1_d2\0syspll1_d4\0ifr_apu_axi\0smi_cam\0apu_ipu_ck\0apu_axi\0apu_jtag\0apu_if_ck\0apu_edma\0apu_ahb";
			phandle = <0x72>;
		};

		adsp@1d062000 {
			compatible = "mediatek,audio_dsp";
			reg = <0x00 0x1d062000 0x00 0x1000 0x00 0x1e000000 0x00 0x60000 0x00 0x1e100000 0x00 0x18000>;
			memory-region = <0x73>;
			interrupts = <0x00 0xd0 0x04 0x00 0x35 0x08>;
			power-domains = <0x21 0x05>;
			clocks = <0x13 0x60 0x13 0x34 0x13 0x35 0x13 0x38 0x13 0x39 0x13 0x3a 0x13 0x3b 0x13 0x8c 0x13 0x8b 0x12 0x11>;
			clock-names = "CLK_DSP_SEL\0CLK26M_CK\0AD_SYS_26M_D2\0DSPPLL_CK\0DSPPLL_D2\0DSPPLL_D4\0DSPPLL_D8\0PDN_DSP_26M\0PDN_DSP_32K\0IFR_DSP_UART";
			phandle = <0xc9>;
		};

		gpufreq {
			compatible = "mediatek,mt8168-gpufreq";
			clocks = <0x13 0x42 0x0b 0x03 0x13 0x05 0x13 0x19 0x74 0x00 0x74 0x01>;
			clock-names = "clk_mux\0clk_pll_src\0clk_main_parent\0clk_sub_parent\0subsys_mfg_cg\0subsys_mfg_mbist_diag";
			power-domains = <0x21 0x02>;
		};

		ice_debug {
			compatible = "mediatek,mt8168-ice_debug\0mediatek,mt2701-ice_debug";
			clocks = <0x12 0x20>;
			clock-names = "ice_dbg";
			phandle = <0xca>;
		};

		pseudo-m4u {
			compatible = "mediatek,mtk-pseudo-m4u";
			iommus = <0x55 0x09>;
		};

		led@6 {
			compatible = "mediatek,lcd-backlight";
			led_mode = <0x05>;
			data = <0x01>;
			pwm_config = <0x00 0x00 0x00 0x00 0x00>;
			phandle = <0xcb>;
		};

		mtee {
			compatible = "mediatek,mtee";
			clocks = <0x12 0x1a 0x13 0x65>;
			clock-names = "GCPU\0GCPU_B";
		};

		mt-pmic {
			compatible = "mediatek,mt_pmic";
			interrupt-controller;
			interrupt-parent = <0x32>;
			interrupts = <0x91 0x04>;
			phandle = <0xcc>;

			mt635x-auxadc {
				compatible = "mediatek,mt635x-auxadc";
				#io-channel-cells = <0x01>;
				phandle = <0xcd>;

				batadc {
					channel = <0x00>;
					resistance-ratio = <0x03 0x01>;
					avg-num = <0x80>;
				};

				isense {
					channel = <0x01>;
					resistance-ratio = <0x03 0x01>;
					avg-num = <0x80>;
				};

				vcdt {
					channel = <0x02>;
				};

				bat_temp {
					channel = <0x03>;
					resistance-ratio = <0x01 0x01>;
				};

				chip_temp {
					channel = <0x05>;
				};

				vcore_temp {
					channel = <0x06>;
				};

				vproc_temp {
					channel = <0x07>;
				};

				accdet {
					channel = <0x09>;
				};

				tsx_temp {
					channel = <0x0b>;
					avg-num = <0x80>;
				};

				hpofs_cal {
					channel = <0x0c>;
					avg-num = <0x100>;
				};

				dcxo_temp {
					channel = <0x0d>;
					avg-num = <0x10>;
				};

				vbif {
					channel = <0x0e>;
					resistance-ratio = <0x01 0x01>;
				};
			};

			buck_regulators {

				buck_vs1 {
					regulator-name = "vs1";
					regulator-min-microvolt = <0x124f80>;
					regulator-max-microvolt = <0x2191c0>;
					regulator-ramp-delay = <0x30d4>;
					regulator-enable-ramp-delay = <0xdc>;
					phandle = <0xce>;
				};

				buck_vmodem {
					regulator-name = "vmodem";
					regulator-min-microvolt = <0x7a120>;
					regulator-max-microvolt = <0x123716>;
					regulator-ramp-delay = <0x186a>;
					regulator-enable-ramp-delay = <0xdc>;
					phandle = <0xcf>;
				};

				buck_vcore {
					regulator-name = "vcore";
					regulator-min-microvolt = <0x7ea5e>;
					regulator-max-microvolt = <0x1406f4>;
					regulator-ramp-delay = <0xbb8>;
					regulator-enable-ramp-delay = <0xdc>;
					phandle = <0xd0>;
				};

				buck_vproc {
					regulator-name = "vproc";
					regulator-min-microvolt = <0x7ea5e>;
					regulator-max-microvolt = <0x1406f4>;
					regulator-ramp-delay = <0xfa0>;
					regulator-enable-ramp-delay = <0xdc>;
					phandle = <0x0d>;
				};

				buck_vpa {
					regulator-name = "vpa";
					regulator-min-microvolt = <0x7a120>;
					regulator-max-microvolt = <0x37b1d0>;
					regulator-ramp-delay = <0xc350>;
					regulator-enable-ramp-delay = <0xdc>;
					phandle = <0xd1>;
				};
			};

			pmic_clock_buffer_ctrl {
				compatible = "mediatek,mt6357-clkbuf";
				mediatek,clkbuf-quantity = <0x07>;
				mediatek,clkbuf-config = <0x02 0x00 0x00 0x00 0x00 0x00 0x00>;
				mediatek,clkbuf-driving-current = <0x01 0x01 0x01 0x01 0x01 0x01 0x01>;
				phandle = <0xd2>;
			};

			ldo_regulators {

				ldo_vfe28 {
					compatible = "regulator-fixed";
					regulator-name = "vfe28";
					regulator-min-microvolt = <0x2ab980>;
					regulator-max-microvolt = <0x2ab980>;
					regulator-enable-ramp-delay = <0x108>;
					phandle = <0xd3>;
				};

				ldo_vxo22 {
					regulator-name = "vxo22";
					regulator-min-microvolt = <0x2191c0>;
					regulator-max-microvolt = <0x249f00>;
					regulator-enable-ramp-delay = <0x6e>;
					phandle = <0xd4>;
				};

				ldo_vrf18 {
					compatible = "regulator-fixed";
					regulator-name = "vrf18";
					regulator-min-microvolt = <0x1b7740>;
					regulator-max-microvolt = <0x1b7740>;
					regulator-enable-ramp-delay = <0x6e>;
					phandle = <0xd5>;
				};

				ldo_vrf12 {
					compatible = "regulator-fixed";
					regulator-name = "vrf12";
					regulator-min-microvolt = <0x124f80>;
					regulator-max-microvolt = <0x124f80>;
					regulator-enable-ramp-delay = <0x6e>;
					phandle = <0xd6>;
				};

				ldo_vefuse {
					regulator-name = "vefuse";
					regulator-min-microvolt = <0x124f80>;
					regulator-max-microvolt = <0x325aa0>;
					regulator-enable-ramp-delay = <0x108>;
					phandle = <0xd7>;
				};

				ldo_vcn33_bt {
					regulator-name = "vcn33_bt";
					regulator-min-microvolt = <0x325aa0>;
					regulator-max-microvolt = <0x3567e0>;
					regulator-enable-ramp-delay = <0x108>;
					phandle = <0xd8>;
				};

				ldo_vcn33_wifi {
					regulator-name = "vcn33_wifi";
					regulator-min-microvolt = <0x325aa0>;
					regulator-max-microvolt = <0x3567e0>;
					regulator-enable-ramp-delay = <0x108>;
					phandle = <0xd9>;
				};

				ldo_vcn28 {
					compatible = "regulator-fixed";
					regulator-name = "vcn28";
					regulator-min-microvolt = <0x2ab980>;
					regulator-max-microvolt = <0x2ab980>;
					regulator-enable-ramp-delay = <0x108>;
					phandle = <0x19>;
				};

				ldo_vcn18 {
					compatible = "regulator-fixed";
					regulator-name = "vcn18";
					regulator-min-microvolt = <0x1b7740>;
					regulator-max-microvolt = <0x1b7740>;
					regulator-enable-ramp-delay = <0x108>;
					phandle = <0xda>;
				};

				ldo_vcama {
					regulator-name = "vcama";
					regulator-min-microvolt = <0x2625a0>;
					regulator-max-microvolt = <0x2ab980>;
					regulator-enable-ramp-delay = <0x108>;
					phandle = <0x5a>;
				};

				ldo_vcamd {
					regulator-name = "vcamd";
					regulator-min-microvolt = <0xf4240>;
					regulator-max-microvolt = <0x1b7740>;
					regulator-enable-ramp-delay = <0x108>;
					phandle = <0x5b>;
				};

				ldo_vcamio {
					compatible = "regulator-fixed";
					regulator-name = "vcamio";
					regulator-min-microvolt = <0x1b7740>;
					regulator-max-microvolt = <0x1b7740>;
					regulator-enable-ramp-delay = <0x108>;
					phandle = <0x5c>;
				};

				ldo_vldo28 {
					regulator-name = "vldo28";
					regulator-min-microvolt = <0x2ab980>;
					regulator-max-microvolt = <0x2dc6c0>;
					regulator-enable-ramp-delay = <0x108>;
					phandle = <0x39>;
				};

				ldo_vsram_others {
					regulator-name = "vsram_others";
					regulator-min-microvolt = <0x7ea5e>;
					regulator-max-microvolt = <0x1406f4>;
					regulator-ramp-delay = <0x186a>;
					regulator-enable-ramp-delay = <0x6e>;
					phandle = <0xdb>;
				};

				ldo_vsram_proc {
					regulator-name = "vsram_proc";
					regulator-min-microvolt = <0x7ea5e>;
					regulator-max-microvolt = <0x1406f4>;
					regulator-ramp-delay = <0x186a>;
					regulator-enable-ramp-delay = <0x6e>;
					phandle = <0x0e>;
				};

				ldo_vaux18 {
					compatible = "regulator-fixed";
					regulator-name = "vaux18";
					regulator-min-microvolt = <0x1b7740>;
					regulator-max-microvolt = <0x1b7740>;
					regulator-enable-ramp-delay = <0x108>;
					phandle = <0xdc>;
				};

				ldo_vaud28 {
					compatible = "regulator-fixed";
					regulator-name = "vaud28";
					regulator-min-microvolt = <0x2ab980>;
					regulator-max-microvolt = <0x2ab980>;
					regulator-enable-ramp-delay = <0x108>;
					phandle = <0xdd>;
				};

				ldo_vio28 {
					compatible = "regulator-fixed";
					regulator-name = "vio28";
					regulator-min-microvolt = <0x2ab980>;
					regulator-max-microvolt = <0x2ab980>;
					regulator-enable-ramp-delay = <0x108>;
					phandle = <0xde>;
				};

				ldo_vio18 {
					compatible = "regulator-fixed";
					regulator-name = "vio18";
					regulator-min-microvolt = <0x1b7740>;
					regulator-max-microvolt = <0x1b7740>;
					regulator-enable-ramp-delay = <0x108>;
					phandle = <0x4e>;
				};

				ldo_vdram {
					regulator-name = "vdram";
					regulator-min-microvolt = <0x10c8e0>;
					regulator-max-microvolt = <0x124f80>;
					regulator-enable-ramp-delay = <0xce4>;
					regulator-default-on = <0x01>;
					phandle = <0xdf>;
				};

				ldo_vmc {
					regulator-name = "vmc";
					regulator-min-microvolt = <0x1b7740>;
					regulator-max-microvolt = <0x2dc6c0>;
					regulator-enable-ramp-delay = <0x2c>;
					phandle = <0x53>;
				};

				ldo_vmch {
					regulator-name = "vmch";
					regulator-min-microvolt = <0x2c4020>;
					regulator-max-microvolt = <0x2dc6c0>;
					regulator-enable-ramp-delay = <0x2c>;
					phandle = <0x52>;
				};

				ldo_vemc {
					regulator-name = "vemc";
					regulator-min-microvolt = <0x2c4020>;
					regulator-max-microvolt = <0x2dc6c0>;
					regulator-enable-ramp-delay = <0x2c>;
					phandle = <0x4d>;
				};

				ldo_vsim1 {
					regulator-name = "vsim1";
					regulator-min-microvolt = <0x1b7740>;
					regulator-max-microvolt = <0x1b7740>;
					regulator-enable-ramp-delay = <0x108>;
					regulator-boot-on;
					phandle = <0x78>;
				};

				ldo_vsim2 {
					regulator-name = "vsim2";
					regulator-min-microvolt = <0x19f0a0>;
					regulator-max-microvolt = <0x2f4d60>;
					regulator-enable-ramp-delay = <0x108>;
					phandle = <0xe0>;
				};

				ldo_vibr {
					regulator-name = "vibr";
					regulator-min-microvolt = <0x124f80>;
					regulator-max-microvolt = <0x325aa0>;
					regulator-enable-ramp-delay = <0x2c>;
					phandle = <0xe1>;
				};

				ldo_vusb33 {
					regulator-name = "vusb33";
					regulator-min-microvolt = <0x2dc6c0>;
					regulator-max-microvolt = <0x2f4d60>;
					regulator-enable-ramp-delay = <0x108>;
					phandle = <0x48>;
				};
			};
		};

		mmdvfs_pmqos {
			compatible = "mediatek,mmdvfs_pmqos";
			mm_step0 = <0x1c9 0x02 0x06 0x1193b1>;
			mm_step1 = <0x140 0x02 0x06 0xc4ec4>;
			mm_step2 = <0xc8 0x02 0x06 0x7b13b>;
			vopp_steps = <0x00 0x01 0x02>;
			disp_freq = "mm_step0\0mm_step1\0mm_step2";
			mdp_freq = "mm_step0\0mm_step1\0mm_step2";
			cam_freq = "mm_step0\0mm_step1\0mm_step2";
			vdec_freq = "mm_step0\0mm_step1\0mm_step2";
			venc_freq = "mm_step0\0mm_step1\0mm_step2";
			clocks = <0x13 0x40 0x13 0x21 0x13 0x08 0x0b 0x05>;
			clock-names = "mmdvfs_clk_mm_sel_ck\0mmdvfs_clk_mmpll_ck\0mmdvfs_clk_syspll1_d4_ck\0mmdvfs_clk_mmpll";
		};

		accdet@ {
			compatible = "mediatek,pmic-accdet";
			hp-sw1-pin = <0x32 0x7f 0x01>;
			mic_voltage_delay = <0x78>;
			switch-mode-vol = <0x209>;
			accdet-mic-vol = <0x06>;
			headset-mode-setting = <0x500 0x500 0x01 0x1f0 0x800 0x800 0x20 0x44>;
			accdet-plugout-debounce = <0x01>;
			accdet-mic-mode = <0x01>;
			headset-eint-level-pol = <0x08>;
			headset-three-key-threshold = <0x00 0x50 0xdc 0x190>;
			headset-three-key-threshold-CDD = <0x00 0x79 0xc0 0x258>;
			headset-four-key-threshold = <0x00 0x3a 0x79 0xc0 0x190>;
			pinctrl-names = "default\0state_eint_as_int";
			pinctrl-0 = <0x75>;
			pinctrl-1 = <0x76>;
			status = "okay";
			phandle = <0xe2>;
		};

		touch@ {
			compatible = "mediatek,mt8168-touch";
			status = "okay";
			vtouch-supply = <0x39>;
			tpd-resolution = <0x320 0x500>;
			use-tpd-button = <0x00>;
			tpd-key-num = <0x03>;
			tpd-key-local = <0x8b 0xac 0x9e 0x00>;
			tpd-key-dim-local = <0x5a 0x373 0x64 0x28 0xe6 0x373 0x64 0x28 0x172 0x373 0x64 0x28 0x00 0x00 0x00 0x00>;
			tpd-max-touch-num = <0x05>;
			tpd-filter-enable = <0x01>;
			tpd-filter-pixel-density = <0x7c>;
			tpd-filter-custom-prameters = <0x00 0x00 0x00 0x00 0x00 0x00 0x00 0x00 0x00 0x00 0x00 0x00>;
			tpd-filter-custom-speed = <0x00 0x00 0x00>;
			pinctrl-names = "default\0state_eint_as_int\0state_eint_output0\0state_eint_output1\0state_rst_output0\0state_rst_output1";
			pinctrl-0 = <0x3a>;
			pinctrl-1 = <0x3b>;
			pinctrl-2 = <0x3c>;
			pinctrl-3 = <0x3d>;
			pinctrl-4 = <0x3e>;
			pinctrl-5 = <0x3f>;
			phandle = <0xe3>;
		};

		spower {
			compatible = "mediatek,mt8168-spower";
			nvmem-cells = <0x43 0x77>;
			nvmem-cell-names = "spower_calibration\0spower_leakage";
			phandle = <0xe4>;
		};
	};

	firmware {
		phandle = <0xe5>;

		android {
			compatible = "android,firmware";
			phandle = <0xe6>;

			fstab {
				compatible = "android,fstab";
				phandle = <0xe7>;

				vendor {
					compatible = "android,vendor";
					dev = "/dev/block/platform/soc/11230000.mmc/by-name/vendor";
					type = "ext4";
					mnt_flags = "ro";
					fsmgr_flags = "wait,verify";
				};
			};
		};
	};

	mtcpufreq {
		compatible = "mediatek,mt8168-cpufreq";
	};

	odm {
		compatible = "simple-bus";
		phandle = <0xe8>;

		extcon_usb_typec {
			compatible = "linux,extcon-usb-typec";
			phandle = <0x0f>;
		};

		mt_soc_codec_name {
			compatible = "mediatek,mt_soc_codec_63xx";
			use_hp_depop_flow = <0x00>;
			use_ul_260k = <0x00>;
			phandle = <0xe9>;
		};

		lcm@0 {
			compatible = "jd,jd936x_inx_inx";
			reg-lcm-supply = <0x78>;
			vendor_id = <0x02>;
			pinctrl-names = "lcm_pins_rst0\0lcm_pins_rst1\0lcm_pins_bl0\0lcm_pins_bl1";
			pinctrl-0 = <0x79>;
			pinctrl-1 = <0x7a>;
			pinctrl-2 = <0x7b>;
			pinctrl-3 = <0x7c>;
			phandle = <0xea>;
		};

		lcm@1 {
			compatible = "jd,jd936x_kd_hsd";
			reg-lcm-supply = <0x78>;
			vendor_id = <0x03>;
			pinctrl-names = "lcm_pins_rst0\0lcm_pins_rst1\0lcm_pins_bl0\0lcm_pins_bl1";
			pinctrl-0 = <0x79>;
			pinctrl-1 = <0x7a>;
			pinctrl-2 = <0x7b>;
			pinctrl-3 = <0x7c>;
			phandle = <0xeb>;
		};

		lcm@2 {
			compatible = "jd,jd936x_tg_boe";
			reg-lcm-supply = <0x78>;
			vendor_id = <0x05>;
			pinctrl-names = "lcm_pins_rst0\0lcm_pins_rst1\0lcm_pins_bl0\0lcm_pins_bl1";
			pinctrl-0 = <0x79>;
			pinctrl-1 = <0x7a>;
			pinctrl-2 = <0x7b>;
			pinctrl-3 = <0x7c>;
			phandle = <0xec>;
		};

		rt-pd-manager {
			compatible = "mediatek,rt-pd-manager";
		};

		sound {
			compatible = "mediatek,mt8168-onyx";
			mediatek,platform = <0x7d>;
			mediatek,adsp-platform = <0x7e>;
			pinctrl-names = "aud_mosi_on\0aud_mosi_off\0aud_miso_on\0aud_miso_off\0default\0aud_dmic\0aud_pcm\0aud_i2s0\0aud_i2s1\0aud_i2s2\0aud_i2s3\0aud_tdm_out\0aud_tdm_in";
			pinctrl-0 = <0x7f>;
			pinctrl-1 = <0x80>;
			pinctrl-2 = <0x81>;
			pinctrl-3 = <0x82>;
			pinctrl-4 = <0x83>;
			pinctrl-5 = <0x84>;
			pinctrl-6 = <0x85>;
			pinctrl-7 = <0x86>;
			pinctrl-8 = <0x87>;
			pinctrl-9 = <0x88>;
			pinctrl-10 = <0x89>;
			pinctrl-11 = <0x8a>;
			pinctrl-12 = <0x8b>;
			tab-spk-en-gpio = <0x32 0x44 0x00>;
			spk-pa-5v-en-gpio = <0x32 0x4b 0x00>;
			apa-sdn-gpio = <0x32 0x4c 0x00>;
			spk-pa-gain1-gpio = <0x32 0x47 0x00>;
			spk-pa-gain2-gpio = <0x32 0x45 0x00>;
			mediatek,ext-spk-amp-warmup-time-us = <0xd6d8>;
			mediatek,ext-spk-amp-vdd-on-time-us = <0x3e8>;
			status = "okay";
			phandle = <0xed>;
		};

		hall_sensors {
			compatible = "will,hall-wh2509f";
			interrupt-parent = <0x32>;
			interrupts = <0x09 0x08>;
			int-gpio = <0x32 0x09 0x00>;
			sensor-name = "hall_sensor_1";
			sensor-num = <0x01>;
		};

		thermal-sensor {
			compatible = "generic-adc-thermal";
			#thermal-sensor-cells = <0x00>;
			io-channels = <0x02 0x00 0x02 0x03 0x02 0x05>;
			io-channel-names = "sensor-channel";

			auxadc_0 {
				pull_up_r = <0x5f370>;
				over_critical_low = <0x43183f>;
				pull_up_voltage = <0x708>;
				ntc_table = <0x07>;
				adc_channel = <0x00>;
				temperature_r = <0x00>;
				channel_name = "mtkts_bts0";
			};

			auxadc_3 {
				pull_up_r = <0x5f370>;
				over_critical_low = <0x43183f>;
				pull_up_voltage = <0x708>;
				ntc_table = <0x07>;
				adc_channel = <0x03>;
				temperature_r = <0x00>;
				channel_name = "mtkts_bts1";
			};

			auxadc_5 {
				pull_up_r = <0x5f370>;
				over_critical_low = <0x43183f>;
				pull_up_voltage = <0x708>;
				ntc_table = <0x07>;
				adc_channel = <0x05>;
				temperature_r = <0x00>;
				channel_name = "mtkts_bts2";
			};
		};

		vs1_wire {
			compatible = "amazon,vs1_wire\0simple-bus";
			status = "okay";
			phandle = <0xee>;

			virtual_sensor@0 {
				compatible = "amazon,virtual_sensor-thermal";
				dev_id = <0x00>;
				num_trips = <0x09>;
				mode = <0x00>;
				polling_delay = <0xbb8>;
				governor_name = "virtual_sensor";
				num_tbps = <0x03>;
				temp = <0xabe0 0xadd4 0xafc8 0xb1bc 0xbf68 0xc738 0xcf08 0xd2f0 0xdac0 0xdac0 0xdac0 0xdac0>;
				type = <0x00 0x00 0x00 0x00 0x00 0x00 0x00 0x00 0x03 0x03 0x03 0x03>;
				hyst = <0xbb8 0x00 0x00 0x00 0x00 0x00 0x00 0xbb8 0x00 0x00 0x00 0x00>;
				num_cdevs = <0x02>;
				cdev_names = "thermal_budget0\0lcd-backlight0";
			};

			backlight@0 {
				compatible = "amazon,backlight_cooler";
				type = "lcd-backlight0";
				state = <0x00>;
				max_state = <0x0c>;
				level = <0xff>;
				thermal_cooler_id = <0x01>;
				levels = <0xff 0xff 0xff 0xdc 0xc8 0xaf 0xaf 0xaf 0xaf 0xaf 0xaf 0xaf>;
			};

			thermal_budget@0 {
				compatible = "amazon,thermal_budget_cooler";
				type = "thermal_budget0";
				state = <0x00>;
				max_state = <0x0c>;
				level = <0x11f8>;
				thermal_cooler_id = <0x02>;
				levels = <0x3ad 0x34e 0x2c3 0x271 0x229 0x1b9 0x174 0xeb 0xeb 0xeb 0xeb 0xeb>;
			};

			thermal_battery@0 {
				compatible = "amazon,virtual_sensor_thermal_sensor";
				thermal_sensor,offset = <0x13b0>;
				thermal_sensor,offset_invert = <0x00>;
				thermal_sensor,alpha = <0x2d6>;
				thermal_sensor,weight = <0xe4>;
				thermal_sensor,weight_invert = <0x00>;
				thermal_sensor_id = <0x01>;
				aux_channel_num = <0x00>;
				select_device = <0x00>;
			};

			thermal_pmic@0 {
				compatible = "amazon,virtual_sensor_thermal_sensor";
				thermal_sensor,offset = <0xc418>;
				thermal_sensor,alpha = <0x1a1>;
				thermal_sensor,weight = <0x00>;
				thermal_sensor,weight_invert = <0x00>;
				thermal_sensor,offset_invert = <0x00>;
				thermal_sensor_id = <0x03>;
				aux_channel_num = <0x00>;
				select_device = <0x00>;
			};

			thermistor@00 {
				compatible = "amazon,virtual_sensor_thermal_sensor";
				thermal_sensor,offset = <0x3138>;
				thermal_sensor,offset_invert = <0x01>;
				thermal_sensor,alpha = <0x01>;
				thermal_sensor,weight = <0xf0>;
				thermal_sensor,weight_invert = <0x00>;
				thermal_sensor_id = <0x05>;
				aux_channel_num = <0x00>;
				select_device = <0x00>;
			};

			thermistor@01 {
				compatible = "amazon,virtual_sensor_thermal_sensor";
				thermal_sensor,offset = <0x477c>;
				thermal_sensor,offset_invert = <0x00>;
				thermal_sensor,alpha = <0x14a>;
				thermal_sensor,weight = <0xa0>;
				thermal_sensor,weight_invert = <0x00>;
				thermal_sensor_id = <0x05>;
				aux_channel_num = <0x01>;
				select_device = <0x00>;
			};

			thermistor@02 {
				compatible = "amazon,virtual_sensor_thermal_sensor";
				thermal_sensor,offset = <0x40d8>;
				thermal_sensor,offset_invert = <0x01>;
				thermal_sensor,alpha = <0xe8>;
				thermal_sensor,weight = <0x101>;
				thermal_sensor,weight_invert = <0x00>;
				thermal_sensor_id = <0x05>;
				aux_channel_num = <0x02>;
				select_device = <0x00>;
			};
		};

		vs1_wpc {
			compatible = "amazon,vs1_wpc\0simple-bus";
			status = "disabled";
			phandle = <0xef>;

			virtual_sensor@0 {
				compatible = "amazon,virtual_sensor-thermal";
				dev_id = <0x00>;
				num_trips = <0x09>;
				mode = <0x00>;
				polling_delay = <0xbb8>;
				governor_name = "virtual_sensor";
				num_tbps = <0x03>;
				temp = <0xabe0 0xadd4 0xafc8 0xb1bc 0xbf68 0xc738 0xcf08 0xd2f0 0xdac0 0xdac0 0xdac0 0xdac0>;
				type = <0x00 0x00 0x00 0x00 0x00 0x00 0x00 0x00 0x03 0x03 0x03 0x03>;
				hyst = <0xbb8 0x00 0x00 0x00 0x00 0x00 0x00 0xbb8 0x00 0x00 0x00 0x00>;
				num_cdevs = <0x02>;
				cdev_names = "thermal_budget0\0lcd-backlight0";
			};

			backlight@0 {
				compatible = "amazon,backlight_cooler";
				type = "lcd-backlight0";
				state = <0x00>;
				max_state = <0x0c>;
				level = <0xff>;
				thermal_cooler_id = <0x01>;
				levels = <0xff 0xff 0xff 0xdc 0xc8 0xaf 0xaf 0xaf 0xaf 0xaf 0xaf 0xaf>;
			};

			thermal_budget@0 {
				compatible = "amazon,thermal_budget_cooler";
				type = "thermal_budget0";
				state = <0x00>;
				max_state = <0x0c>;
				level = <0x11f8>;
				thermal_cooler_id = <0x02>;
				levels = <0x3ad 0x34e 0x2c3 0x271 0x229 0x1b9 0x174 0xeb 0xeb 0xeb 0xeb 0xeb>;
			};

			thermal_battery@0 {
				compatible = "amazon,virtual_sensor_thermal_sensor";
				thermal_sensor,offset = <0x7404>;
				thermal_sensor,offset_invert = <0x00>;
				thermal_sensor,alpha = <0x3e8>;
				thermal_sensor,weight = <0xe2>;
				thermal_sensor,weight_invert = <0x00>;
				thermal_sensor_id = <0x01>;
				aux_channel_num = <0x00>;
				select_device = <0x00>;
			};

			thermal_pmic@0 {
				compatible = "amazon,virtual_sensor_thermal_sensor";
				thermal_sensor,offset = <0xdb88>;
				thermal_sensor,alpha = <0x01>;
				thermal_sensor,weight = <0x3b>;
				thermal_sensor,weight_invert = <0x01>;
				thermal_sensor,offset_invert = <0x00>;
				thermal_sensor_id = <0x03>;
				aux_channel_num = <0x00>;
				select_device = <0x00>;
			};

			thermistor@00 {
				compatible = "amazon,virtual_sensor_thermal_sensor";
				thermal_sensor,offset = <0xc738>;
				thermal_sensor,offset_invert = <0x00>;
				thermal_sensor,alpha = <0x01>;
				thermal_sensor,weight = <0x00>;
				thermal_sensor,weight_invert = <0x00>;
				thermal_sensor_id = <0x05>;
				aux_channel_num = <0x00>;
				select_device = <0x00>;
			};

			thermistor@01 {
				compatible = "amazon,virtual_sensor_thermal_sensor";
				thermal_sensor,offset = <0x263e>;
				thermal_sensor,offset_invert = <0x01>;
				thermal_sensor,alpha = <0x25f>;
				thermal_sensor,weight = <0x2ce>;
				thermal_sensor,weight_invert = <0x00>;
				thermal_sensor_id = <0x05>;
				aux_channel_num = <0x01>;
				select_device = <0x00>;
			};

			thermistor@02 {
				compatible = "amazon,virtual_sensor_thermal_sensor";
				thermal_sensor,offset = <0xd160>;
				thermal_sensor,offset_invert = <0x00>;
				thermal_sensor,alpha = <0x93>;
				thermal_sensor,weight = <0x00>;
				thermal_sensor,weight_invert = <0x00>;
				thermal_sensor_id = <0x05>;
				aux_channel_num = <0x02>;
				select_device = <0x00>;
			};
		};

		vs2_wire {
			compatible = "amazon,vs2_wire\0simple-bus";
			status = "okay";
			phandle = <0xf0>;

			virtual_sensor@1 {
				compatible = "amazon,virtual_sensor-thermal";
				dev_id = <0x01>;
				num_trips = <0x09>;
				mode = <0x00>;
				polling_delay = <0xbb8>;
				governor_name = "virtual_sensor";
				num_tbps = <0x03>;
				temp = <0xbb80 0xbd74 0xbf68 0xc350 0xcf08 0xdac0 0xdea8 0xe290 0xea60 0xea60 0xea60 0xea60>;
				type = <0x00 0x00 0x00 0x00 0x00 0x00 0x00 0x00 0x03 0x03 0x03 0x03>;
				hyst = <0xbb8 0x00 0x00 0x00 0xbb8 0x00 0x00 0xbb8 0x00 0x00 0x00 0x00>;
				num_cdevs = <0x02>;
				cdev_names = "thermal_budget1\0bcct1";
			};

			bcct@1 {
				compatible = "amazon,battery_current_cooler";
				type = "bcct1";
				state = <0x00>;
				max_state = <0x0c>;
				level = <0x4e201>;
				thermal_cooler_id = <0x00>;
				levels = <0x186a0 0x186a0 0x186a0 0x2710 0x2710 0x2710 0x2710 0x2710 0x2710 0x2710 0x2710 0x2710>;
			};

			thermal_budget@1 {
				compatible = "amazon,thermal_budget_cooler";
				type = "thermal_budget1";
				state = <0x00>;
				max_state = <0x0c>;
				level = <0x11f8>;
				thermal_cooler_id = <0x02>;
				levels = <0x3ad 0x34e 0x2c3 0x271 0x229 0x1b9 0x174 0xeb 0xeb 0xeb 0xeb 0xeb>;
			};

			thermal_battery@1 {
				compatible = "amazon,virtual_sensor_thermal_sensor";
				thermal_sensor,offset = <0x2ee0>;
				thermal_sensor,offset_invert = <0x00>;
				thermal_sensor,alpha = <0x0d>;
				thermal_sensor,weight = <0x10d>;
				thermal_sensor,weight_invert = <0x00>;
				thermal_sensor_id = <0x01>;
				aux_channel_num = <0x00>;
				select_device = <0x01>;
			};

			thermal_pmic@1 {
				compatible = "amazon,virtual_sensor_thermal_sensor";
				thermal_sensor,offset = <0xae9c>;
				thermal_sensor,alpha = <0x3e8>;
				thermal_sensor,weight = <0x1d>;
				thermal_sensor,weight_invert = <0x00>;
				thermal_sensor,offset_invert = <0x00>;
				thermal_sensor_id = <0x03>;
				aux_channel_num = <0x00>;
				select_device = <0x01>;
			};

			thermistor@10 {
				compatible = "amazon,virtual_sensor_thermal_sensor";
				thermal_sensor,offset = <0x4b64>;
				thermal_sensor,offset_invert = <0x01>;
				thermal_sensor,alpha = <0x3e8>;
				thermal_sensor,weight = <0x1cc>;
				thermal_sensor,weight_invert = <0x00>;
				thermal_sensor_id = <0x05>;
				aux_channel_num = <0x00>;
				select_device = <0x01>;
			};

			thermistor@11 {
				compatible = "amazon,virtual_sensor_thermal_sensor";
				thermal_sensor,offset = <0xb8c4>;
				thermal_sensor,offset_invert = <0x00>;
				thermal_sensor,alpha = <0x12e>;
				thermal_sensor,weight = <0x00>;
				thermal_sensor,weight_invert = <0x00>;
				thermal_sensor_id = <0x05>;
				aux_channel_num = <0x01>;
				select_device = <0x01>;
			};

			thermistor@12 {
				compatible = "amazon,virtual_sensor_thermal_sensor";
				thermal_sensor,offset = <0x3afc>;
				thermal_sensor,offset_invert = <0x00>;
				thermal_sensor,alpha = <0x2e6>;
				thermal_sensor,weight = <0x139>;
				thermal_sensor,weight_invert = <0x00>;
				thermal_sensor_id = <0x05>;
				aux_channel_num = <0x02>;
				select_device = <0x01>;
			};
		};

		vs2_wpc {
			compatible = "amazon,vs2_wpc\0simple-bus";
			status = "disabled";
			phandle = <0xf1>;

			virtual_sensor@1 {
				compatible = "amazon,virtual_sensor-thermal";
				dev_id = <0x01>;
				num_trips = <0x09>;
				mode = <0x00>;
				polling_delay = <0xbb8>;
				governor_name = "virtual_sensor";
				num_tbps = <0x03>;
				temp = <0xbb80 0xbd74 0xbf68 0xc350 0xcf08 0xdac0 0xdea8 0xe290 0xea60 0xea60 0xea60 0xea60>;
				type = <0x00 0x00 0x00 0x00 0x00 0x00 0x00 0x00 0x03 0x03 0x03 0x03>;
				hyst = <0xbb8 0x00 0x00 0x00 0xbb8 0x00 0x00 0xbb8 0x00 0x00 0x00 0x00>;
				num_cdevs = <0x02>;
				cdev_names = "thermal_budget1\0bcct1";
			};

			bcct@1 {
				compatible = "amazon,battery_current_cooler";
				type = "bcct1";
				state = <0x00>;
				max_state = <0x0c>;
				level = <0x4e201>;
				thermal_cooler_id = <0x00>;
				levels = <0x186a0 0x186a0 0x186a0 0x2710 0x2710 0x2710 0x2710 0x2710 0x2710 0x2710 0x2710 0x2710>;
			};

			thermal_budget@1 {
				compatible = "amazon,thermal_budget_cooler";
				type = "thermal_budget1";
				state = <0x00>;
				max_state = <0x0c>;
				level = <0x11f8>;
				thermal_cooler_id = <0x02>;
				levels = <0x3ad 0x34e 0x2c3 0x271 0x229 0x1b9 0x174 0xeb 0xeb 0xeb 0xeb 0xeb>;
			};

			thermal_battery@1 {
				compatible = "amazon,virtual_sensor_thermal_sensor";
				thermal_sensor,offset = <0x956>;
				thermal_sensor,offset_invert = <0x00>;
				thermal_sensor,alpha = <0x3e8>;
				thermal_sensor,weight = <0x19e>;
				thermal_sensor,weight_invert = <0x00>;
				thermal_sensor_id = <0x01>;
				aux_channel_num = <0x00>;
				select_device = <0x01>;
			};

			thermal_pmic@1 {
				compatible = "amazon,virtual_sensor_thermal_sensor";
				thermal_sensor,offset = <0x8854>;
				thermal_sensor,alpha = <0x3e8>;
				thermal_sensor,weight = <0x49>;
				thermal_sensor,weight_invert = <0x00>;
				thermal_sensor,offset_invert = <0x00>;
				thermal_sensor_id = <0x03>;
				aux_channel_num = <0x00>;
				select_device = <0x01>;
			};

			thermistor@10 {
				compatible = "amazon,virtual_sensor_thermal_sensor";
				thermal_sensor,offset = <0xc738>;
				thermal_sensor,offset_invert = <0x00>;
				thermal_sensor,alpha = <0x01>;
				thermal_sensor,weight = <0x00>;
				thermal_sensor,weight_invert = <0x00>;
				thermal_sensor_id = <0x05>;
				aux_channel_num = <0x00>;
				select_device = <0x01>;
			};

			thermistor@11 {
				compatible = "amazon,virtual_sensor_thermal_sensor";
				thermal_sensor,offset = <0x797c>;
				thermal_sensor,offset_invert = <0x00>;
				thermal_sensor,alpha = <0x3e8>;
				thermal_sensor,weight = <0x78>;
				thermal_sensor,weight_invert = <0x00>;
				thermal_sensor_id = <0x05>;
				aux_channel_num = <0x01>;
				select_device = <0x01>;
			};

			thermistor@12 {
				compatible = "amazon,virtual_sensor_thermal_sensor";
				thermal_sensor,offset = <0x39d0>;
				thermal_sensor,offset_invert = <0x01>;
				thermal_sensor,alpha = <0x37d>;
				thermal_sensor,weight = <0x1b5>;
				thermal_sensor,weight_invert = <0x00>;
				thermal_sensor_id = <0x05>;
				aux_channel_num = <0x02>;
				select_device = <0x01>;
			};
		};

		integrity-module {
			compatible = "amzn,integrity-module";
			status = "okay";
		};

		keycombo@1 {
			compatible = "amzn,keycombo";
			keys_down = "KEY_POWER";
			keys_down_delay = <0x1770>;
			keys_down_func = <0x01>;
			status = "okay";
		};
	};

	__symbols__ {
		chosen = "/chosen";
		bat_gm30 = "/battery";
		cluster0_opp = "/opp_table0";
		cpus = "/cpus";
		cluster0 = "/cpus/cpu-map/cluster0";
		cpu0 = "/cpus/cpu@0";
		cpu1 = "/cpus/cpu@1";
		cpu2 = "/cpus/cpu@2";
		cpu3 = "/cpus/cpu@3";
		MCDI_CPU = "/cpus/idle-states/mcdi-cpu";
		MCDI_CLUSTER = "/cpus/idle-states/mcdi-cluster";
		DPIDLE = "/cpus/idle-states/dpidle";
		mt_charger = "/mt_charger";
		lk_charger = "/lk_charger";
		charger = "/charger";
		reserved_memory = "/reserved-memory";
		adsp_reserved = "/reserved-memory/adsp-reserved-memory@50000000";
		atf_reserved_memory = "/reserved-memory/atf-reserved-memory";
		clkao = "/clkao";
		clk26m = "/clocks/clk26m";
		clk32k = "/clocks/clk32k";
		uart_clk = "/clocks/dummy26m";
		timer = "/timer";
		chipid = "/soc/chipid@08000000";
		gic = "/soc/interrupt-controller@c000000";
		topckgen = "/soc/topckgen@10000000";
		infracfg = "/soc/infracfg@10001000";
		syscfg_pctl_a = "/soc/syscfg_pctl_a@10005000";
		scpsys = "/soc/syscon@10006000";
		toprgu = "/soc/toprgu@10007000";
		gpt = "/soc/apxgpt@10008000";
		pio = "/soc/pinctrl@1000b000";
		alsps_intpin_cfg = "/soc/pinctrl@1000b000/alspspincfg";
		alsps_intpin_default = "/soc/pinctrl@1000b000/alspsdefaultcfg";
		consys_pins_default = "/soc/pinctrl@1000b000/consys_default";
		gpslna_pins_init = "/soc/pinctrl@1000b000/gpslna@0";
		gpslna_pins_oh = "/soc/pinctrl@1000b000/gpslna@1";
		gpslna_pins_ol = "/soc/pinctrl@1000b000/gpslna@2";
		accdet_pins_default = "/soc/pinctrl@1000b000/accdetdefault";
		accdet_pins_eint_as_int = "/soc/pinctrl@1000b000/accdeteint@0";
		aud_pins_mosi_on = "/soc/pinctrl@1000b000/mosion";
		aud_pins_mosi_off = "/soc/pinctrl@1000b000/mosioff";
		aud_pins_miso_on = "/soc/pinctrl@1000b000/misoon";
		aud_pins_miso_off = "/soc/pinctrl@1000b000/misooff";
		aud_pins_default = "/soc/pinctrl@1000b000/audiodefault";
		rt551x_pins_eint_as_int = "/soc/pinctrl@1000b000/rt551x_irq_init";
		aud_pins_dmic = "/soc/pinctrl@1000b000/audiodmic";
		aud_pins_pcm = "/soc/pinctrl@1000b000/audiopcm";
		aud_pins_i2s0 = "/soc/pinctrl@1000b000/audioi2s0";
		aud_pins_i2s1 = "/soc/pinctrl@1000b000/audioi2s1";
		aud_pins_i2s2 = "/soc/pinctrl@1000b000/audioi2s2";
		aud_pins_i2s3 = "/soc/pinctrl@1000b000/audioi2s3";
		aud_pins_tdm_out = "/soc/pinctrl@1000b000/audiotdmout";
		aud_pins_tdm_in = "/soc/pinctrl@1000b000/audiotdmin";
		camera_pins_default = "/soc/pinctrl@1000b000/camdefault";
		camera_pins_cam0_rst0 = "/soc/pinctrl@1000b000/cam0@0";
		camera_pins_cam0_rst1 = "/soc/pinctrl@1000b000/cam0@1";
		camera_pins_cam0_pnd0 = "/soc/pinctrl@1000b000/cam0@2";
		camera_pins_cam0_pnd1 = "/soc/pinctrl@1000b000/cam0@3";
		camera_pins_cam1_rst0 = "/soc/pinctrl@1000b000/cam1@0";
		camera_pins_cam1_rst1 = "/soc/pinctrl@1000b000/cam1@1";
		camera_pins_cam1_pnd0 = "/soc/pinctrl@1000b000/cam1@2";
		camera_pins_cam1_pnd1 = "/soc/pinctrl@1000b000/cam1@3";
		camera_pins_cam0_mclk_on = "/soc/pinctrl@1000b000/camera_pins_cam0_mclk_on";
		camera_pins_cam0_mclk_off = "/soc/pinctrl@1000b000/camera_pins_cam0_mclk_off";
		camera_pins_cam1_mclk_on = "/soc/pinctrl@1000b000/camera_pins_cam1_mclk_on";
		camera_pins_cam1_mclk_off = "/soc/pinctrl@1000b000/camera_pins_cam1_mclk_off";
		ncp_default = "/soc/pinctrl@1000b000/ecpdefault";
		ncp3902_en_output0 = "/soc/pinctrl@1000b000/ncpoutput0";
		ncp3902_en_output1 = "/soc/pinctrl@1000b000/ncpoutput1";
		usbc_otg_en0 = "/soc/pinctrl@1000b000/otg_en0";
		usbc_otg_en1 = "/soc/pinctrl@1000b000/otg_en1";
		CTP_pins_default = "/soc/pinctrl@1000b000/eint0default";
		CTP_pins_eint_as_int = "/soc/pinctrl@1000b000/eint@0";
		CTP_pins_eint_output0 = "/soc/pinctrl@1000b000/eintoutput0";
		CTP_pins_eint_output1 = "/soc/pinctrl@1000b000/eintoutput1";
		CTP_pins_rst_output0 = "/soc/pinctrl@1000b000/rstoutput0";
		CTP_pins_rst_output1 = "/soc/pinctrl@1000b000/rstoutput1";
		lcm_pins_rst0 = "/soc/pinctrl@1000b000/lcmrstoutput0";
		lcm_pins_rst1 = "/soc/pinctrl@1000b000/lcmrstoutput1";
		lcm_pins_bl0 = "/soc/pinctrl@1000b000/bloutput0";
		lcm_pins_bl1 = "/soc/pinctrl@1000b000/bloutput1";
		dsp_uart_pin = "/soc/pinctrl@1000b000/dsp_uartdefault";
		ethernet_pins_default = "/soc/pinctrl@1000b000/ethernet";
		i2c0_pins = "/soc/pinctrl@1000b000/i2c0";
		i2c1_pins = "/soc/pinctrl@1000b000/i2c1";
		i2c2_pins = "/soc/pinctrl@1000b000/i2c2";
		i2c3_pins = "/soc/pinctrl@1000b000/i2c3";
		kpd_pins_default = "/soc/pinctrl@1000b000/kpddefault";
		mmc0_pins_default = "/soc/pinctrl@1000b000/mmc0default";
		mmc0_pins_uhs = "/soc/pinctrl@1000b000/mmc0uhs";
		mmc0_pins_sleep = "/soc/pinctrl@1000b000/mmc0sleep";
		mmc1_pins_default = "/soc/pinctrl@1000b000/mmc1default";
		mmc1_pins_uhs = "/soc/pinctrl@1000b000/mmc1uhs";
		mmc1_pins_sleep = "/soc/pinctrl@1000b000/mmc1sleep";
		spi_pins = "/soc/pinctrl@1000b000/spi@0";
		apmixedsys = "/soc/syscon@1000c000";
		fhctl = "/soc/fhctl@1000ce00";
		pwrap = "/soc/pwrap@1000d000";
		keypad = "/soc/keypad@10010000";
		mcusys = "/soc/mcusys@10200000";
		sysirq = "/soc/intpol-controller@10200a80";
		sys_cirq = "/soc/sys_cirq@10202000";
		systracker = "/soc/systracker@10208000";
		rng = "/soc/rng@1020f000";
		apdma = "/soc/dma-controller@11000280";
		spi = "/soc/spi@1100a000";
		rt551x_spi = "/soc/spi@1100a000/audio-codec@0";
		spidev0 = "/soc/spi@1100a000/spi@0";
		iommu = "/soc/m4u@10205000";
		infracfg_nao = "/soc/infracfg_nao@1020e000";
		emi = "/soc/emi@10219000";
		dramc = "/soc/dramc@1022c000";
		gce = "/soc/gce@1023c000";
		gce_mbox = "/soc/gce_mbox@1023c000";
		gce_mbox_svp = "/soc/gce_mbox_svp@1023c000";
		auxadc = "/soc/adc@11001000";
		uart0 = "/soc/uart0@11002000";
		uart1 = "/soc/uart1@11003000";
		i2c0 = "/soc/i2c@11007000";
		subpmic_pmu_mtk = "/soc/i2c@11007000/subpmic_pmu@34";
		mt6370_pmu = "/soc/i2c@11007000/subpmic_pmu@34/mt6370_pmu_dts";
		usb_type_c_mtk = "/soc/i2c@11007000/usb_type_c@4e";
		mt6370_typec = "/soc/i2c@11007000/usb_type_c@4e/type_c_port0";
		i2c1 = "/soc/i2c@11008000";
		i2c2 = "/soc/i2c@11009000";
		svs = "/soc/svs@1100b000";
		svs_cpu_little = "/soc/svs@1100b000/svs_cpu_little";
		i2c3 = "/soc/i2c@1100f000";
		rt551x = "/soc/i2c@1100f000/audio-codec@57";
		nandc = "/soc/nfi@11018000";
		bch = "/soc/ecc@11019000";
		ssusb = "/soc/usb@11201000";
		usb_host0 = "/soc/usb@11201000/xhci@11200000";
		afe = "/soc/audio-controller@11220000";
		mmc0 = "/soc/mmc@11230000";
		mmc1 = "/soc/mmc@11240000";
		mmc2 = "/soc/mmc@11250000";
		ethernet = "/soc/ethernet@112a0000";
		adsp_pcm = "/soc/adsp_pcm";
		mipi_rx_ana_csi0a = "/soc/mipi_rx_ana_csi0a@11c10000";
		mipi_rx_ana_csi0b = "/soc/mipi_rx_ana_csi0b@11c11000";
		mipi_rx_ana_csi1a = "/soc/mipi_rx_ana_csi1a@11c12000";
		mipi_rx_ana_csi1b = "/soc/mipi_rx_ana_csi1b@11c13000";
		efuse = "/soc/efuse@11c50000";
		svs_calibration = "/soc/efuse@11c50000/calib@580";
		power_leakage = "/soc/efuse@11c50000/leakage@cd4";
		u3phy0 = "/soc/usb-phy@11cc0000";
		u2port0 = "/soc/usb-phy@11cc0000/usb-phy@11cc0000";
		u2port1 = "/soc/usb-phy@11cc0000/usb-phy@11cc1000";
		mfgcfg = "/soc/syscon@13000000";
		mmsys = "/soc/syscon@14000000";
		mmsys_config = "/soc/mmsys_config@14000000";
		disp_mutex0 = "/soc/disp_mutex0@14001000";
		smi_common = "/soc/smi@14002000";
		larb0 = "/soc/larb@14003000";
		mdp_rdma0 = "/soc/mdp_rdma0@14004000";
		mdp_ccorr = "/soc/mdp_ccorr0@14005000";
		mdp_rsz0 = "/soc/mdp_rsz0@14006000";
		mdp_rsz1 = "/soc/mdp_rsz1@14007000";
		mdp_wrot1 = "/soc/mdp_wrot1@14008000";
		mdp_wrot0 = "/soc/mdp_wrot0@14009000";
		mdp_tdshp0 = "/soc/mdp_tdshp0@1400a000";
		disp_color0 = "/soc/disp_color0@1400f000";
		mdp_rdma1 = "/soc/mdp_rdma1@14017000";
		mtkfb = "/soc/mtkfb@0";
		dsi_te = "/soc/dsi_te";
		camsys = "/soc/syscon@15000000";
		ispsys = "/soc/ispsys@15000000";
		larb2 = "/soc/larb@15001000";
		fdvt = "/soc/fdvt@1500b000";
		wpe = "/soc/wpe@1500c000";
		kd_camera_hw1 = "/soc/kd_camera_hw1@15040000";
		vcu = "/soc/vcu@16000000";
		vdecsys = "/soc/syscon@16000000";
		vdec_gcon = "/soc/vdec_gcon@16000000";
		larb3 = "/soc/larb@16010000";
		venc_gcon = "/soc/venc_gcon@17000000";
		vencsys = "/soc/syscon@17000000";
		larb1 = "/soc/larb@17010000";
		wifi = "/soc/wifi@18000000";
		consys = "/soc/consys@18002000";
		vpu = "/soc/vpu@19000000";
		apu = "/soc/apu@19020000";
		mtk_edmc = "/soc/edmc@19030000";
		vpu_core0 = "/soc/vpu_core@19100000";
		adsp = "/soc/adsp@1d062000";
		ice = "/soc/ice_debug";
		led6 = "/soc/led@6";
		main_pmic = "/soc/mt-pmic";
		pmic_auxadc = "/soc/mt-pmic/mt635x-auxadc";
		mt_pmic_vs1_buck_reg = "/soc/mt-pmic/buck_regulators/buck_vs1";
		mt_pmic_vmodem_buck_reg = "/soc/mt-pmic/buck_regulators/buck_vmodem";
		mt_pmic_vcore_buck_reg = "/soc/mt-pmic/buck_regulators/buck_vcore";
		mt_pmic_vproc_buck_reg = "/soc/mt-pmic/buck_regulators/buck_vproc";
		mt_pmic_vpa_buck_reg = "/soc/mt-pmic/buck_regulators/buck_vpa";
		pmic_clock_buffer_ctrl = "/soc/mt-pmic/pmic_clock_buffer_ctrl";
		mt_pmic_vfe28_ldo_reg = "/soc/mt-pmic/ldo_regulators/ldo_vfe28";
		mt_pmic_vxo22_ldo_reg = "/soc/mt-pmic/ldo_regulators/ldo_vxo22";
		mt_pmic_vrf18_ldo_reg = "/soc/mt-pmic/ldo_regulators/ldo_vrf18";
		mt_pmic_vrf12_ldo_reg = "/soc/mt-pmic/ldo_regulators/ldo_vrf12";
		mt_pmic_vefuse_ldo_reg = "/soc/mt-pmic/ldo_regulators/ldo_vefuse";
		mt_pmic_vcn33_bt_ldo_reg = "/soc/mt-pmic/ldo_regulators/ldo_vcn33_bt";
		mt_pmic_vcn33_wifi_ldo_reg = "/soc/mt-pmic/ldo_regulators/ldo_vcn33_wifi";
		mt_pmic_vcn28_ldo_reg = "/soc/mt-pmic/ldo_regulators/ldo_vcn28";
		mt_pmic_vcn18_ldo_reg = "/soc/mt-pmic/ldo_regulators/ldo_vcn18";
		mt_pmic_vcama_ldo_reg = "/soc/mt-pmic/ldo_regulators/ldo_vcama";
		mt_pmic_vcamd_ldo_reg = "/soc/mt-pmic/ldo_regulators/ldo_vcamd";
		mt_pmic_vcamio_ldo_reg = "/soc/mt-pmic/ldo_regulators/ldo_vcamio";
		mt_pmic_vldo28_ldo_reg = "/soc/mt-pmic/ldo_regulators/ldo_vldo28";
		mt_pmic_vsram_others_ldo_reg = "/soc/mt-pmic/ldo_regulators/ldo_vsram_others";
		mt_pmic_vsram_proc_ldo_reg = "/soc/mt-pmic/ldo_regulators/ldo_vsram_proc";
		mt_pmic_vaux18_ldo_reg = "/soc/mt-pmic/ldo_regulators/ldo_vaux18";
		mt_pmic_vaud28_ldo_reg = "/soc/mt-pmic/ldo_regulators/ldo_vaud28";
		mt_pmic_vio28_ldo_reg = "/soc/mt-pmic/ldo_regulators/ldo_vio28";
		mt_pmic_vio18_ldo_reg = "/soc/mt-pmic/ldo_regulators/ldo_vio18";
		mt_pmic_vdram_ldo_reg = "/soc/mt-pmic/ldo_regulators/ldo_vdram";
		mt_pmic_vmc_ldo_reg = "/soc/mt-pmic/ldo_regulators/ldo_vmc";
		mt_pmic_vmch_ldo_reg = "/soc/mt-pmic/ldo_regulators/ldo_vmch";
		mt_pmic_vemc_ldo_reg = "/soc/mt-pmic/ldo_regulators/ldo_vemc";
		mt_pmic_vsim1_ldo_reg = "/soc/mt-pmic/ldo_regulators/ldo_vsim1";
		mt_pmic_vsim2_ldo_reg = "/soc/mt-pmic/ldo_regulators/ldo_vsim2";
		mt_pmic_vibr_ldo_reg = "/soc/mt-pmic/ldo_regulators/ldo_vibr";
		mt_pmic_vusb33_ldo_reg = "/soc/mt-pmic/ldo_regulators/ldo_vusb33";
		accdet = "/soc/accdet@";
		touch = "/soc/touch@";
		spower = "/soc/spower";
		firmware = "/firmware";
		android = "/firmware/android";
		fstab = "/firmware/android/fstab";
		odm = "/odm";
		extcon_usb = "/odm/extcon_usb_typec";
		mt_soc_codec_name = "/odm/mt_soc_codec_name";
		jd936x_inx_inx = "/odm/lcm@0";
		jd936x_kd_hsd = "/odm/lcm@1";
		jd936x_tg_boe = "/odm/lcm@2";
		sound = "/odm/sound";
		vs1_wire = "/odm/vs1_wire";
		vs1_wpc = "/odm/vs1_wpc";
		vs2_wire = "/odm/vs2_wire";
		vs2_wpc = "/odm/vs2_wpc";
	};
};
